VERSION ""

NS_ :

BS_:

BU_:

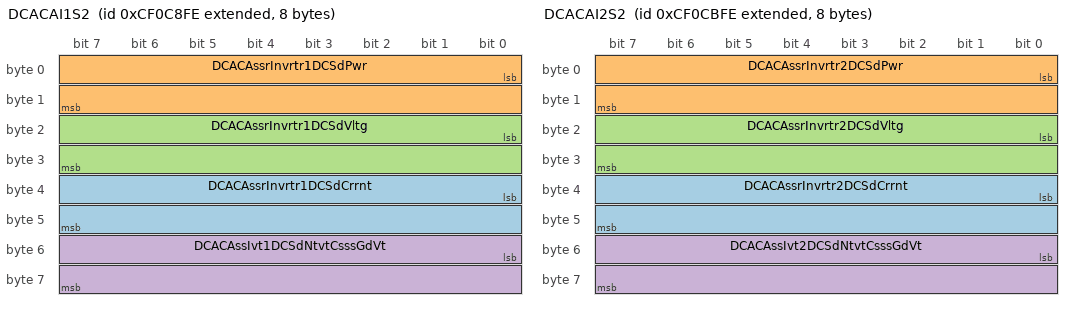
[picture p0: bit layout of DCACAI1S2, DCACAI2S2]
BO_ 2364590334 DCACAI1S2: 8 Vector__XXX
 SG_ DCACAssrInvrtr1DCSdCrrnt : 32|16@1+ (0.0625,0) [0|4015.9375] "A" Vector__XXX
 SG_ DCACAssrInvrtr1DCSdPwr : 0|16@1+ (0.0625,0) [0|4015.9375] "kW" Vector__XXX
 SG_ DCACAssrInvrtr1DCSdVltg : 16|16@1+ (0.05,0) [0|3212.75] "V" Vector__XXX
 SG_ DCACAssIvt1DCSdNtvtCsssGdVt : 48|16@1+ (0.05,0) [0|3212.75] "V" Vector__XXX

BO_ 2364590590 DCACAI1V: 8 Vector__XXX
 SG_ DCACAssrInvrtr1IgntnVltg : 0|16@1+ (0.05,0) [0|3212.75] "V" Vector__XXX
 SG_ DCACAssrInvrtr1SLIVltg : 16|16@1+ (0.05,0) [0|3212.75] "V" Vector__XXX

BO_ 2364591102 DCACAI2S2: 8 Vector__XXX
 SG_ DCACAssrInvrtr2DCSdCrrnt : 32|16@1+ (0.0625,0) [0|4015.9375] "A" Vector__XXX
 SG_ DCACAssrInvrtr2DCSdPwr : 0|16@1+ (0.0625,0) [0|4015.9375] "kW" Vector__XXX
 SG_ DCACAssrInvrtr2DCSdVltg : 16|16@1+ (0.05,0) [0|3212.75] "V" Vector__XXX
 SG_ DCACAssIvt2DCSdNtvtCsssGdVt : 48|16@1+ (0.05,0) [0|3212.75] "V" Vector__XXX

BO_ 2364591358 DCACAI2V: 8 Vector__XXX
 SG_ DCACAssrInvrtr2IgntnVltg : 0|16@1+ (0.05,0) [0|3212.75] "V" Vector__XXX
 SG_ DCACAssrInvrtr2SLIVltg : 16|16@1+ (0.05,0) [0|3212.75] "V" Vector__XXX

BO_ 2364592382 ECCR: 8 Vector__XXX
 SG_ EngnClndr10ExldfrmCmstnRqst : 26|2@1+ (1,0) [0|3] "" Vector__XXX
 SG_ EngnClndr11ExldfrmCmstnRqst : 28|2@1+ (1,0) [0|3] "" Vector__XXX
 SG_ EngnClndr12ExldfrmCmstnRqst : 30|2@1+ (1,0) [0|3] "" Vector__XXX
 SG_ EngnClndr13ExldfrmCmstnRqst : 32|2@1+ (1,0) [0|3] "" Vector__XXX
 SG_ EngnClndr14ExldfrmCmstnRqst : 34|2@1+ (1,0) [0|3] "" Vector__XXX
 SG_ EngnClndr15ExldfrmCmstnRqst : 36|2@1+ (1,0) [0|3] "" Vector__XXX
 SG_ EngnClndr16ExldfrmCmstnRqst : 38|2@1+ (1,0) [0|3] "" Vector__XXX
 SG_ EngnClndr17ExldfrmCmstnRqst : 40|2@1+ (1,0) [0|3] "" Vector__XXX
 SG_ EngnClndr18ExldfrmCmstnRqst : 42|2@1+ (1,0) [0|3] "" Vector__XXX
 SG_ EngnClndr19ExldfrmCmstnRqst : 44|2@1+ (1,0) [0|3] "" Vector__XXX
 SG_ EngnClndr1ExldfrmCmstnRqst : 8|2@1+ (1,0) [0|3] "" Vector__XXX
 SG_ EngnClndr20ExldfrmCmstnRqst : 46|2@1+ (1,0) [0|3] "" Vector__XXX
 SG_ EngnClndr21ExldfrmCmstnRqst : 48|2@1+ (1,0) [0|3] "" Vector__XXX
 SG_ EngnClndr22ExldfrmCmstnRqst : 50|2@1+ (1,0) [0|3] "" Vector__XXX
 SG_ EngnClndr23ExldfrmCmstnRqst : 52|2@1+ (1,0) [0|3] "" Vector__XXX
 SG_ EngnClndr24ExldfrmCmstnRqst : 54|2@1+ (1,0) [0|3] "" Vector__XXX
 SG_ EngnClndr2ExldfrmCmstnRqst : 10|2@1+ (1,0) [0|3] "" Vector__XXX
 SG_ EngnClndr3ExldfrmCmstnRqst : 12|2@1+ (1,0) [0|3] "" Vector__XXX
 SG_ EngnClndr4ExldfrmCmstnRqst : 14|2@1+ (1,0) [0|3] "" Vector__XXX
 SG_ EngnClndr5ExldfrmCmstnRqst : 16|2@1+ (1,0) [0|3] "" Vector__XXX
 SG_ EngnClndr6ExldfrmCmstnRqst : 18|2@1+ (1,0) [0|3] "" Vector__XXX
 SG_ EngnClndr7ExldfrmCmstnRqst : 20|2@1+ (1,0) [0|3] "" Vector__XXX
 SG_ EngnClndr8ExldfrmCmstnRqst : 22|2@1+ (1,0) [0|3] "" Vector__XXX
 SG_ EngnClndr9ExldfrmCmstnRqst : 24|2@1+ (1,0) [0|3] "" Vector__XXX
 SG_ NmrfEngnClndrstExldfrmCmstn : 0|8@1+ (1,0) [0|250] "count" Vector__XXX

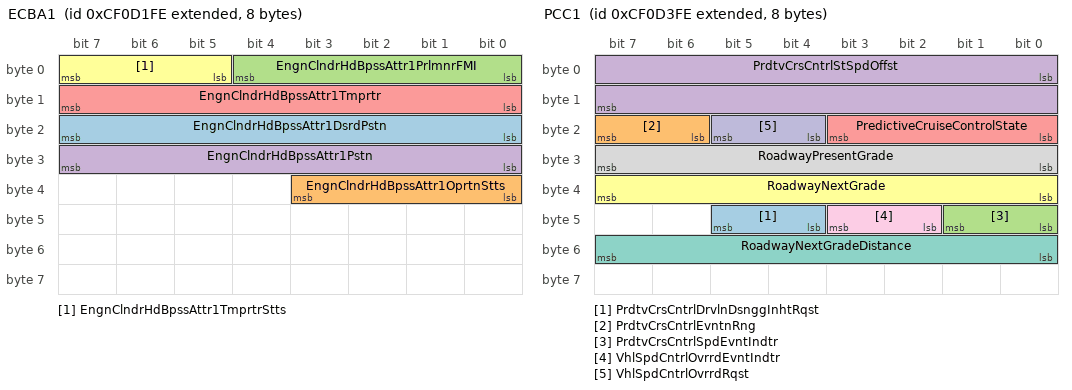
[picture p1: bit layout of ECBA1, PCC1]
BO_ 2364592638 ECBA1: 8 Vector__XXX
 SG_ EngnClndrHdBpssAttr1DsrdPstn : 16|8@1+ (0.4,0) [0|100] "%" Vector__XXX
 SG_ EngnClndrHdBpssAttr1OprtnStts : 32|4@1+ (1,0) [0|15] "" Vector__XXX
 SG_ EngnClndrHdBpssAttr1PrlmnrFMI : 0|5@1+ (1,0) [0|31] "binary" Vector__XXX
 SG_ EngnClndrHdBpssAttr1Pstn : 24|8@1+ (0.4,0) [0|100] "%" Vector__XXX
 SG_ EngnClndrHdBpssAttr1Tmprtr : 8|8@1+ (1,-40) [-40|210] "degC" Vector__XXX
 SG_ EngnClndrHdBpssAttr1TmprtrStts : 5|3@1+ (1,0) [0|7] "" Vector__XXX

BO_ 2364592894 EEC18: 8 Vector__XXX
 SG_ EngineIntakeAirSourceValve : 16|2@1+ (1,0) [0|3] "" Vector__XXX
 SG_ EngnClndrHdBpssAttr1Cmmnd : 0|16@1+ (0.0025,0) [0|160.6375] "%" Vector__XXX
 SG_ EngnExhstGsRstrtnVlvPstn : 32|16@1+ (0.0025,0) [0|160.6375] "%" Vector__XXX

BO_ 2364593150 PCC1: 8 Vector__XXX
 SG_ PrdtvCrsCntrlDrvlnDsnggInhtRqst : 44|2@1+ (1,0) [0|3] "" Vector__XXX
 SG_ PrdtvCrsCntrlEvntnRng : 22|2@1+ (1,0) [0|3] "" Vector__XXX
 SG_ PrdtvCrsCntrlSpdEvntIndtr : 40|2@1+ (1,0) [0|3] "" Vector__XXX
 SG_ PrdtvCrsCntrlStSpdOffst : 0|16@1+ (0.00390625,-125) [-125|125.996] "km/h" Vector__XXX
 SG_ PredictiveCruiseControlState : 16|4@1+ (1,0) [0|15] "" Vector__XXX
 SG_ RoadwayNextGrade : 32|8@1+ (0.125,-16) [-16|15.25] "%" Vector__XXX
 SG_ RoadwayNextGradeDistance : 48|8@1+ (25,0) [0|6250] "m" Vector__XXX
 SG_ RoadwayPresentGrade : 24|8@1+ (0.125,-16) [-16|15.25] "%" Vector__XXX
 SG_ VhlSpdCntrlOvrrdEvntIndtr : 42|2@1+ (1,0) [0|3] "" Vector__XXX
 SG_ VhlSpdCntrlOvrrdRqst : 20|2@1+ (1,0) [0|3] "" Vector__XXX

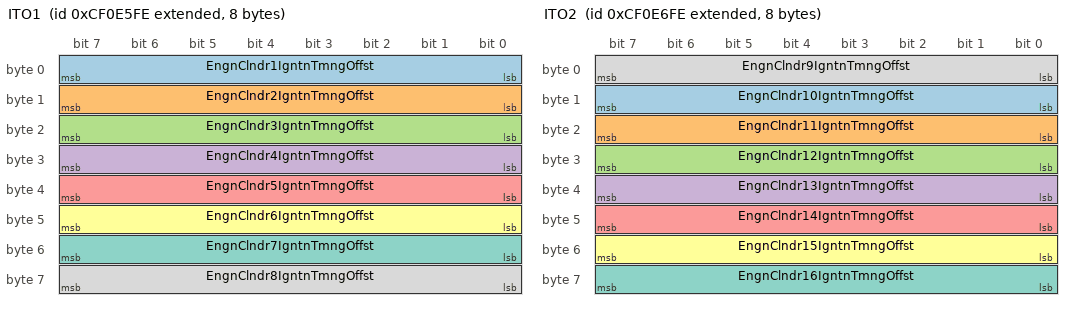
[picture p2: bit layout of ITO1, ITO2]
BO_ 2364597758 ITO1: 8 Vector__XXX
 SG_ EngnClndr1IgntnTmngOffst : 0|8@1+ (0.1,-12.5) [-12.5|12.5] "deg" Vector__XXX
 SG_ EngnClndr2IgntnTmngOffst : 8|8@1+ (0.1,-12.5) [-12.5|12.5] "deg" Vector__XXX
 SG_ EngnClndr3IgntnTmngOffst : 16|8@1+ (0.1,-12.5) [-12.5|12.5] "deg" Vector__XXX
 SG_ EngnClndr4IgntnTmngOffst : 24|8@1+ (0.1,-12.5) [-12.5|12.5] "deg" Vector__XXX
 SG_ EngnClndr5IgntnTmngOffst : 32|8@1+ (0.1,-12.5) [-12.5|12.5] "deg" Vector__XXX
 SG_ EngnClndr6IgntnTmngOffst : 40|8@1+ (0.1,-12.5) [-12.5|12.5] "deg" Vector__XXX
 SG_ EngnClndr7IgntnTmngOffst : 48|8@1+ (0.1,-12.5) [-12.5|12.5] "deg" Vector__XXX
 SG_ EngnClndr8IgntnTmngOffst : 56|8@1+ (0.1,-12.5) [-12.5|12.5] "deg" Vector__XXX

BO_ 2364598014 ITO2: 8 Vector__XXX
 SG_ EngnClndr10IgntnTmngOffst : 8|8@1+ (0.1,-12.5) [-12.5|12.5] "deg" Vector__XXX
 SG_ EngnClndr11IgntnTmngOffst : 16|8@1+ (0.1,-12.5) [-12.5|12.5] "deg" Vector__XXX
 SG_ EngnClndr12IgntnTmngOffst : 24|8@1+ (0.1,-12.5) [-12.5|12.5] "deg" Vector__XXX
 SG_ EngnClndr13IgntnTmngOffst : 32|8@1+ (0.1,-12.5) [-12.5|12.5] "deg" Vector__XXX
 SG_ EngnClndr14IgntnTmngOffst : 40|8@1+ (0.1,-12.5) [-12.5|12.5] "deg" Vector__XXX
 SG_ EngnClndr15IgntnTmngOffst : 48|8@1+ (0.1,-12.5) [-12.5|12.5] "deg" Vector__XXX
 SG_ EngnClndr16IgntnTmngOffst : 56|8@1+ (0.1,-12.5) [-12.5|12.5] "deg" Vector__XXX
 SG_ EngnClndr9IgntnTmngOffst : 0|8@1+ (0.1,-12.5) [-12.5|12.5] "deg" Vector__XXX

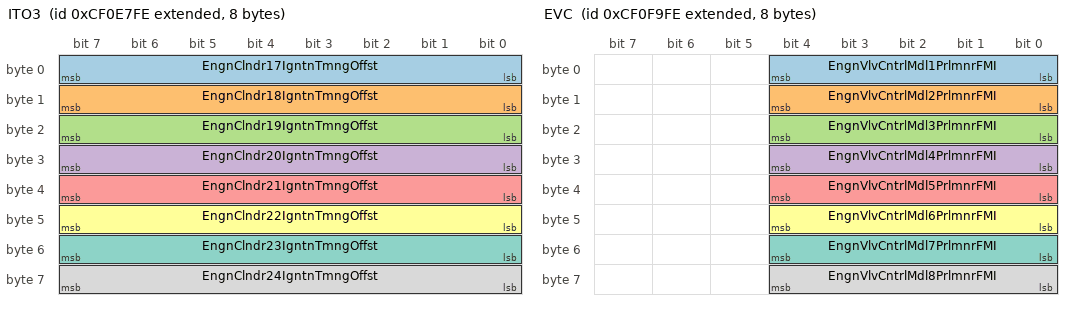
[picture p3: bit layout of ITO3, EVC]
BO_ 2364598270 ITO3: 8 Vector__XXX
 SG_ EngnClndr17IgntnTmngOffst : 0|8@1+ (0.1,-12.5) [-12.5|12.5] "deg" Vector__XXX
 SG_ EngnClndr18IgntnTmngOffst : 8|8@1+ (0.1,-12.5) [-12.5|12.5] "deg" Vector__XXX
 SG_ EngnClndr19IgntnTmngOffst : 16|8@1+ (0.1,-12.5) [-12.5|12.5] "deg" Vector__XXX
 SG_ EngnClndr20IgntnTmngOffst : 24|8@1+ (0.1,-12.5) [-12.5|12.5] "deg" Vector__XXX
 SG_ EngnClndr21IgntnTmngOffst : 32|8@1+ (0.1,-12.5) [-12.5|12.5] "deg" Vector__XXX
 SG_ EngnClndr22IgntnTmngOffst : 40|8@1+ (0.1,-12.5) [-12.5|12.5] "deg" Vector__XXX
 SG_ EngnClndr23IgntnTmngOffst : 48|8@1+ (0.1,-12.5) [-12.5|12.5] "deg" Vector__XXX
 SG_ EngnClndr24IgntnTmngOffst : 56|8@1+ (0.1,-12.5) [-12.5|12.5] "deg" Vector__XXX

BO_ 2364598526 TFAC2: 8 Vector__XXX
 SG_ EngnFlAttr3CntrlCmmnd : 32|16@1+ (0.0025,0) [0|160.6375] "%" Vector__XXX
 SG_ EngnFlAttr4CntrlCmmnd : 48|16@1+ (0.0025,0) [0|160.6375] "%" Vector__XXX

BO_ 2364602878 EVC: 8 Vector__XXX
 SG_ EngnVlvCntrlMdl1PrlmnrFMI : 0|5@1+ (1,0) [0|31] "binary" Vector__XXX
 SG_ EngnVlvCntrlMdl2PrlmnrFMI : 8|5@1+ (1,0) [0|31] "binary" Vector__XXX
 SG_ EngnVlvCntrlMdl3PrlmnrFMI : 16|5@1+ (1,0) [0|31] "binary" Vector__XXX
 SG_ EngnVlvCntrlMdl4PrlmnrFMI : 24|5@1+ (1,0) [0|31] "binary" Vector__XXX
 SG_ EngnVlvCntrlMdl5PrlmnrFMI : 32|5@1+ (1,0) [0|31] "binary" Vector__XXX
 SG_ EngnVlvCntrlMdl6PrlmnrFMI : 40|5@1+ (1,0) [0|31] "binary" Vector__XXX
 SG_ EngnVlvCntrlMdl7PrlmnrFMI : 48|5@1+ (1,0) [0|31] "binary" Vector__XXX
 SG_ EngnVlvCntrlMdl8PrlmnrFMI : 56|5@1+ (1,0) [0|31] "binary" Vector__XXX

BO_ 2364603134 ETC13: 8 Vector__XXX
 SG_ MxmmFrwrdTrnsmssnOtptShftSpd : 0|16@1+ (0.125,0) [0|8031.875] "rpm" Vector__XXX
 SG_ MxmmRvrsTrnsmssnOtptShftSpd : 16|16@1+ (0.125,0) [0|8031.875] "rpm" Vector__XXX
 SG_ SAddssAtvPdTsssRqstdG : 32|8@1+ (1,0) [0|255] "SA" Vector__XXX

BO_ 2364603390 A1SCRDSR3: 8 Vector__XXX
 SG_ Atttt1DsExstFdDsVv1Cd : 16|16@1+ (0.0025,0) [0|160.6375] "%" Vector__XXX
 SG_ Atttt1DsExstFdRqstdQttIttHRst : 0|16@1+ (0.001,0) [0|64.255] "g" Vector__XXX

BO_ 2364603646 A2SCRDSR3: 8 Vector__XXX
 SG_ Atttt2DsExstFdRqstdQttIttHRst : 0|16@1+ (0.001,0) [0|64.255] "g" Vector__XXX

BO_ 2364603902 A1SCRDSI4: 8 Vector__XXX
 SG_ Atttt1DsExstFdAtQttIttHRst : 0|16@1+ (0.001,0) [0|64.255] "g" Vector__XXX

BO_ 2364604158 A2SCRDSI4: 8 Vector__XXX
 SG_ Atttt2DsExstFdAtQttIttHRst : 0|16@1+ (0.001,0) [0|64.255] "g" Vector__XXX

BO_ 2364605438 GTRACE: 8 Vector__XXX
 SG_ GeneratorTripkVArHoursExport : 32|32@1+ (1,0) [0|4.21108E+09] "kVArh" Vector__XXX
 SG_ GeneratorTripkWHoursExport : 0|32@1+ (1,0) [0|4.21108E+09] "kWh" Vector__XXX

BO_ 2364605950 HPD: 8 Vector__XXX
 SG_ HydraulicLinePressure : 0|16@1+ (1,0) [0|64255] "kPa" Vector__XXX
 SG_ MechanicalMovementAngle : 16|16@1+ (0.0078125,0) [0|501.99] "deg" Vector__XXX

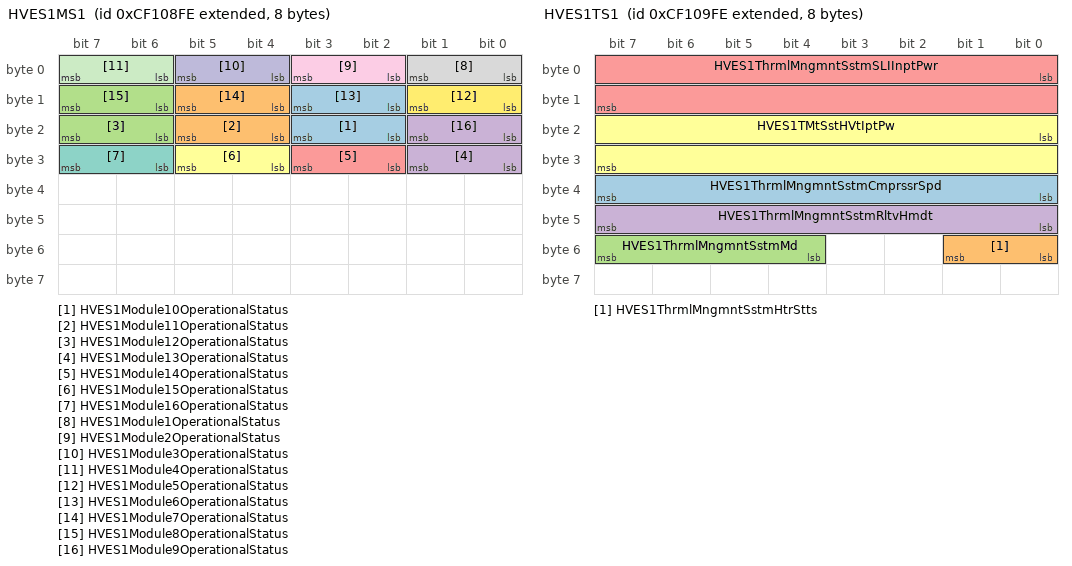
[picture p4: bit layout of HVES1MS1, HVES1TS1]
BO_ 2364606718 HVES1MS1: 8 Vector__XXX
 SG_ HVES1Module10OperationalStatus : 18|2@1+ (1,0) [0|3] "" Vector__XXX
 SG_ HVES1Module11OperationalStatus : 20|2@1+ (1,0) [0|3] "" Vector__XXX
 SG_ HVES1Module12OperationalStatus : 22|2@1+ (1,0) [0|3] "" Vector__XXX
 SG_ HVES1Module13OperationalStatus : 24|2@1+ (1,0) [0|3] "" Vector__XXX
 SG_ HVES1Module14OperationalStatus : 26|2@1+ (1,0) [0|3] "" Vector__XXX
 SG_ HVES1Module15OperationalStatus : 28|2@1+ (1,0) [0|3] "" Vector__XXX
 SG_ HVES1Module16OperationalStatus : 30|2@1+ (1,0) [0|3] "" Vector__XXX
 SG_ HVES1Module1OperationalStatus : 0|2@1+ (1,0) [0|3] "" Vector__XXX
 SG_ HVES1Module2OperationalStatus : 2|2@1+ (1,0) [0|3] "" Vector__XXX
 SG_ HVES1Module3OperationalStatus : 4|2@1+ (1,0) [0|3] "" Vector__XXX
 SG_ HVES1Module4OperationalStatus : 6|2@1+ (1,0) [0|3] "" Vector__XXX
 SG_ HVES1Module5OperationalStatus : 8|2@1+ (1,0) [0|3] "" Vector__XXX
 SG_ HVES1Module6OperationalStatus : 10|2@1+ (1,0) [0|3] "" Vector__XXX
 SG_ HVES1Module7OperationalStatus : 12|2@1+ (1,0) [0|3] "" Vector__XXX
 SG_ HVES1Module8OperationalStatus : 14|2@1+ (1,0) [0|3] "" Vector__XXX
 SG_ HVES1Module9OperationalStatus : 16|2@1+ (1,0) [0|3] "" Vector__XXX

BO_ 2364606974 HVES1TS1: 8 Vector__XXX
 SG_ HVES1ThrmlMngmntSstmCmprssrSpd : 32|8@1+ (32,0) [0|8000] "rpm" Vector__XXX
 SG_ HVES1ThrmlMngmntSstmHtrStts : 48|2@1+ (1,0) [0|3] "" Vector__XXX
 SG_ HVES1ThrmlMngmntSstmMd : 52|4@1+ (1,0) [0|15] "" Vector__XXX
 SG_ HVES1ThrmlMngmntSstmRltvHmdt : 40|8@1+ (0.4,0) [0|100] "%" Vector__XXX
 SG_ HVES1ThrmlMngmntSstmSLIInptPwr : 0|16@1+ (0.5,0) [0|32127.5] "W" Vector__XXX
 SG_ HVES1TMtSstHVtIptPw : 16|16@1+ (0.5,0) [0|32127.5] "W" Vector__XXX

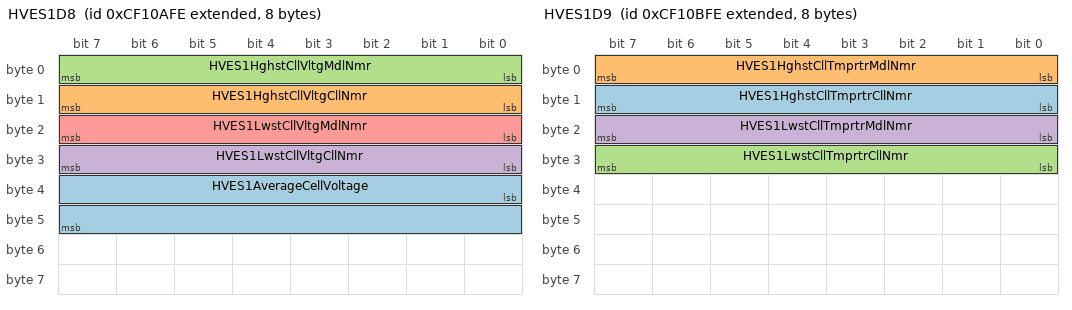
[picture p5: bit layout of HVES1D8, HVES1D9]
BO_ 2364607230 HVES1D8: 8 Vector__XXX
 SG_ HVES1AverageCellVoltage : 32|16@1+ (0.001,0) [0|64.255] "V" Vector__XXX
 SG_ HVES1HghstCllVltgCllNmr : 8|8@1+ (1,0) [0|250] "count" Vector__XXX
 SG_ HVES1HghstCllVltgMdlNmr : 0|8@1+ (1,0) [0|250] "count" Vector__XXX
 SG_ HVES1LwstCllVltgCllNmr : 24|8@1+ (1,0) [0|250] "count" Vector__XXX
 SG_ HVES1LwstCllVltgMdlNmr : 16|8@1+ (1,0) [0|250] "count" Vector__XXX

BO_ 2364607486 HVES1D9: 8 Vector__XXX
 SG_ HVES1HghstCllTmprtrCllNmr : 8|8@1+ (1,0) [0|250] "count" Vector__XXX
 SG_ HVES1HghstCllTmprtrMdlNmr : 0|8@1+ (1,0) [0|250] "count" Vector__XXX
 SG_ HVES1LwstCllTmprtrCllNmr : 24|8@1+ (1,0) [0|250] "count" Vector__XXX
 SG_ HVES1LwstCllTmprtrMdlNmr : 16|8@1+ (1,0) [0|250] "count" Vector__XXX

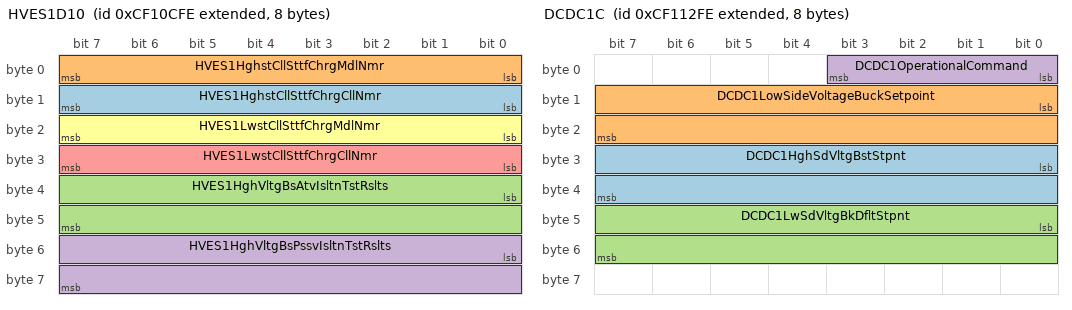
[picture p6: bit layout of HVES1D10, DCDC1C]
BO_ 2364607742 HVES1D10: 8 Vector__XXX
 SG_ HVES1HghstCllSttfChrgCllNmr : 8|8@1+ (1,0) [0|250] "count" Vector__XXX
 SG_ HVES1HghstCllSttfChrgMdlNmr : 0|8@1+ (1,0) [0|250] "count" Vector__XXX
 SG_ HVES1HghVltgBsAtvIsltnTstRslts : 32|16@1+ (0.1,0) [0|6425.5] "ohm/V" Vector__XXX
 SG_ HVES1HghVltgBsPssvIsltnTstRslts : 48|16@1+ (0.1,0) [0|6425.5] "ohm/V" Vector__XXX
 SG_ HVES1LwstCllSttfChrgCllNmr : 24|8@1+ (1,0) [0|250] "count" Vector__XXX
 SG_ HVES1LwstCllSttfChrgMdlNmr : 16|8@1+ (1,0) [0|250] "count" Vector__XXX

BO_ 2364608510 EOI2: 8 Vector__XXX
 SG_ EnginePowerDerateRequest : 16|16@1+ (0.5,0) [0|32127.5] "kW" Vector__XXX
 SG_ EngineSelfInducedDerateLoad : 0|16@1+ (0.5,0) [0|32127.5] "kW" Vector__XXX

BO_ 2364609278 DCDC1C: 8 Vector__XXX
 SG_ DCDC1HghSdVltgBstStpnt : 24|16@1+ (0.05,0) [0|3212.75] "V" Vector__XXX
 SG_ DCDC1LowSideVoltageBuckSetpoint : 8|16@1+ (0.01,0) [0|642.55] "V" Vector__XXX
 SG_ DCDC1LwSdVltgBkDfltStpnt : 40|16@1+ (0.01,0) [0|642.55] "V" Vector__XXX
 SG_ DCDC1OperationalCommand : 0|4@1+ (1,0) [0|15] "" Vector__XXX

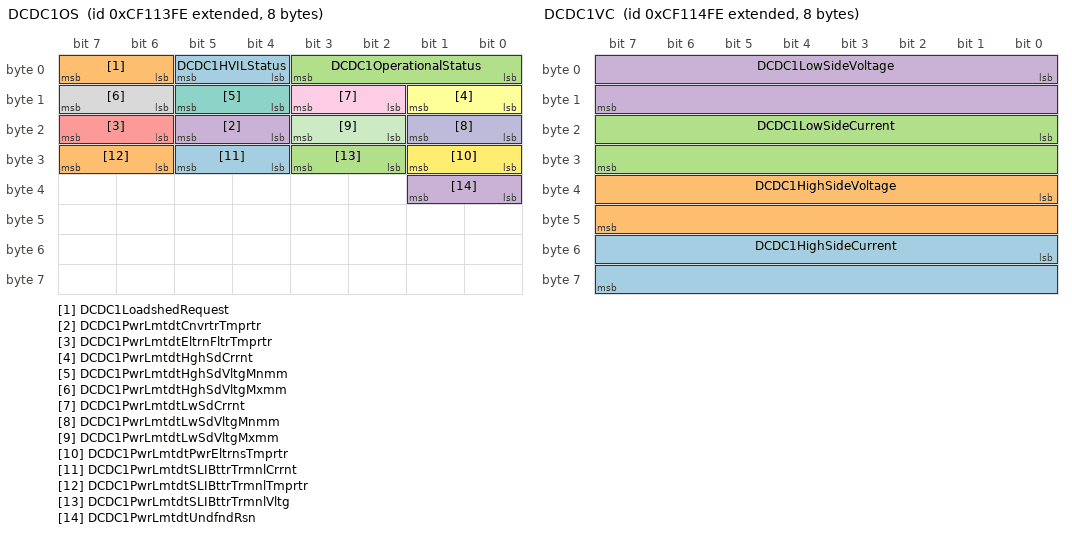
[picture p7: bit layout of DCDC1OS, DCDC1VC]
BO_ 2364609534 DCDC1OS: 8 Vector__XXX
 SG_ DCDC1HVILStatus : 4|2@1+ (1,0) [0|3] "" Vector__XXX
 SG_ DCDC1LoadshedRequest : 6|2@1+ (1,0) [0|3] "" Vector__XXX
 SG_ DCDC1OperationalStatus : 0|4@1+ (1,0) [0|15] "" Vector__XXX
 SG_ DCDC1PwrLmtdtCnvrtrTmprtr : 20|2@1+ (1,0) [0|3] "" Vector__XXX
 SG_ DCDC1PwrLmtdtEltrnFltrTmprtr : 22|2@1+ (1,0) [0|3] "" Vector__XXX
 SG_ DCDC1PwrLmtdtHghSdCrrnt : 8|2@1+ (1,0) [0|3] "" Vector__XXX
 SG_ DCDC1PwrLmtdtHghSdVltgMnmm : 12|2@1+ (1,0) [0|3] "" Vector__XXX
 SG_ DCDC1PwrLmtdtHghSdVltgMxmm : 14|2@1+ (1,0) [0|3] "" Vector__XXX
 SG_ DCDC1PwrLmtdtLwSdCrrnt : 10|2@1+ (1,0) [0|3] "" Vector__XXX
 SG_ DCDC1PwrLmtdtLwSdVltgMnmm : 16|2@1+ (1,0) [0|3] "" Vector__XXX
 SG_ DCDC1PwrLmtdtLwSdVltgMxmm : 18|2@1+ (1,0) [0|3] "" Vector__XXX
 SG_ DCDC1PwrLmtdtPwrEltrnsTmprtr : 24|2@1+ (1,0) [0|3] "" Vector__XXX
 SG_ DCDC1PwrLmtdtSLIBttrTrmnlCrrnt : 28|2@1+ (1,0) [0|3] "" Vector__XXX
 SG_ DCDC1PwrLmtdtSLIBttrTrmnlTmprtr : 30|2@1+ (1,0) [0|3] "" Vector__XXX
 SG_ DCDC1PwrLmtdtSLIBttrTrmnlVltg : 26|2@1+ (1,0) [0|3] "" Vector__XXX
 SG_ DCDC1PwrLmtdtUndfndRsn : 32|2@1+ (1,0) [0|3] "" Vector__XXX

BO_ 2364609790 DCDC1VC: 8 Vector__XXX
 SG_ DCDC1HighSideCurrent : 48|16@1+ (0.1,-3212.7) [-3212.7|3212.8] "A" Vector__XXX
 SG_ DCDC1HighSideVoltage : 32|16@1+ (0.05,0) [0|3212.75] "V" Vector__XXX
 SG_ DCDC1LowSideCurrent : 16|16@1+ (0.1,-3212.7) [-3212.7|3212.8] "A" Vector__XXX
 SG_ DCDC1LowSideVoltage : 0|16@1+ (0.01,0) [0|642.55] "V" Vector__XXX

BO_ 2364610046 DCDC1SBS: 8 Vector__XXX
 SG_ DCDC1SLIBatteryTerminalCurrent : 16|16@1+ (0.1,-3212.7) [-3212.7|3212.8] "A" Vector__XXX
 SG_ DCDC1SLIBatteryTerminalVoltage : 0|16@1+ (0.01,0) [0|642.55] "V" Vector__XXX
 SG_ DCDC1SLIBttrTrmnlTmprtr : 32|8@1+ (1,-40) [-40|210] "degC" Vector__XXX

BO_ 2364610558 DCDC1S2: 8 Vector__XXX
 SG_ DCDC1HighSidePower : 16|16@1+ (0.05,-1600) [-1600|1612.75] "kW" Vector__XXX
 SG_ DCDC1LowSidePower : 0|16@1+ (0.05,-1600) [-1600|1612.75] "kW" Vector__XXX
 SG_ DCDC1HghSdNgtvtChsssGrndVltg : 32|16@1+ (0.05,0) [0|3212.75] "V" Vector__XXX

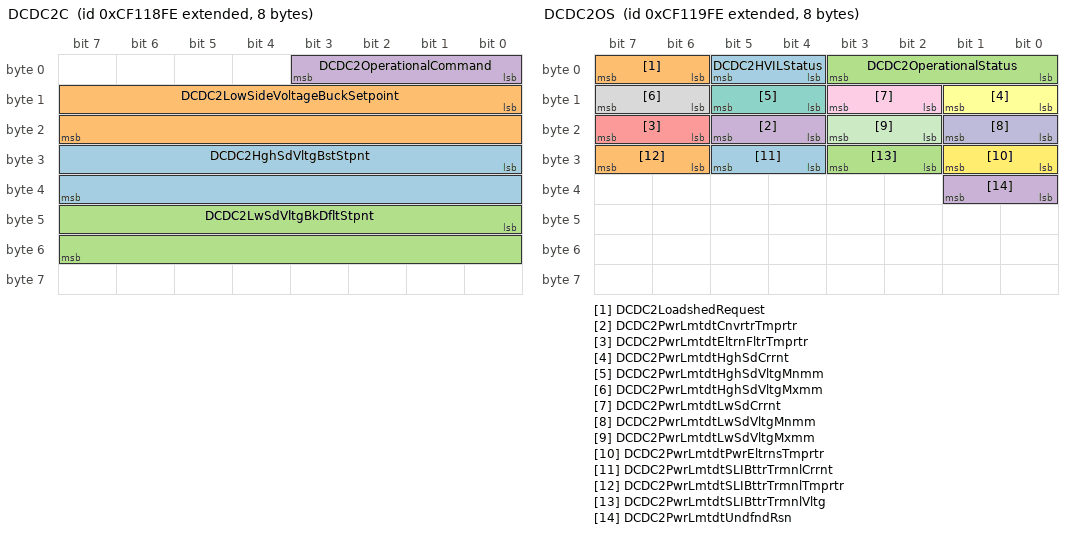
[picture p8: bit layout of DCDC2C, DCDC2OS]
BO_ 2364610814 DCDC2C: 8 Vector__XXX
 SG_ DCDC2HghSdVltgBstStpnt : 24|16@1+ (0.05,0) [0|3212.75] "V" Vector__XXX
 SG_ DCDC2LowSideVoltageBuckSetpoint : 8|16@1+ (0.01,0) [0|642.55] "V" Vector__XXX
 SG_ DCDC2LwSdVltgBkDfltStpnt : 40|16@1+ (0.01,0) [0|642.55] "V" Vector__XXX
 SG_ DCDC2OperationalCommand : 0|4@1+ (1,0) [0|15] "" Vector__XXX

BO_ 2364611070 DCDC2OS: 8 Vector__XXX
 SG_ DCDC2HVILStatus : 4|2@1+ (1,0) [0|3] "" Vector__XXX
 SG_ DCDC2LoadshedRequest : 6|2@1+ (1,0) [0|3] "" Vector__XXX
 SG_ DCDC2OperationalStatus : 0|4@1+ (1,0) [0|15] "" Vector__XXX
 SG_ DCDC2PwrLmtdtCnvrtrTmprtr : 20|2@1+ (1,0) [0|3] "" Vector__XXX
 SG_ DCDC2PwrLmtdtEltrnFltrTmprtr : 22|2@1+ (1,0) [0|3] "" Vector__XXX
 SG_ DCDC2PwrLmtdtHghSdCrrnt : 8|2@1+ (1,0) [0|3] "" Vector__XXX
 SG_ DCDC2PwrLmtdtHghSdVltgMnmm : 12|2@1+ (1,0) [0|3] "" Vector__XXX
 SG_ DCDC2PwrLmtdtHghSdVltgMxmm : 14|2@1+ (1,0) [0|3] "" Vector__XXX
 SG_ DCDC2PwrLmtdtLwSdCrrnt : 10|2@1+ (1,0) [0|3] "" Vector__XXX
 SG_ DCDC2PwrLmtdtLwSdVltgMnmm : 16|2@1+ (1,0) [0|3] "" Vector__XXX
 SG_ DCDC2PwrLmtdtLwSdVltgMxmm : 18|2@1+ (1,0) [0|3] "" Vector__XXX
 SG_ DCDC2PwrLmtdtPwrEltrnsTmprtr : 24|2@1+ (1,0) [0|3] "" Vector__XXX
 SG_ DCDC2PwrLmtdtSLIBttrTrmnlCrrnt : 28|2@1+ (1,0) [0|3] "" Vector__XXX
 SG_ DCDC2PwrLmtdtSLIBttrTrmnlTmprtr : 30|2@1+ (1,0) [0|3] "" Vector__XXX
 SG_ DCDC2PwrLmtdtSLIBttrTrmnlVltg : 26|2@1+ (1,0) [0|3] "" Vector__XXX
 SG_ DCDC2PwrLmtdtUndfndRsn : 32|2@1+ (1,0) [0|3] "" Vector__XXX

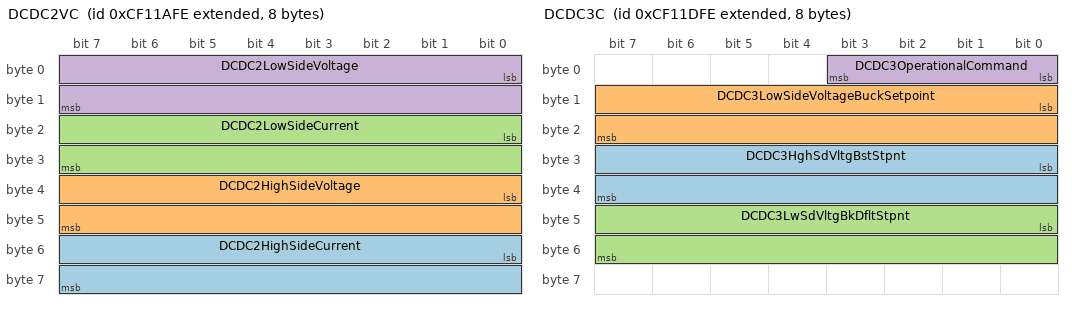
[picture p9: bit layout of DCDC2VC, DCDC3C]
BO_ 2364611326 DCDC2VC: 8 Vector__XXX
 SG_ DCDC2HighSideCurrent : 48|16@1+ (0.1,-3212.7) [-3212.7|3212.8] "A" Vector__XXX
 SG_ DCDC2HighSideVoltage : 32|16@1+ (0.05,0) [0|3212.75] "V" Vector__XXX
 SG_ DCDC2LowSideCurrent : 16|16@1+ (0.1,-3212.7) [-3212.7|3212.8] "A" Vector__XXX
 SG_ DCDC2LowSideVoltage : 0|16@1+ (0.01,0) [0|642.55] "V" Vector__XXX

BO_ 2364611582 DCDC2SBS: 8 Vector__XXX
 SG_ DCDC2SLIBatteryTerminalCurrent : 16|16@1+ (0.1,-3212.7) [-3212.7|3212.8] "A" Vector__XXX
 SG_ DCDC2SLIBatteryTerminalVoltage : 0|16@1+ (0.01,0) [0|642.55] "V" Vector__XXX
 SG_ DCDC2SLIBttrTrmnlTmprtr : 32|8@1+ (1,-40) [-40|210] "degC" Vector__XXX

BO_ 2364611838 DCDC2S2: 8 Vector__XXX
 SG_ DCDC2HighSidePower : 16|16@1+ (0.05,-1600) [-1600|1612.75] "kW" Vector__XXX
 SG_ DCDC2LowSidePower : 0|16@1+ (0.05,-1600) [-1600|1612.75] "kW" Vector__XXX
 SG_ DCDC2HghSdNgtvtChsssGrndVltg : 32|16@1+ (0.05,0) [0|3212.75] "V" Vector__XXX

BO_ 2364612094 DCDC3C: 8 Vector__XXX
 SG_ DCDC3HghSdVltgBstStpnt : 24|16@1+ (0.05,0) [0|3212.75] "V" Vector__XXX
 SG_ DCDC3LowSideVoltageBuckSetpoint : 8|16@1+ (0.01,0) [0|642.55] "V" Vector__XXX
 SG_ DCDC3LwSdVltgBkDfltStpnt : 40|16@1+ (0.01,0) [0|642.55] "V" Vector__XXX
 SG_ DCDC3OperationalCommand : 0|4@1+ (1,0) [0|15] "" Vector__XXX

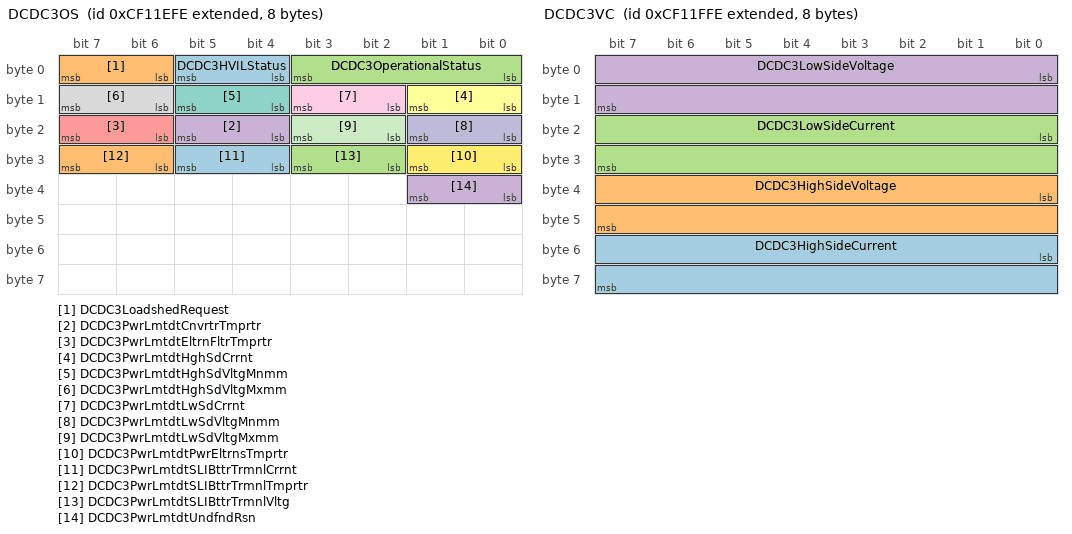
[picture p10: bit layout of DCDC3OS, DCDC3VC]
BO_ 2364612350 DCDC3OS: 8 Vector__XXX
 SG_ DCDC3HVILStatus : 4|2@1+ (1,0) [0|3] "" Vector__XXX
 SG_ DCDC3LoadshedRequest : 6|2@1+ (1,0) [0|3] "" Vector__XXX
 SG_ DCDC3OperationalStatus : 0|4@1+ (1,0) [0|15] "" Vector__XXX
 SG_ DCDC3PwrLmtdtCnvrtrTmprtr : 20|2@1+ (1,0) [0|3] "" Vector__XXX
 SG_ DCDC3PwrLmtdtEltrnFltrTmprtr : 22|2@1+ (1,0) [0|3] "" Vector__XXX
 SG_ DCDC3PwrLmtdtHghSdCrrnt : 8|2@1+ (1,0) [0|3] "" Vector__XXX
 SG_ DCDC3PwrLmtdtHghSdVltgMnmm : 12|2@1+ (1,0) [0|3] "" Vector__XXX
 SG_ DCDC3PwrLmtdtHghSdVltgMxmm : 14|2@1+ (1,0) [0|3] "" Vector__XXX
 SG_ DCDC3PwrLmtdtLwSdCrrnt : 10|2@1+ (1,0) [0|3] "" Vector__XXX
 SG_ DCDC3PwrLmtdtLwSdVltgMnmm : 16|2@1+ (1,0) [0|3] "" Vector__XXX
 SG_ DCDC3PwrLmtdtLwSdVltgMxmm : 18|2@1+ (1,0) [0|3] "" Vector__XXX
 SG_ DCDC3PwrLmtdtPwrEltrnsTmprtr : 24|2@1+ (1,0) [0|3] "" Vector__XXX
 SG_ DCDC3PwrLmtdtSLIBttrTrmnlCrrnt : 28|2@1+ (1,0) [0|3] "" Vector__XXX
 SG_ DCDC3PwrLmtdtSLIBttrTrmnlTmprtr : 30|2@1+ (1,0) [0|3] "" Vector__XXX
 SG_ DCDC3PwrLmtdtSLIBttrTrmnlVltg : 26|2@1+ (1,0) [0|3] "" Vector__XXX
 SG_ DCDC3PwrLmtdtUndfndRsn : 32|2@1+ (1,0) [0|3] "" Vector__XXX

BO_ 2364612606 DCDC3VC: 8 Vector__XXX
 SG_ DCDC3HighSideCurrent : 48|16@1+ (0.1,-3212.7) [-3212.7|3212.8] "A" Vector__XXX
 SG_ DCDC3HighSideVoltage : 32|16@1+ (0.05,0) [0|3212.75] "V" Vector__XXX
 SG_ DCDC3LowSideCurrent : 16|16@1+ (0.1,-3212.7) [-3212.7|3212.8] "A" Vector__XXX
 SG_ DCDC3LowSideVoltage : 0|16@1+ (0.01,0) [0|642.55] "V" Vector__XXX

BO_ 2364612862 DCDC3SBS: 8 Vector__XXX
 SG_ DCDC3SLIBatteryTerminalCurrent : 16|16@1+ (0.1,-3212.7) [-3212.7|3212.8] "A" Vector__XXX
 SG_ DCDC3SLIBatteryTerminalVoltage : 0|16@1+ (0.01,0) [0|642.55] "V" Vector__XXX
 SG_ DCDC3SLIBttrTrmnlTmprtr : 32|8@1+ (1,-40) [-40|210] "degC" Vector__XXX

BO_ 2364613118 DCDC3S2: 8 Vector__XXX
 SG_ DCDC3HighSidePower : 16|16@1+ (0.05,-1600) [-1600|1612.75] "kW" Vector__XXX
 SG_ DCDC3LowSidePower : 0|16@1+ (0.05,-1600) [-1600|1612.75] "kW" Vector__XXX
 SG_ DCDC3HghSdNgtvtChsssGrndVltg : 32|16@1+ (0.05,0) [0|3212.75] "V" Vector__XXX

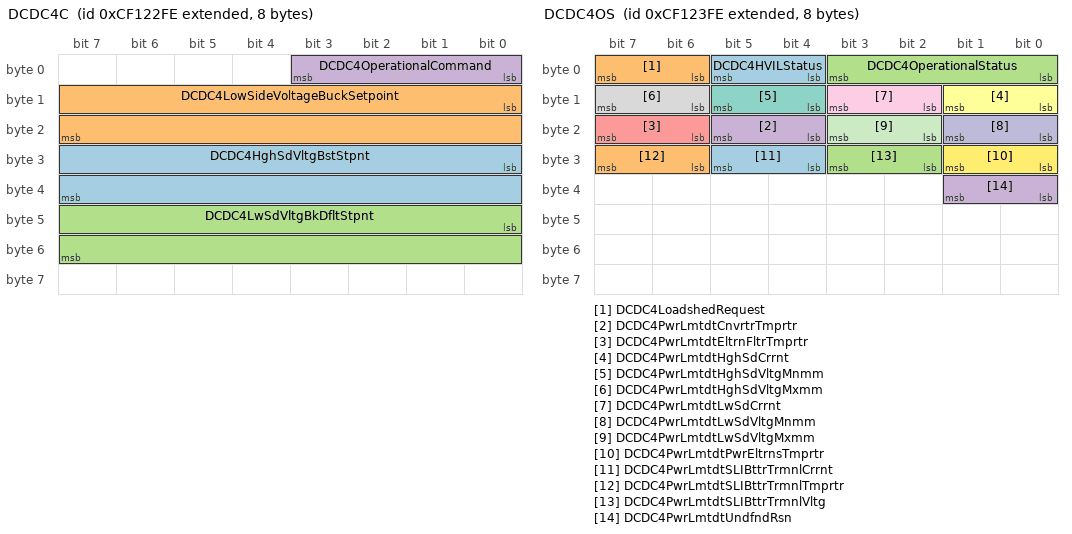
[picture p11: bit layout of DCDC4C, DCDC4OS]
BO_ 2364613374 DCDC4C: 8 Vector__XXX
 SG_ DCDC4HghSdVltgBstStpnt : 24|16@1+ (0.05,0) [0|3212.75] "V" Vector__XXX
 SG_ DCDC4LowSideVoltageBuckSetpoint : 8|16@1+ (0.01,0) [0|642.55] "V" Vector__XXX
 SG_ DCDC4LwSdVltgBkDfltStpnt : 40|16@1+ (0.01,0) [0|642.55] "V" Vector__XXX
 SG_ DCDC4OperationalCommand : 0|4@1+ (1,0) [0|15] "" Vector__XXX

BO_ 2364613630 DCDC4OS: 8 Vector__XXX
 SG_ DCDC4HVILStatus : 4|2@1+ (1,0) [0|3] "" Vector__XXX
 SG_ DCDC4LoadshedRequest : 6|2@1+ (1,0) [0|3] "" Vector__XXX
 SG_ DCDC4OperationalStatus : 0|4@1+ (1,0) [0|15] "" Vector__XXX
 SG_ DCDC4PwrLmtdtCnvrtrTmprtr : 20|2@1+ (1,0) [0|3] "" Vector__XXX
 SG_ DCDC4PwrLmtdtEltrnFltrTmprtr : 22|2@1+ (1,0) [0|3] "" Vector__XXX
 SG_ DCDC4PwrLmtdtHghSdCrrnt : 8|2@1+ (1,0) [0|3] "" Vector__XXX
 SG_ DCDC4PwrLmtdtHghSdVltgMnmm : 12|2@1+ (1,0) [0|3] "" Vector__XXX
 SG_ DCDC4PwrLmtdtHghSdVltgMxmm : 14|2@1+ (1,0) [0|3] "" Vector__XXX
 SG_ DCDC4PwrLmtdtLwSdCrrnt : 10|2@1+ (1,0) [0|3] "" Vector__XXX
 SG_ DCDC4PwrLmtdtLwSdVltgMnmm : 16|2@1+ (1,0) [0|3] "" Vector__XXX
 SG_ DCDC4PwrLmtdtLwSdVltgMxmm : 18|2@1+ (1,0) [0|3] "" Vector__XXX
 SG_ DCDC4PwrLmtdtPwrEltrnsTmprtr : 24|2@1+ (1,0) [0|3] "" Vector__XXX
 SG_ DCDC4PwrLmtdtSLIBttrTrmnlCrrnt : 28|2@1+ (1,0) [0|3] "" Vector__XXX
 SG_ DCDC4PwrLmtdtSLIBttrTrmnlTmprtr : 30|2@1+ (1,0) [0|3] "" Vector__XXX
 SG_ DCDC4PwrLmtdtSLIBttrTrmnlVltg : 26|2@1+ (1,0) [0|3] "" Vector__XXX
 SG_ DCDC4PwrLmtdtUndfndRsn : 32|2@1+ (1,0) [0|3] "" Vector__XXX

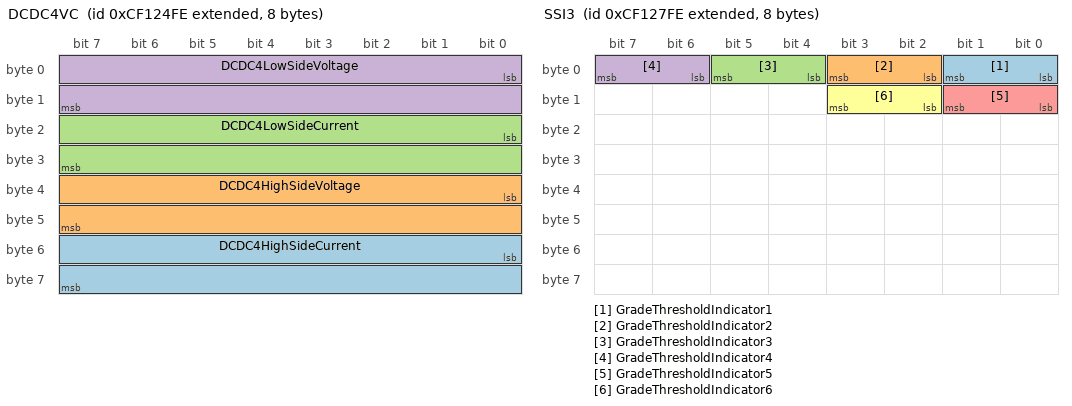
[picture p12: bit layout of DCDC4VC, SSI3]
BO_ 2364613886 DCDC4VC: 8 Vector__XXX
 SG_ DCDC4HighSideCurrent : 48|16@1+ (0.1,-3212.7) [-3212.7|3212.8] "A" Vector__XXX
 SG_ DCDC4HighSideVoltage : 32|16@1+ (0.05,0) [0|3212.75] "V" Vector__XXX
 SG_ DCDC4LowSideCurrent : 16|16@1+ (0.1,-3212.7) [-3212.7|3212.8] "A" Vector__XXX
 SG_ DCDC4LowSideVoltage : 0|16@1+ (0.01,0) [0|642.55] "V" Vector__XXX

BO_ 2364614142 DCDC4SBS: 8 Vector__XXX
 SG_ DCDC4SLIBatteryTerminalCurrent : 16|16@1+ (0.1,-3212.7) [-3212.7|3212.8] "A" Vector__XXX
 SG_ DCDC4SLIBatteryTerminalVoltage : 0|16@1+ (0.01,0) [0|642.55] "V" Vector__XXX
 SG_ DCDC4SLIBttrTrmnlTmprtr : 32|8@1+ (1,-40) [-40|210] "degC" Vector__XXX

BO_ 2364614398 DCDC4S2: 8 Vector__XXX
 SG_ DCDC4HighSidePower : 16|16@1+ (0.05,-1600) [-1600|1612.75] "kW" Vector__XXX
 SG_ DCDC4LowSidePower : 0|16@1+ (0.05,-1600) [-1600|1612.75] "kW" Vector__XXX
 SG_ DCDC4HghSdNgtvtChsssGrndVltg : 32|16@1+ (0.05,0) [0|3212.75] "V" Vector__XXX

BO_ 2364614654 SSI3: 8 Vector__XXX
 SG_ GradeThresholdIndicator1 : 0|2@1+ (1,0) [0|3] "" Vector__XXX
 SG_ GradeThresholdIndicator2 : 2|2@1+ (1,0) [0|3] "" Vector__XXX
 SG_ GradeThresholdIndicator3 : 4|2@1+ (1,0) [0|3] "" Vector__XXX
 SG_ GradeThresholdIndicator4 : 6|2@1+ (1,0) [0|3] "" Vector__XXX
 SG_ GradeThresholdIndicator5 : 8|2@1+ (1,0) [0|3] "" Vector__XXX
 SG_ GradeThresholdIndicator6 : 10|2@1+ (1,0) [0|3] "" Vector__XXX

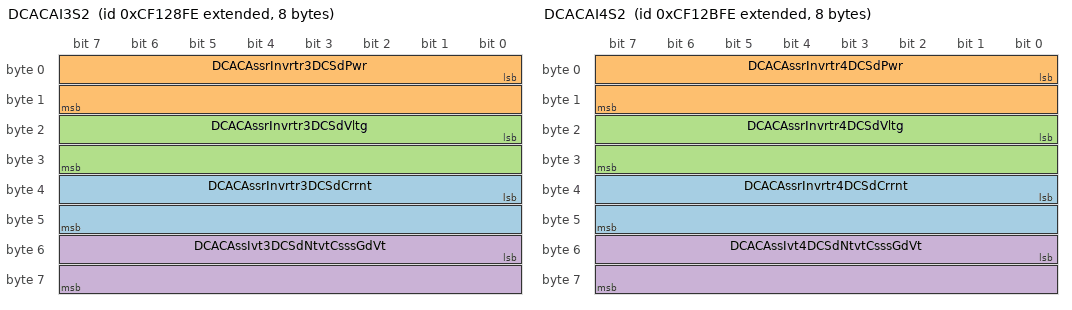
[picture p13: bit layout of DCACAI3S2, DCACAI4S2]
BO_ 2364614910 DCACAI3S2: 8 Vector__XXX
 SG_ DCACAssrInvrtr3DCSdCrrnt : 32|16@1+ (0.0625,0) [0|4015.9375] "A" Vector__XXX
 SG_ DCACAssrInvrtr3DCSdPwr : 0|16@1+ (0.0625,0) [0|4015.9375] "kW" Vector__XXX
 SG_ DCACAssrInvrtr3DCSdVltg : 16|16@1+ (0.05,0) [0|3212.75] "V" Vector__XXX
 SG_ DCACAssIvt3DCSdNtvtCsssGdVt : 48|16@1+ (0.05,0) [0|3212.75] "V" Vector__XXX

BO_ 2364615166 DCACAI3V: 8 Vector__XXX
 SG_ DCACAssrInvrtr3IgntnVltg : 0|16@1+ (0.05,0) [0|3212.75] "V" Vector__XXX
 SG_ DCACAssrInvrtr3SLIVltg : 16|16@1+ (0.05,0) [0|3212.75] "V" Vector__XXX

BO_ 2364615678 DCACAI4S2: 8 Vector__XXX
 SG_ DCACAssrInvrtr4DCSdCrrnt : 32|16@1+ (0.0625,0) [0|4015.9375] "A" Vector__XXX
 SG_ DCACAssrInvrtr4DCSdPwr : 0|16@1+ (0.0625,0) [0|4015.9375] "kW" Vector__XXX
 SG_ DCACAssrInvrtr4DCSdVltg : 16|16@1+ (0.05,0) [0|3212.75] "V" Vector__XXX
 SG_ DCACAssIvt4DCSdNtvtCsssGdVt : 48|16@1+ (0.05,0) [0|3212.75] "V" Vector__XXX

BO_ 2364615934 DCACAI4V: 8 Vector__XXX
 SG_ DCACAssrInvrtr4IgntnVltg : 0|16@1+ (0.05,0) [0|3212.75] "V" Vector__XXX
 SG_ DCACAssrInvrtr4SLIVltg : 16|16@1+ (0.05,0) [0|3212.75] "V" Vector__XXX

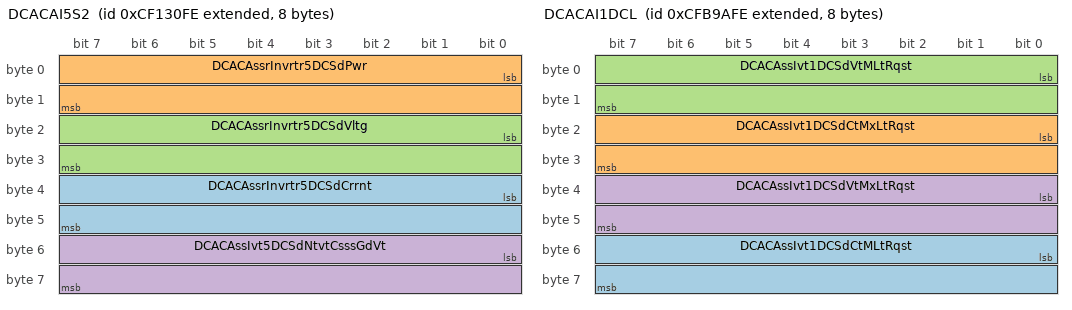
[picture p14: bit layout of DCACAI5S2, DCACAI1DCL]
BO_ 2364616958 DCACAI5S2: 8 Vector__XXX
 SG_ DCACAssrInvrtr5DCSdCrrnt : 32|16@1+ (0.0625,0) [0|4015.9375] "A" Vector__XXX
 SG_ DCACAssrInvrtr5DCSdPwr : 0|16@1+ (0.0625,0) [0|4015.9375] "kW" Vector__XXX
 SG_ DCACAssrInvrtr5DCSdVltg : 16|16@1+ (0.05,0) [0|3212.75] "V" Vector__XXX
 SG_ DCACAssIvt5DCSdNtvtCsssGdVt : 48|16@1+ (0.05,0) [0|3212.75] "V" Vector__XXX

BO_ 2364617214 DCACAI5V: 8 Vector__XXX
 SG_ DCACAssrInvrtr5IgntnVltg : 0|16@1+ (0.05,0) [0|3212.75] "V" Vector__XXX
 SG_ DCACAssrInvrtr5SLIVltg : 16|16@1+ (0.05,0) [0|3212.75] "V" Vector__XXX

BO_ 2365296894 DCDC4V: 8 Vector__XXX
 SG_ DCDC4CntrllrInptIgntnVltg : 0|16@1+ (0.05,0) [0|3212.75] "V" Vector__XXX
 SG_ DCDC4ControllerInputSLIVoltage : 16|16@1+ (0.05,0) [0|3212.75] "V" Vector__XXX

BO_ 2365297150 DCDC3V: 8 Vector__XXX
 SG_ DCDC3CntrllrInptIgntnVltg : 0|16@1+ (0.05,0) [0|3212.75] "V" Vector__XXX
 SG_ DCDC3ControllerInputSLIVoltage : 16|16@1+ (0.05,0) [0|3212.75] "V" Vector__XXX

BO_ 2365297406 DCDC2V: 8 Vector__XXX
 SG_ DCDC2CntrllrInptIgntnVltg : 0|16@1+ (0.05,0) [0|3212.75] "V" Vector__XXX
 SG_ DCDC2ControllerInputSLIVoltage : 16|16@1+ (0.05,0) [0|3212.75] "V" Vector__XXX

BO_ 2365297662 DCDC1V: 8 Vector__XXX
 SG_ DCDC1CntrllrInptIgntnVltg : 0|16@1+ (0.05,0) [0|3212.75] "V" Vector__XXX
 SG_ DCDC1ControllerInputSLIVoltage : 16|16@1+ (0.05,0) [0|3212.75] "V" Vector__XXX

BO_ 2365299454 DCACAI1DCL: 8 Vector__XXX
 SG_ DCACAssIvt1DCSdCtMLtRqst : 48|16@1+ (0.05,-3212.75) [-3212.75|0] "A" Vector__XXX
 SG_ DCACAssIvt1DCSdCtMxLtRqst : 16|16@1+ (0.05,0) [0|3212.75] "A" Vector__XXX
 SG_ DCACAssIvt1DCSdVtMLtRqst : 0|16@1+ (0.05,0) [0|3212.75] "V" Vector__XXX
 SG_ DCACAssIvt1DCSdVtMxLtRqst : 32|16@1+ (0.05,0) [0|3212.75] "V" Vector__XXX

BO_ 2365299710 DCACAI1ACL: 8 Vector__XXX
 SG_ DCACAssIvt1ACSdRMSCtMxLtRqst : 16|16@1+ (0.03125,0) [0|2007.96875] "Arms" Vector__XXX
 SG_ DCACAssIvt1ACSdRMSVtMxLtRqst : 0|16@1+ (0.03125,0) [0|2007.96875] "Vrms" Vector__XXX
 SG_ DCACAssrInvrtr1ACSdDfltFrqnRqst : 32|8@1+ (1,0) [0|250] "Hz" Vector__XXX

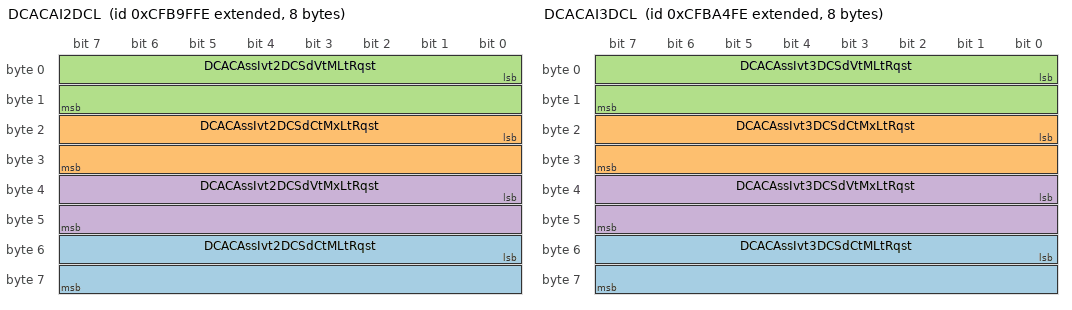
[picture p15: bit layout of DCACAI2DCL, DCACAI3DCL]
BO_ 2365300734 DCACAI2DCL: 8 Vector__XXX
 SG_ DCACAssIvt2DCSdCtMLtRqst : 48|16@1+ (0.05,-3212.75) [-3212.75|0] "A" Vector__XXX
 SG_ DCACAssIvt2DCSdCtMxLtRqst : 16|16@1+ (0.05,0) [0|3212.75] "A" Vector__XXX
 SG_ DCACAssIvt2DCSdVtMLtRqst : 0|16@1+ (0.05,0) [0|3212.75] "V" Vector__XXX
 SG_ DCACAssIvt2DCSdVtMxLtRqst : 32|16@1+ (0.05,0) [0|3212.75] "V" Vector__XXX

BO_ 2365300990 DCACAI2ACL: 8 Vector__XXX
 SG_ DCACAssIvt2ACSdRMSCtMxLtRqst : 16|16@1+ (0.03125,0) [0|2007.96875] "Arms" Vector__XXX
 SG_ DCACAssIvt2ACSdRMSVtMxLtRqst : 0|16@1+ (0.03125,0) [0|2007.96875] "Vrms" Vector__XXX
 SG_ DCACAssrInvrtr2ACSdDfltFrqnRqst : 32|8@1+ (1,0) [0|250] "Hz" Vector__XXX

BO_ 2365302014 DCACAI3DCL: 8 Vector__XXX
 SG_ DCACAssIvt3DCSdCtMLtRqst : 48|16@1+ (0.05,-3212.75) [-3212.75|0] "A" Vector__XXX
 SG_ DCACAssIvt3DCSdCtMxLtRqst : 16|16@1+ (0.05,0) [0|3212.75] "A" Vector__XXX
 SG_ DCACAssIvt3DCSdVtMLtRqst : 0|16@1+ (0.05,0) [0|3212.75] "V" Vector__XXX
 SG_ DCACAssIvt3DCSdVtMxLtRqst : 32|16@1+ (0.05,0) [0|3212.75] "V" Vector__XXX

BO_ 2365302270 DCACAI3ACL: 8 Vector__XXX
 SG_ DCACAssIvt3ACSdRMSCtMxLtRqst : 16|16@1+ (0.03125,0) [0|2007.96875] "Arms" Vector__XXX
 SG_ DCACAssIvt3ACSdRMSVtMxLtRqst : 0|16@1+ (0.03125,0) [0|2007.96875] "Vrms" Vector__XXX
 SG_ DCACAssrInvrtr3ACSdDfltFrqnRqst : 32|8@1+ (1,0) [0|250] "Hz" Vector__XXX

BO_ 2365303294 DCACAI4DCL: 8 Vector__XXX
 SG_ DCACAssIvt4DCSdCtMLtRqst : 48|16@1+ (0.05,-3212.75) [-3212.75|0] "A" Vector__XXX
 SG_ DCACAssIvt4DCSdCtMxLtRqst : 16|16@1+ (0.05,0) [0|3212.75] "A" Vector__XXX
 SG_ DCACAssIvt4DCSdVtMLtRqst : 0|16@1+ (0.05,0) [0|3212.75] "V" Vector__XXX
 SG_ DCACAssIvt4DCSdVtMxLtRqst : 32|16@1+ (0.05,0) [0|3212.75] "V" Vector__XXX

BO_ 2365303550 DCACAI4ACL: 8 Vector__XXX
 SG_ DCACAssIvt4ACSdRMSCtMxLtRqst : 16|16@1+ (0.03125,0) [0|2007.96875] "Arms" Vector__XXX
 SG_ DCACAssIvt4ACSdRMSVtMxLtRqst : 0|16@1+ (0.03125,0) [0|2007.96875] "Vrms" Vector__XXX
 SG_ DCACAssrInvrtr4ACSdDfltFrqnRqst : 32|8@1+ (1,0) [0|250] "Hz" Vector__XXX

BO_ 2365304574 DCACAI5DCL: 8 Vector__XXX
 SG_ DCACAssIvt5DCSdCtMLtRqst : 48|16@1+ (0.05,-3212.75) [-3212.75|0] "A" Vector__XXX
 SG_ DCACAssIvt5DCSdCtMxLtRqst : 16|16@1+ (0.05,0) [0|3212.75] "A" Vector__XXX
 SG_ DCACAssIvt5DCSdVtMLtRqst : 0|16@1+ (0.05,0) [0|3212.75] "V" Vector__XXX
 SG_ DCACAssIvt5DCSdVtMxLtRqst : 32|16@1+ (0.05,0) [0|3212.75] "V" Vector__XXX

BO_ 2365304830 DCACAI5ACL: 8 Vector__XXX
 SG_ DCACAssIvt5ACSdRMSCtMxLtRqst : 16|16@1+ (0.03125,0) [0|2007.96875] "Arms" Vector__XXX
 SG_ DCACAssIvt5ACSdRMSVtMxLtRqst : 0|16@1+ (0.03125,0) [0|2007.96875] "Vrms" Vector__XXX
 SG_ DCACAssrInvrtr5ACSdDfltFrqnRqst : 32|8@1+ (1,0) [0|250] "Hz" Vector__XXX

BO_ 2365307646 DCDC4SBL: 8 Vector__XXX
 SG_ DCDC4SLIBttrTmprtrMxmmLmtRqst : 32|8@1+ (1,-40) [-40|210] "degC" Vector__XXX
 SG_ DCDC4SLIBttTCCtMxLtRqst : 16|16@1+ (0.05,0) [0|3212.75] "A" Vector__XXX
 SG_ DCDC4SLIBttTVtMxLtRqst : 0|16@1+ (0.01,0) [0|642.55] "V" Vector__XXX

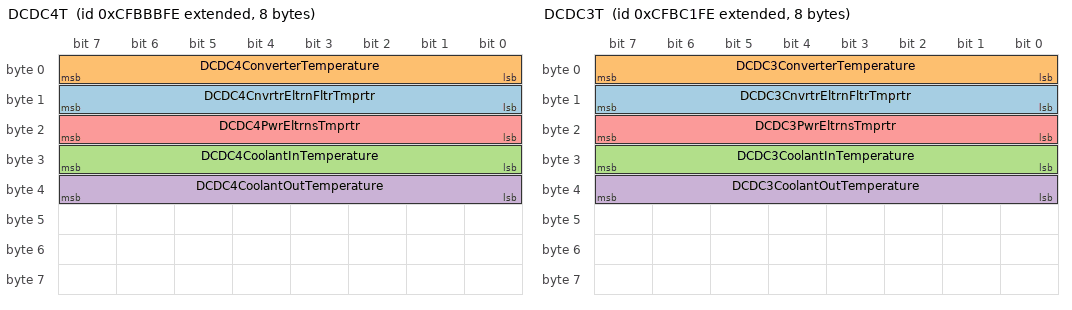
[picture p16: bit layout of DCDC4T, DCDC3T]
BO_ 2365307902 DCDC4T: 8 Vector__XXX
 SG_ DCDC4CnvrtrEltrnFltrTmprtr : 8|8@1+ (1,-40) [-40|210] "degC" Vector__XXX
 SG_ DCDC4ConverterTemperature : 0|8@1+ (1,-40) [-40|210] "degC" Vector__XXX
 SG_ DCDC4CoolantInTemperature : 24|8@1+ (1,-40) [-40|210] "degC" Vector__XXX
 SG_ DCDC4CoolantOutTemperature : 32|8@1+ (1,-40) [-40|210] "degC" Vector__XXX
 SG_ DCDC4PwrEltrnsTmprtr : 16|8@1+ (1,-40) [-40|210] "degC" Vector__XXX

BO_ 2365308158 DCDC4LL: 8 Vector__XXX
 SG_ DCDC4LwSdCrrntMxmmLmtRqst : 32|16@1+ (0.05,0) [0|3212.75] "A" Vector__XXX
 SG_ DCDC4LwSdVltgMnmmLmtRqst : 0|16@1+ (0.01,0) [0|642.55] "V" Vector__XXX
 SG_ DCDC4LwSdVltgMxmmLmtRqst : 16|16@1+ (0.01,0) [0|642.55] "V" Vector__XXX

BO_ 2365308414 DCDC4HL: 8 Vector__XXX
 SG_ DCDC4HghSdCrrntMxmmLmtRqst : 32|16@1+ (0.05,0) [0|3212.75] "A" Vector__XXX
 SG_ DCDC4HghSdVltgMnmmLmtRqst : 0|16@1+ (0.05,0) [0|3212.75] "V" Vector__XXX
 SG_ DCDC4HghSdVltgMxmmLmtRqst : 16|16@1+ (0.05,0) [0|3212.75] "V" Vector__XXX

BO_ 2365309182 DCDC3SBL: 8 Vector__XXX
 SG_ DCDC3SLIBttrTmprtrMxmmLmtRqst : 32|8@1+ (1,-40) [-40|210] "degC" Vector__XXX
 SG_ DCDC3SLIBttTCCtMxLtRqst : 16|16@1+ (0.05,0) [0|3212.75] "A" Vector__XXX
 SG_ DCDC3SLIBttTVtMxLtRqst : 0|16@1+ (0.01,0) [0|642.55] "V" Vector__XXX

BO_ 2365309438 DCDC3T: 8 Vector__XXX
 SG_ DCDC3CnvrtrEltrnFltrTmprtr : 8|8@1+ (1,-40) [-40|210] "degC" Vector__XXX
 SG_ DCDC3ConverterTemperature : 0|8@1+ (1,-40) [-40|210] "degC" Vector__XXX
 SG_ DCDC3CoolantInTemperature : 24|8@1+ (1,-40) [-40|210] "degC" Vector__XXX
 SG_ DCDC3CoolantOutTemperature : 32|8@1+ (1,-40) [-40|210] "degC" Vector__XXX
 SG_ DCDC3PwrEltrnsTmprtr : 16|8@1+ (1,-40) [-40|210] "degC" Vector__XXX

BO_ 2365309694 DCDC3LL: 8 Vector__XXX
 SG_ DCDC3LwSdCrrntMxmmLmtRqst : 32|16@1+ (0.05,0) [0|3212.75] "A" Vector__XXX
 SG_ DCDC3LwSdVltgMnmmLmtRqst : 0|16@1+ (0.01,0) [0|642.55] "V" Vector__XXX
 SG_ DCDC3LwSdVltgMxmmLmtRqst : 16|16@1+ (0.01,0) [0|642.55] "V" Vector__XXX

BO_ 2365309950 DCDC3HL: 8 Vector__XXX
 SG_ DCDC3HghSdCrrntMxmmLmtRqst : 32|16@1+ (0.05,0) [0|3212.75] "A" Vector__XXX
 SG_ DCDC3HghSdVltgMnmmLmtRqst : 0|16@1+ (0.05,0) [0|3212.75] "V" Vector__XXX
 SG_ DCDC3HghSdVltgMxmmLmtRqst : 16|16@1+ (0.05,0) [0|3212.75] "V" Vector__XXX

BO_ 2365310718 DCDC2SBL: 8 Vector__XXX
 SG_ DCDC2SLIBttrTmprtrMxmmLmtRqst : 32|8@1+ (1,-40) [-40|210] "degC" Vector__XXX
 SG_ DCDC2SLIBttTCCtMxLtRqst : 16|16@1+ (0.05,0) [0|3212.75] "A" Vector__XXX
 SG_ DCDC2SLIBttTVtMxLtRqst : 0|16@1+ (0.01,0) [0|642.55] "V" Vector__XXX

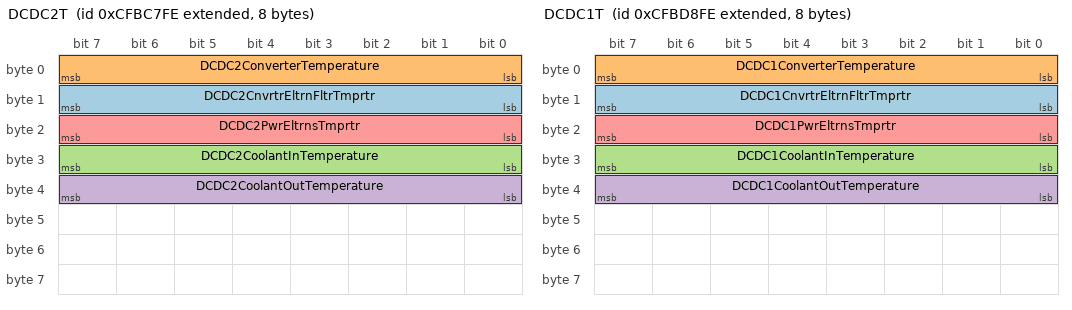
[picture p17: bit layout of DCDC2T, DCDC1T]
BO_ 2365310974 DCDC2T: 8 Vector__XXX
 SG_ DCDC2CnvrtrEltrnFltrTmprtr : 8|8@1+ (1,-40) [-40|210] "degC" Vector__XXX
 SG_ DCDC2ConverterTemperature : 0|8@1+ (1,-40) [-40|210] "degC" Vector__XXX
 SG_ DCDC2CoolantInTemperature : 24|8@1+ (1,-40) [-40|210] "degC" Vector__XXX
 SG_ DCDC2CoolantOutTemperature : 32|8@1+ (1,-40) [-40|210] "degC" Vector__XXX
 SG_ DCDC2PwrEltrnsTmprtr : 16|8@1+ (1,-40) [-40|210] "degC" Vector__XXX

BO_ 2365311230 DCDC2LL: 8 Vector__XXX
 SG_ DCDC2LwSdCrrntMxmmLmtRqst : 32|16@1+ (0.05,0) [0|3212.75] "A" Vector__XXX
 SG_ DCDC2LwSdVltgMnmmLmtRqst : 0|16@1+ (0.01,0) [0|642.55] "V" Vector__XXX
 SG_ DCDC2LwSdVltgMxmmLmtRqst : 16|16@1+ (0.01,0) [0|642.55] "V" Vector__XXX

BO_ 2365311486 DCDC2HL: 8 Vector__XXX
 SG_ DCDC2HghSdCrrntMxmmLmtRqst : 32|16@1+ (0.05,0) [0|3212.75] "A" Vector__XXX
 SG_ DCDC2HghSdVltgMnmmLmtRqst : 0|16@1+ (0.05,0) [0|3212.75] "V" Vector__XXX
 SG_ DCDC2HghSdVltgMxmmLmtRqst : 16|16@1+ (0.05,0) [0|3212.75] "V" Vector__XXX

BO_ 2365313534 DCDC1SBL: 8 Vector__XXX
 SG_ DCDC1SLIBttrTmprtrMxmmLmtRqst : 32|8@1+ (1,-40) [-40|210] "degC" Vector__XXX
 SG_ DCDC1SLIBttTCCtMxLtRqst : 16|16@1+ (0.05,0) [0|3212.75] "A" Vector__XXX
 SG_ DCDC1SLIBttTVtMxLtRqst : 0|16@1+ (0.01,0) [0|642.55] "V" Vector__XXX

BO_ 2365315326 DCDC1T: 8 Vector__XXX
 SG_ DCDC1CnvrtrEltrnFltrTmprtr : 8|8@1+ (1,-40) [-40|210] "degC" Vector__XXX
 SG_ DCDC1ConverterTemperature : 0|8@1+ (1,-40) [-40|210] "degC" Vector__XXX
 SG_ DCDC1CoolantInTemperature : 24|8@1+ (1,-40) [-40|210] "degC" Vector__XXX
 SG_ DCDC1CoolantOutTemperature : 32|8@1+ (1,-40) [-40|210] "degC" Vector__XXX
 SG_ DCDC1PwrEltrnsTmprtr : 16|8@1+ (1,-40) [-40|210] "degC" Vector__XXX

BO_ 2365315582 DCDC1LL: 8 Vector__XXX
 SG_ DCDC1LwSdCrrntMxmmLmtRqst : 32|16@1+ (0.05,0) [0|3212.75] "A" Vector__XXX
 SG_ DCDC1LwSdVltgMnmmLmtRqst : 0|16@1+ (0.01,0) [0|642.55] "V" Vector__XXX
 SG_ DCDC1LwSdVltgMxmmLmtRqst : 16|16@1+ (0.01,0) [0|642.55] "V" Vector__XXX

BO_ 2365315838 DCDC1HL: 8 Vector__XXX
 SG_ DCDC1HghSdCrrntMxmmLmtRqst : 32|16@1+ (0.05,0) [0|3212.75] "A" Vector__XXX
 SG_ DCDC1HghSdVltgMnmmLmtRqst : 0|16@1+ (0.05,0) [0|3212.75] "V" Vector__XXX
 SG_ DCDC1HghSdVltgMxmmLmtRqst : 16|16@1+ (0.05,0) [0|3212.75] "V" Vector__XXX

BO_ 2365318910 HVESFC: 8 Vector__XXX
 SG_ HVESFanEnableCommand : 0|2@1+ (1,0) [0|3] "" Vector__XXX
 SG_ HVESFanInstance1 : 32|1@1+ (1,0) [0|1] "" Vector__XXX
 SG_ HVESFanInstance10 : 41|1@1+ (1,0) [0|1] "" Vector__XXX
 SG_ HVESFanInstance11 : 42|1@1+ (1,0) [0|1] "" Vector__XXX
 SG_ HVESFanInstance12 : 43|1@1+ (1,0) [0|1] "" Vector__XXX
 SG_ HVESFanInstance13 : 44|1@1+ (1,0) [0|1] "" Vector__XXX
 SG_ HVESFanInstance14 : 45|1@1+ (1,0) [0|1] "" Vector__XXX
 SG_ HVESFanInstance15 : 46|1@1+ (1,0) [0|1] "" Vector__XXX
 SG_ HVESFanInstance2 : 33|1@1+ (1,0) [0|1] "" Vector__XXX
 SG_ HVESFanInstance3 : 34|1@1+ (1,0) [0|1] "" Vector__XXX
 SG_ HVESFanInstance4 : 35|1@1+ (1,0) [0|1] "" Vector__XXX
 SG_ HVESFanInstance5 : 36|1@1+ (1,0) [0|1] "" Vector__XXX
 SG_ HVESFanInstance6 : 37|1@1+ (1,0) [0|1] "" Vector__XXX
 SG_ HVESFanInstance7 : 38|1@1+ (1,0) [0|1] "" Vector__XXX
 SG_ HVESFanInstance8 : 39|1@1+ (1,0) [0|1] "" Vector__XXX
 SG_ HVESFanInstance9 : 40|1@1+ (1,0) [0|1] "" Vector__XXX
 SG_ HVESFanPercentSpeedCommand : 24|8@1+ (0.4,0) [0|100] "%" Vector__XXX
 SG_ HVESFanPowerHold : 2|2@1+ (1,0) [0|3] "" Vector__XXX
 SG_ HVESFanSpeedCommand : 8|16@1+ (0.5,0) [0|32127.5] "rpm" Vector__XXX

BO_ 2365322238 CCVS5: 8 Vector__XXX
 SG_ DirectionalVehicleSpeed : 0|16@1+ (0.0078125,-250) [-250|251.992] "km/h" Vector__XXX

BO_ 2365346302 ASC7: 8 Vector__XXX
 SG_ LiftAxle1Status : 0|3@1+ (1,0) [0|7] "" Vector__XXX
 SG_ LiftAxle2Status : 3|3@1+ (1,0) [0|7] "" Vector__XXX

BO_ 2365348350 ELS: 8 Vector__XXX
 SG_ EngineLoadShareStatus : 2|4@1+ (1,0) [0|15] "" Vector__XXX
 SG_ EngineUnloadStatus : 0|2@1+ (1,0) [0|3] "" Vector__XXX

BO_ 2365363710 ECPMSI: 8 Vector__XXX
 SG_ EngnClndrPrssrMntr1PrlmnrFMI : 0|5@1+ (1,0) [0|31] "binary" Vector__XXX
 SG_ EngnClndrPrssrMntr2PrlmnrFMI : 8|5@1+ (1,0) [0|31] "binary" Vector__XXX

BO_ 2365374206 ETC9: 8 Vector__XXX
 SG_ DlClthTrnsmssnCrrntPrsltnGr : 40|8@1+ (1,-125) [-125|125] "gear value" Vector__XXX
 SG_ DlClthTrnsmssnInptShft1Spd : 0|16@1+ (0.125,0) [0|8031.875] "rpm" Vector__XXX
 SG_ DlClthTrnsmssnInptShft2Spd : 16|16@1+ (0.125,0) [0|8031.875] "rpm" Vector__XXX
 SG_ DlClthTrnsmssnSltdPrsltnGr : 32|8@1+ (1,-125) [-125|125] "gear value" Vector__XXX

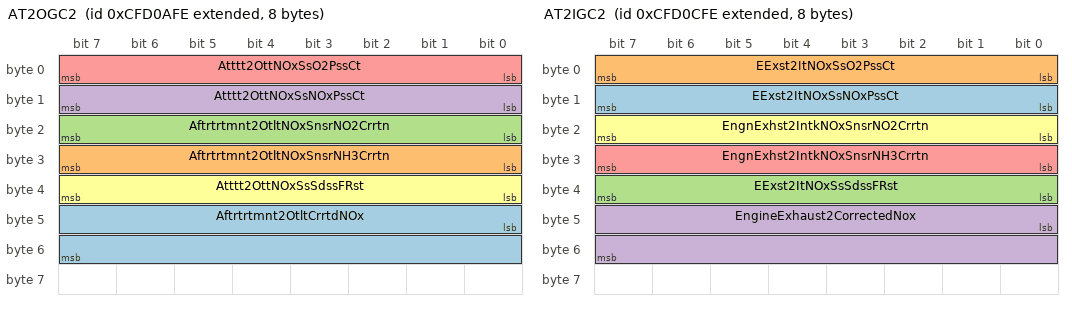
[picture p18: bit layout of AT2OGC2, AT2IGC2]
BO_ 2365393662 AT2OGC2: 8 Vector__XXX
 SG_ Aftrtrtmnt2OtltCrrtdNOx : 40|16@1+ (0.05,-200) [-200|3012.75] "ppm" Vector__XXX
 SG_ Aftrtrtmnt2OtltNOxSnsrNH3Crrtn : 24|8@1+ (0.5,0) [0|125] "%" Vector__XXX
 SG_ Aftrtrtmnt2OtltNOxSnsrNO2Crrtn : 16|8@1+ (0.5,0) [0|125] "%" Vector__XXX
 SG_ Atttt2OttNOxSsNOxPssCt : 8|8@1+ (0.5,0) [0|125] "%/bar" Vector__XXX
 SG_ Atttt2OttNOxSsO2PssCt : 0|8@1+ (0.5,0) [0|125] "%/bar" Vector__XXX
 SG_ Atttt2OttNOxSsSdssFRst : 32|8@1+ (1,0) [0|250] "Ratio" Vector__XXX

BO_ 2365393918 AT2OGC1: 8 Vector__XXX
 SG_ Aftrtrtmnt2OtltNOxSnsrHtrRt : 0|16@1+ (0.001,0) [0|64.255] "Ratio" Vector__XXX
 SG_ Aftrtrtmnt2OtltNOxSnsrOprtnHrs : 40|16@1+ (1,0) [0|64255] "h" Vector__XXX
 SG_ Atttt2OttNOxSsNwptdvtNOxG : 16|16@1+ (0.1,-100) [-100|6325.5] "%" Vector__XXX
 SG_ Atttt2OttNOxSsNwptdvtNOxOst : 32|8@1+ (1,-125) [-125|125] "ppm" Vector__XXX

BO_ 2365394174 AT2IGC2: 8 Vector__XXX
 SG_ EExst2ItNOxSsNOxPssCt : 8|8@1+ (0.5,0) [0|125] "%/bar" Vector__XXX
 SG_ EExst2ItNOxSsO2PssCt : 0|8@1+ (0.5,0) [0|125] "%/bar" Vector__XXX
 SG_ EExst2ItNOxSsSdssFRst : 32|8@1+ (1,0) [0|250] "Ratio" Vector__XXX
 SG_ EngineExhaust2CorrectedNox : 40|16@1+ (0.05,-200) [-200|3012.75] "ppm" Vector__XXX
 SG_ EngnExhst2IntkNOxSnsrNH3Crrtn : 24|8@1+ (0.5,0) [0|125] "%" Vector__XXX
 SG_ EngnExhst2IntkNOxSnsrNO2Crrtn : 16|8@1+ (0.5,0) [0|125] "%" Vector__XXX

BO_ 2365394430 AT2IGC1: 8 Vector__XXX
 SG_ EExst2ItNOxSsNwptdvtNOxG : 16|16@1+ (0.1,-100) [-100|6325.5] "%" Vector__XXX
 SG_ EExst2ItNOxSsNwptdvtNOxOst : 32|8@1+ (1,-125) [-125|125] "ppm" Vector__XXX
 SG_ EngnExhst2IntkNOxSnsrHtrRt : 0|16@1+ (0.001,0) [0|64.255] "Ratio" Vector__XXX
 SG_ EngnExhst2IntkNOxSnsrOprtnHrs : 40|16@1+ (1,0) [0|64255] "h" Vector__XXX

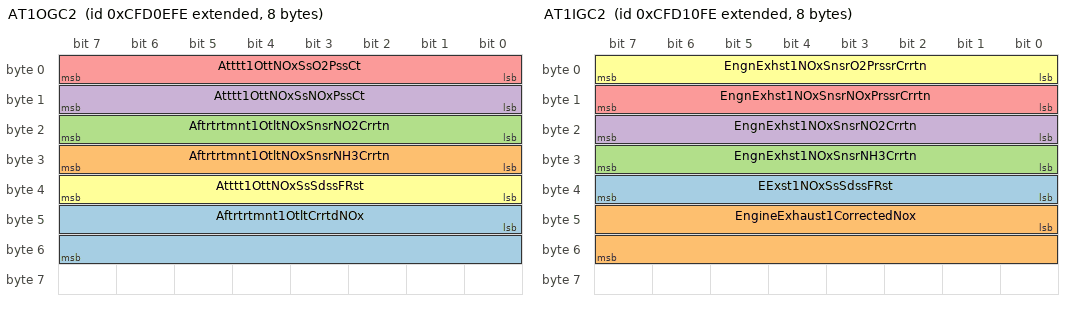
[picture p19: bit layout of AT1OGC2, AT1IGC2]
BO_ 2365394686 AT1OGC2: 8 Vector__XXX
 SG_ Aftrtrtmnt1OtltCrrtdNOx : 40|16@1+ (0.05,-200) [-200|3012.75] "ppm" Vector__XXX
 SG_ Aftrtrtmnt1OtltNOxSnsrNH3Crrtn : 24|8@1+ (0.5,0) [0|125] "%" Vector__XXX
 SG_ Aftrtrtmnt1OtltNOxSnsrNO2Crrtn : 16|8@1+ (0.5,0) [0|125] "%" Vector__XXX
 SG_ Atttt1OttNOxSsNOxPssCt : 8|8@1+ (0.5,0) [0|125] "%/bar" Vector__XXX
 SG_ Atttt1OttNOxSsO2PssCt : 0|8@1+ (0.5,0) [0|125] "%/bar" Vector__XXX
 SG_ Atttt1OttNOxSsSdssFRst : 32|8@1+ (1,0) [0|250] "Ratio" Vector__XXX

BO_ 2365394942 AT1OGC1: 8 Vector__XXX
 SG_ Aftrtrtmnt1OtltNOxSnsrHtrRt : 0|16@1+ (0.001,0) [0|64.255] "Ratio" Vector__XXX
 SG_ Aftrtrtmnt1OtltNOxSnsrOprtnHrs : 40|16@1+ (1,0) [0|64255] "h" Vector__XXX
 SG_ Atttt1OttNOxSsNwptdvtNOxG : 16|16@1+ (0.1,-100) [-100|6325.5] "%" Vector__XXX
 SG_ Atttt1OttNOxSsNwptdvtNOxOst : 32|8@1+ (1,-125) [-125|125] "ppm" Vector__XXX

BO_ 2365395198 AT1IGC2: 8 Vector__XXX
 SG_ EExst1NOxSsSdssFRst : 32|8@1+ (1,0) [0|250] "Ratio" Vector__XXX
 SG_ EngineExhaust1CorrectedNox : 40|16@1+ (0.05,-200) [-200|3012.75] "ppm" Vector__XXX
 SG_ EngnExhst1NOxSnsrNH3Crrtn : 24|8@1+ (0.5,0) [0|125] "%" Vector__XXX
 SG_ EngnExhst1NOxSnsrNO2Crrtn : 16|8@1+ (0.5,0) [0|125] "%" Vector__XXX
 SG_ EngnExhst1NOxSnsrNOxPrssrCrrtn : 8|8@1+ (0.5,0) [0|125] "%/bar" Vector__XXX
 SG_ EngnExhst1NOxSnsrO2PrssrCrrtn : 0|8@1+ (0.5,0) [0|125] "%/bar" Vector__XXX

BO_ 2365395454 AT1IGC1: 8 Vector__XXX
 SG_ EExst1NOxSsNwptdvtNOxOst : 32|8@1+ (1,-125) [-125|125] "ppm" Vector__XXX
 SG_ EngnExhst1NOxSnsrHtrRt : 0|16@1+ (0.001,0) [0|64.255] "Ratio" Vector__XXX
 SG_ EngnExhst1NOxSnsrNwprtdvtnNOxGn : 16|16@1+ (0.1,-100) [-100|6325.5] "%" Vector__XXX
 SG_ EngnExhst1NOxSnsrOprtnHrs : 40|16@1+ (1,0) [0|64255] "h" Vector__XXX

BO_ 2365400062 EJM10: 8 Vector__XXX
 SG_ Joystick10Button13PressedStatus : 62|2@1+ (1,0) [0|3] "" Vector__XXX
 SG_ Joystick10Button14PressedStatus : 60|2@1+ (1,0) [0|3] "" Vector__XXX
 SG_ Joystick10Button15PressedStatus : 58|2@1+ (1,0) [0|3] "" Vector__XXX
 SG_ Joystick10Button16PressedStatus : 56|2@1+ (1,0) [0|3] "" Vector__XXX
 SG_ Joystick10GripXAxisPosition : 6|10@1+ (0.1,0) [0|102] "%" Vector__XXX
 SG_ Joystick10GripYAxisPosition : 22|10@1+ (0.1,0) [0|102] "%" Vector__XXX
 SG_ Joystick10ThetaAxisPosition : 38|10@1+ (0.1,0) [0|102] "%" Vector__XXX
 SG_ Jst10GpXAxsLvRtPstvPstStts : 4|2@1+ (1,0) [0|3] "" Vector__XXX
 SG_ Jst10GpYAxsLvFwdPstvPstStts : 20|2@1+ (1,0) [0|3] "" Vector__XXX
 SG_ Jst10TtAxsCtCwsNtvPstStts : 34|2@1+ (1,0) [0|3] "" Vector__XXX
 SG_ Jstk10GrpXAxsDtntPstnStts : 54|2@1+ (1,0) [0|3] "" Vector__XXX
 SG_ Jstk10GrpXAxsLvrLftNgtvPstnStts : 2|2@1+ (1,0) [0|3] "" Vector__XXX
 SG_ Jstk10GrpXAxsNtrlPstnStts : 0|2@1+ (1,0) [0|3] "" Vector__XXX
 SG_ Jstk10GrpYAxsDtntPstnStts : 52|2@1+ (1,0) [0|3] "" Vector__XXX
 SG_ Jstk10GrpYAxsLvrBkNgtvPstnStts : 18|2@1+ (1,0) [0|3] "" Vector__XXX
 SG_ Jstk10GrpYAxsNtrlPstnStts : 16|2@1+ (1,0) [0|3] "" Vector__XXX
 SG_ Jstk10ThtAxsClkwsPstvPstnStts : 36|2@1+ (1,0) [0|3] "" Vector__XXX
 SG_ Jstk10ThtAxsDtntPstnStts : 50|2@1+ (1,0) [0|3] "" Vector__XXX
 SG_ Jstk10ThtAxsNtrlPstnStts : 32|2@1+ (1,0) [0|3] "" Vector__XXX

BO_ 2365400318 BJM10: 8 Vector__XXX
 SG_ Joystick10Button10PressedStatus : 60|2@1+ (1,0) [0|3] "" Vector__XXX
 SG_ Joystick10Button11PressedStatus : 58|2@1+ (1,0) [0|3] "" Vector__XXX
 SG_ Joystick10Button12PressedStatus : 56|2@1+ (1,0) [0|3] "" Vector__XXX
 SG_ Joystick10Button1PressedStatus : 46|2@1+ (1,0) [0|3] "" Vector__XXX
 SG_ Joystick10Button2PressedStatus : 44|2@1+ (1,0) [0|3] "" Vector__XXX
 SG_ Joystick10Button3PressedStatus : 42|2@1+ (1,0) [0|3] "" Vector__XXX
 SG_ Joystick10Button4PressedStatus : 40|2@1+ (1,0) [0|3] "" Vector__XXX
 SG_ Joystick10Button5PressedStatus : 54|2@1+ (1,0) [0|3] "" Vector__XXX
 SG_ Joystick10Button6PressedStatus : 52|2@1+ (1,0) [0|3] "" Vector__XXX
 SG_ Joystick10Button7PressedStatus : 50|2@1+ (1,0) [0|3] "" Vector__XXX
 SG_ Joystick10Button8PressedStatus : 48|2@1+ (1,0) [0|3] "" Vector__XXX
 SG_ Joystick10Button9PressedStatus : 62|2@1+ (1,0) [0|3] "" Vector__XXX
 SG_ Joystick10XAxisPosition : 6|10@1+ (0.1,0) [0|102] "%" Vector__XXX
 SG_ Joystick10YAxisPosition : 22|10@1+ (0.1,0) [0|102] "%" Vector__XXX
 SG_ Jstk10XAxsDtntPstnStts : 38|2@1+ (1,0) [0|3] "" Vector__XXX
 SG_ Jstk10XAxsLvrLftNgtvPstnStts : 2|2@1+ (1,0) [0|3] "" Vector__XXX
 SG_ Jstk10XAxsLvrRghtPstvPstnStts : 4|2@1+ (1,0) [0|3] "" Vector__XXX
 SG_ Jstk10XAxsNtrlPstnStts : 0|2@1+ (1,0) [0|3] "" Vector__XXX
 SG_ Jstk10YAxsDtntPstnStts : 36|2@1+ (1,0) [0|3] "" Vector__XXX
 SG_ Jstk10YAxsLvrBkNgtvPstnStts : 18|2@1+ (1,0) [0|3] "" Vector__XXX
 SG_ Jstk10YAxsLvrFrwrdPstvPstnStts : 20|2@1+ (1,0) [0|3] "" Vector__XXX
 SG_ Jstk10YAxsNtrlPstnStts : 16|2@1+ (1,0) [0|3] "" Vector__XXX

BO_ 2365400574 EJM9: 8 Vector__XXX
 SG_ Joystick9Button13PressedStatus : 62|2@1+ (1,0) [0|3] "" Vector__XXX
 SG_ Joystick9Button14PressedStatus : 60|2@1+ (1,0) [0|3] "" Vector__XXX
 SG_ Joystick9Button15PressedStatus : 58|2@1+ (1,0) [0|3] "" Vector__XXX
 SG_ Joystick9Button16PressedStatus : 56|2@1+ (1,0) [0|3] "" Vector__XXX
 SG_ Joystick9GripXAxisPosition : 6|10@1+ (0.1,0) [0|102] "%" Vector__XXX
 SG_ Joystick9GripYAxisPosition : 22|10@1+ (0.1,0) [0|102] "%" Vector__XXX
 SG_ Joystick9ThetaAxisPosition : 38|10@1+ (0.1,0) [0|102] "%" Vector__XXX
 SG_ Jst9GpYAxsLvFwdPstvPstStts : 20|2@1+ (1,0) [0|3] "" Vector__XXX
 SG_ Jst9TtAxsCtCwsNtvPstStts : 34|2@1+ (1,0) [0|3] "" Vector__XXX
 SG_ Jstk9GrpXAxsDtntPstnStts : 54|2@1+ (1,0) [0|3] "" Vector__XXX
 SG_ Jstk9GrpXAxsLvrLftNgtvPstnStts : 2|2@1+ (1,0) [0|3] "" Vector__XXX
 SG_ Jstk9GrpXAxsLvrRghtPstvPstnStts : 4|2@1+ (1,0) [0|3] "" Vector__XXX
 SG_ Jstk9GrpXAxsNtrlPstnStts : 0|2@1+ (1,0) [0|3] "" Vector__XXX
 SG_ Jstk9GrpYAxsDtntPstnStts : 52|2@1+ (1,0) [0|3] "" Vector__XXX
 SG_ Jstk9GrpYAxsLvrBkNgtvPstnStts : 18|2@1+ (1,0) [0|3] "" Vector__XXX
 SG_ Jstk9GrpYAxsNtrlPstnStts : 16|2@1+ (1,0) [0|3] "" Vector__XXX
 SG_ Jstk9ThtAxsClkwsPstvPstnStts : 36|2@1+ (1,0) [0|3] "" Vector__XXX
 SG_ Jstk9ThtAxsDtntPstnStts : 50|2@1+ (1,0) [0|3] "" Vector__XXX
 SG_ Jstk9ThtAxsNtrlPstnStts : 32|2@1+ (1,0) [0|3] "" Vector__XXX

BO_ 2365400830 BJM9: 8 Vector__XXX
 SG_ Joystick9Button10PressedStatus : 60|2@1+ (1,0) [0|3] "" Vector__XXX
 SG_ Joystick9Button11PressedStatus : 58|2@1+ (1,0) [0|3] "" Vector__XXX
 SG_ Joystick9Button12PressedStatus : 56|2@1+ (1,0) [0|3] "" Vector__XXX
 SG_ Joystick9Button1PressedStatus : 46|2@1+ (1,0) [0|3] "" Vector__XXX
 SG_ Joystick9Button2PressedStatus : 44|2@1+ (1,0) [0|3] "" Vector__XXX
 SG_ Joystick9Button3PressedStatus : 42|2@1+ (1,0) [0|3] "" Vector__XXX
 SG_ Joystick9Button4PressedStatus : 40|2@1+ (1,0) [0|3] "" Vector__XXX
 SG_ Joystick9Button5PressedStatus : 54|2@1+ (1,0) [0|3] "" Vector__XXX
 SG_ Joystick9Button6PressedStatus : 52|2@1+ (1,0) [0|3] "" Vector__XXX
 SG_ Joystick9Button7PressedStatus : 50|2@1+ (1,0) [0|3] "" Vector__XXX
 SG_ Joystick9Button8PressedStatus : 48|2@1+ (1,0) [0|3] "" Vector__XXX
 SG_ Joystick9Button9PressedStatus : 62|2@1+ (1,0) [0|3] "" Vector__XXX
 SG_ Joystick9XAxisPosition : 6|10@1+ (0.1,0) [0|102] "%" Vector__XXX
 SG_ Joystick9YAxisPosition : 22|10@1+ (0.1,0) [0|102] "%" Vector__XXX
 SG_ Jstk9XAxsDtntPstnStts : 38|2@1+ (1,0) [0|3] "" Vector__XXX
 SG_ Jstk9XAxsLvrLftNgtvPstnStts : 2|2@1+ (1,0) [0|3] "" Vector__XXX
 SG_ Jstk9XAxsLvrRghtPstvPstnStts : 4|2@1+ (1,0) [0|3] "" Vector__XXX
 SG_ Jstk9XAxsNtrlPstnStts : 0|2@1+ (1,0) [0|3] "" Vector__XXX
 SG_ Jstk9YAxsDtntPstnStts : 36|2@1+ (1,0) [0|3] "" Vector__XXX
 SG_ Jstk9YAxsLvrBkNgtvPstnStts : 18|2@1+ (1,0) [0|3] "" Vector__XXX
 SG_ Jstk9YAxsLvrFrwrdPstvPstnStts : 20|2@1+ (1,0) [0|3] "" Vector__XXX
 SG_ Jstk9YAxsNtrlPstnStts : 16|2@1+ (1,0) [0|3] "" Vector__XXX

BO_ 2365401086 EJM8: 8 Vector__XXX
 SG_ Joystick8Button13PressedStatus : 62|2@1+ (1,0) [0|3] "" Vector__XXX
 SG_ Joystick8Button14PressedStatus : 60|2@1+ (1,0) [0|3] "" Vector__XXX
 SG_ Joystick8Button15PressedStatus : 58|2@1+ (1,0) [0|3] "" Vector__XXX
 SG_ Joystick8Button16PressedStatus : 56|2@1+ (1,0) [0|3] "" Vector__XXX
 SG_ Joystick8GripXAxisPosition : 6|10@1+ (0.1,0) [0|102] "%" Vector__XXX
 SG_ Joystick8GripYAxisPosition : 22|10@1+ (0.1,0) [0|102] "%" Vector__XXX
 SG_ Joystick8ThetaAxisPosition : 38|10@1+ (0.1,0) [0|102] "%" Vector__XXX
 SG_ Jst8GpYAxsLvFwdPstvPstStts : 20|2@1+ (1,0) [0|3] "" Vector__XXX
 SG_ Jst8TtAxsCtCwsNtvPstStts : 34|2@1+ (1,0) [0|3] "" Vector__XXX
 SG_ Jstk8GrpXAxsDtntPstnStts : 54|2@1+ (1,0) [0|3] "" Vector__XXX
 SG_ Jstk8GrpXAxsLvrLftNgtvPstnStts : 2|2@1+ (1,0) [0|3] "" Vector__XXX
 SG_ Jstk8GrpXAxsLvrRghtPstvPstnStts : 4|2@1+ (1,0) [0|3] "" Vector__XXX
 SG_ Jstk8GrpXAxsNtrlPstnStts : 0|2@1+ (1,0) [0|3] "" Vector__XXX
 SG_ Jstk8GrpYAxsDtntPstnStts : 52|2@1+ (1,0) [0|3] "" Vector__XXX
 SG_ Jstk8GrpYAxsLvrBkNgtvPstnStts : 18|2@1+ (1,0) [0|3] "" Vector__XXX
 SG_ Jstk8GrpYAxsNtrlPstnStts : 16|2@1+ (1,0) [0|3] "" Vector__XXX
 SG_ Jstk8ThtAxsClkwsPstvPstnStts : 36|2@1+ (1,0) [0|3] "" Vector__XXX
 SG_ Jstk8ThtAxsDtntPstnStts : 50|2@1+ (1,0) [0|3] "" Vector__XXX
 SG_ Jstk8ThtAxsNtrlPstnStts : 32|2@1+ (1,0) [0|3] "" Vector__XXX

BO_ 2365401342 BJM8: 8 Vector__XXX
 SG_ Joystick8Button10PressedStatus : 60|2@1+ (1,0) [0|3] "" Vector__XXX
 SG_ Joystick8Button11PressedStatus : 58|2@1+ (1,0) [0|3] "" Vector__XXX
 SG_ Joystick8Button12PressedStatus : 56|2@1+ (1,0) [0|3] "" Vector__XXX
 SG_ Joystick8Button1PressedStatus : 46|2@1+ (1,0) [0|3] "" Vector__XXX
 SG_ Joystick8Button2PressedStatus : 44|2@1+ (1,0) [0|3] "" Vector__XXX
 SG_ Joystick8Button3PressedStatus : 42|2@1+ (1,0) [0|3] "" Vector__XXX
 SG_ Joystick8Button4PressedStatus : 40|2@1+ (1,0) [0|3] "" Vector__XXX
 SG_ Joystick8Button5PressedStatus : 54|2@1+ (1,0) [0|3] "" Vector__XXX
 SG_ Joystick8Button6PressedStatus : 52|2@1+ (1,0) [0|3] "" Vector__XXX
 SG_ Joystick8Button7PressedStatus : 50|2@1+ (1,0) [0|3] "" Vector__XXX
 SG_ Joystick8Button8PressedStatus : 48|2@1+ (1,0) [0|3] "" Vector__XXX
 SG_ Joystick8Button9PressedStatus : 62|2@1+ (1,0) [0|3] "" Vector__XXX
 SG_ Joystick8XAxisPosition : 6|10@1+ (0.1,0) [0|102] "%" Vector__XXX
 SG_ Joystick8YAxisPosition : 22|10@1+ (0.1,0) [0|102] "%" Vector__XXX
 SG_ Jstk8XAxsDtntPstnStts : 38|2@1+ (1,0) [0|3] "" Vector__XXX
 SG_ Jstk8XAxsLvrLftNgtvPstnStts : 2|2@1+ (1,0) [0|3] "" Vector__XXX
 SG_ Jstk8XAxsLvrRghtPstvPstnStts : 4|2@1+ (1,0) [0|3] "" Vector__XXX
 SG_ Jstk8XAxsNtrlPstnStts : 0|2@1+ (1,0) [0|3] "" Vector__XXX
 SG_ Jstk8YAxsDtntPstnStts : 36|2@1+ (1,0) [0|3] "" Vector__XXX
 SG_ Jstk8YAxsLvrBkNgtvPstnStts : 18|2@1+ (1,0) [0|3] "" Vector__XXX
 SG_ Jstk8YAxsLvrFrwrdPstvPstnStts : 20|2@1+ (1,0) [0|3] "" Vector__XXX
 SG_ Jstk8YAxsNtrlPstnStts : 16|2@1+ (1,0) [0|3] "" Vector__XXX

CM_ BO_ 2364590334 "DC/AC Accessory Inverter 1 Status 2";
CM_ SG_ 2364590334 DCACAssrInvrtr1DCSdCrrnt "DC Side input current measured at the point of control inside the DC/AC Accessory Inverter.…";
CM_ SG_ 2364590334 DCACAssrInvrtr1DCSdPwr "Power measured at the DC Side input to the DC/AC Accessory Inverter. …";
CM_ SG_ 2364590334 DCACAssrInvrtr1DCSdVltg "DC Side input voltage measured at the point of control inside the DC/AC Accessory Inverter.…";
CM_ SG_ 2364590334 DCACAssIvt1DCSdNtvtCsssGdVt "The voltage level of the high voltage DC side, as measured by the DC/AC between the negative side of the High Voltage DC Side input and the chassis of the DC/AC…";
CM_ BO_ 2364590590 "DC/AC Accessory Inverter 1 Voltage";
CM_ SG_ 2364590590 DCACAssrInvrtr1IgntnVltg "Ignition voltage supplied to the  DC/AC Accessory Inverter controller.…";
CM_ SG_ 2364590590 DCACAssrInvrtr1SLIVltg "Low voltage (SLI) supplied to the DC/AC Accessory Inverter controller.…";
CM_ BO_ 2364591102 "DC/AC Accessory Inverter 2 Status 2";
CM_ SG_ 2364591102 DCACAssrInvrtr2DCSdCrrnt "DC Side input current measured at the point of control inside the DC/AC Accessory Inverter.…";
CM_ SG_ 2364591102 DCACAssrInvrtr2DCSdPwr "Power measured at the DC Side input to the DC/AC Accessory Inverter. …";
CM_ SG_ 2364591102 DCACAssrInvrtr2DCSdVltg "DC Side input voltage measured at the point of control inside the DC/AC Accessory Inverter.…";
CM_ SG_ 2364591102 DCACAssIvt2DCSdNtvtCsssGdVt "The voltage level of the high voltage DC side, as measured by the DC/AC between the negative side of the High Voltage DC Side input and the chassis of the DC/AC…";
CM_ BO_ 2364591358 "DC/AC Accessory Inverter 2 Voltage";
CM_ SG_ 2364591358 DCACAssrInvrtr2IgntnVltg "Ignition voltage supplied to the  DC/AC Accessory Inverter controller.…";
CM_ SG_ 2364591358 DCACAssrInvrtr2SLIVltg "Low voltage (SLI) supplied to the DC/AC Accessory Inverter controller.…";
CM_ BO_ 2364592382 "Engine Cylinder Combustion Request";
CM_ SG_ 2364592382 EngnClndr10ExldfrmCmstnRqst "Request to the engine ECU to exclude (skip or cut-out) cylinder 10 from combustion.00b = Exclude from Combustion01b = Include for Combustion10b = Reserved11b = …";
CM_ SG_ 2364592382 EngnClndr11ExldfrmCmstnRqst "Request to the engine ECU to exclude (skip or cut-out) cylinder 11 from combustion.00b = Exclude from Combustion01b = Include for Combustion10b = Reserved11b = …";
CM_ SG_ 2364592382 EngnClndr12ExldfrmCmstnRqst "Request to the engine ECU to exclude (skip or cut-out) cylinder 12 from combustion.00b = Exclude from Combustion01b = Include for Combustion10b = Reserved11b = …";
CM_ SG_ 2364592382 EngnClndr13ExldfrmCmstnRqst "Request to the engine ECU to exclude (skip or cut-out) cylinder 13 from combustion.00b = Exclude from Combustion01b = Include for Combustion10b = Reserved11b = …";
CM_ SG_ 2364592382 EngnClndr14ExldfrmCmstnRqst "Request to the engine ECU to exclude (skip or cut-out) cylinder 14 from combustion.00b = Exclude from Combustion01b = Include for Combustion10b = Reserved11b = …";
CM_ SG_ 2364592382 EngnClndr15ExldfrmCmstnRqst "Request to the engine ECU to exclude (skip or cut-out) cylinder 15 from combustion.00b = Exclude from Combustion01b = Include for Combustion10b = Reserved11b = …";
CM_ SG_ 2364592382 EngnClndr16ExldfrmCmstnRqst "Request to the engine ECU to exclude (skip or cut-out) cylinder 16 from combustion.00b = Exclude from Combustion01b = Include for Combustion10b = Reserved11b = …";
CM_ SG_ 2364592382 EngnClndr17ExldfrmCmstnRqst "Request to the engine ECU to exclude (skip or cut-out) cylinder 17 from combustion.00b = Exclude from Combustion01b = Include for Combustion10b = Reserved11b = …";
CM_ SG_ 2364592382 EngnClndr18ExldfrmCmstnRqst "Request to the engine ECU to exclude (skip or cut-out) cylinder 18 from combustion.00b = Exclude from Combustion01b = Include for Combustion10b = Reserved11b = …";
CM_ SG_ 2364592382 EngnClndr19ExldfrmCmstnRqst "Request to the engine ECU to exclude (skip or cut-out) cylinder 19 from combustion.00b = Exclude from Combustion01b = Include for Combustion10b = Reserved11b = …";
CM_ SG_ 2364592382 EngnClndr1ExldfrmCmstnRqst "Request to the engine ECU to exclude (skip or cut-out) cylinder 1 from combustion.00b = Exclude from Combustion01b = Include for Combustion10b = Reserved11b = N…";
CM_ SG_ 2364592382 EngnClndr20ExldfrmCmstnRqst "Request to the engine ECU to exclude (skip or cut-out) cylinder 20 from combustion.00b = Exclude from Combustion01b = Include for Combustion10b = Reserved11b = …";
CM_ SG_ 2364592382 EngnClndr21ExldfrmCmstnRqst "Request to the engine ECU to exclude (skip or cut-out) cylinder 21 from combustion.00b = Exclude from Combustion01b = Include for Combustion10b = Reserved11b = …";
CM_ SG_ 2364592382 EngnClndr22ExldfrmCmstnRqst "Request to the engine ECU to exclude (skip or cut-out) cylinder 22 from combustion.00b = Exclude from Combustion01b = Include for Combustion10b = Reserved11b = …";
CM_ SG_ 2364592382 EngnClndr23ExldfrmCmstnRqst "Request to the engine ECU to exclude (skip or cut-out) cylinder 23 from combustion.00b = Exclude from Combustion01b = Include for Combustion10b = Reserved11b = …";
CM_ SG_ 2364592382 EngnClndr24ExldfrmCmstnRqst "Request to the engine ECU to exclude (skip or cut-out) cylinder 24 from combustion.00b = Exclude from Combustion01b = Include for Combustion10b = Reserved11b = …";
CM_ SG_ 2364592382 EngnClndr2ExldfrmCmstnRqst "Request to the engine ECU to exclude (skip or cut-out) cylinder 2 from combustion.00b = Exclude from Combustion01b = Include for Combustion10b = Reserved11b = N…";
CM_ SG_ 2364592382 EngnClndr3ExldfrmCmstnRqst "Request to the engine ECU to exclude (skip or cut-out) cylinder 3 from combustion.00b = Exclude from Combustion01b = Include for Combustion10b = Reserved11b = N…";
CM_ SG_ 2364592382 EngnClndr4ExldfrmCmstnRqst "Request to the engine ECU to exclude (skip or cut-out) cylinder 4 from combustion.00b = Exclude from Combustion01b = Include for Combustion10b = Reserved11b = N…";
CM_ SG_ 2364592382 EngnClndr5ExldfrmCmstnRqst "Request to the engine ECU to exclude (skip or cut-out) cylinder 5 from combustion.00b = Exclude from Combustion01b = Include for Combustion10b = Reserved11b = N…";
CM_ SG_ 2364592382 EngnClndr6ExldfrmCmstnRqst "Request to the engine ECU to exclude (skip or cut-out) cylinder 6 from combustion.00b = Exclude from Combustion01b = Include for Combustion10b = Reserved11b = N…";
CM_ SG_ 2364592382 EngnClndr7ExldfrmCmstnRqst "Request to the engine ECU to exclude (skip or cut-out) cylinder 7 from combustion.00b = Exclude from Combustion01b = Include for Combustion10b = Reserved11b = N…";
CM_ SG_ 2364592382 EngnClndr8ExldfrmCmstnRqst "Request to the engine ECU to exclude (skip or cut-out) cylinder 8 from combustion.00b = Exclude from Combustion01b = Include for Combustion10b = Reserved11b = N…";
CM_ SG_ 2364592382 EngnClndr9ExldfrmCmstnRqst "Request to the engine ECU to exclude (skip or cut-out) cylinder 9 from combustion.00b = Exclude from Combustion01b = Include for Combustion10b = Reserved11b = N…";
CM_ SG_ 2364592382 NmrfEngnClndrstExldfrmCmstn "Request to the engine ECU for the number of cylinders to exclude from combustion (cut-out or skip) for a given instance in time.  The engine ECU can decide on t…";
CM_ BO_ 2364592638 "Engine Cylinder Head Bypass Actuator 1";
CM_ SG_ 2364592638 EngnClndrHdBpssAttr1DsrdPstn "Requested position of Engine Cylinder Head Bypass actuator by engine ECM, where 0% represents bypass fully closed and 100% represents fully open. This is the po…";
CM_ SG_ 2364592638 EngnClndrHdBpssAttr1OprtnStts "Identifies the status of Engine Cylinder Head Bypass Actuator 1.Cylinder head bypass valve is used to release the air at the high pressure compressor outlet int…";
CM_ SG_ 2364592638 EngnClndrHdBpssAttr1PrlmnrFMI "Used to identify the applicable J1939-73 FMI detected in Engine Cylinder Head Bypass Actuator 1 by the manufacturer's software. When there are multiple failures…";
CM_ SG_ 2364592638 EngnClndrHdBpssAttr1Pstn "Actual position of Engine Cylinder Head Bypass actuator, where 0% represents fully closed and 100% represents fully open.Cylinder Head bypass valve is used to r…";
CM_ SG_ 2364592638 EngnClndrHdBpssAttr1Tmprtr "Temperature of the Engine Cylinder Head Bypass Actuator 1 drive circuitry. Temperature excursions may affect the torque output.Cylinder Head bypass valve is use…";
CM_ SG_ 2364592638 EngnClndrHdBpssAttr1TmprtrStts "Identifies the status of the Engine Cylinder Head Bypass Blowoff Actuator 1 drive circuitry temperature. Temperature excursions may affect the torque output.Cyl…";
CM_ BO_ 2364592894 "Engine Electronic Controller 18";
CM_ SG_ 2364592894 EngineIntakeAirSourceValve "Status of the actuator/valve in the airbox used to source engine intake air from either the engine compartment or external to the vehicle.00b = Off01b = On10b =…";
CM_ SG_ 2364592894 EngnClndrHdBpssAttr1Cmmnd "Command to cylinder head bypass actuator 1, normalized to percent, where 0% nominally represents fully closed (No Flow) and 100% represents fully open (Max Flow…";
CM_ SG_ 2364592894 EngnExhstGsRstrtnVlvPstn "The position of the exhaust gas restriction valve expressed as a percentage of full travel. 0% means the valve is closed and no exhaust gas is flowing into the …";
CM_ BO_ 2364593150 "Predictive Cruise Control 1";
CM_ SG_ 2364593150 PrdtvCrsCntrlDrvlnDsnggInhtRqst "Request to temporarily inhibit a fuel saving feature that would normally open the driveline. Under certain conditions and with knowledge of the terrain, inhibit…";
CM_ SG_ 2364593150 PrdtvCrsCntrlEvntnRng "Indicates that an event, such as a grade, is detected within the range of the predictive cruise control (PCC) look-ahead distance.00b = No PCC event in range01b…";
CM_ SG_ 2364593150 PrdtvCrsCntrlSpdEvntIndtr "Indicates to the operator that a predictive cruise control (PCC) speed event is active. Typically, this will correspond to a Predictive Cruise Control Set Speed…";
CM_ SG_ 2364593150 PrdtvCrsCntrlStSpdOffst "The amount by which the actual set point used by the cruise control algorithm should be changed as determined by external factors (e.g., anticipated road grade)…";
CM_ SG_ 2364593150 PredictiveCruiseControlState "Indicates the state of the PCC controller.If this parameter is 0001b, the cruise control set point may be modified by the Predictive Cruise Control Set Speed Of…";
CM_ SG_ 2364593150 RoadwayNextGrade "Road grade at an upcoming distance.  If SPN 9199 is supported, then this the road grade at the distance specified by SPN 9199. Positive numbers indicate uphill …";
CM_ SG_ 2364593150 RoadwayNextGradeDistance "The distance from the current vehicle position to the grade indicated in SPN 7433.…";
CM_ SG_ 2364593150 RoadwayPresentGrade "Road grade at present vehicle position. Positive numbers indicate uphill grade, negative are downhill for present vehicle direction of travel. For grades beyond…";
CM_ SG_ 2364593150 VhlSpdCntrlOvrrdEvntIndtr "Indicates to the operator that a Speed Control override event is active.  Speed Control refers to retarders or methods of automatically limiting vehicle speed, …";
CM_ SG_ 2364593150 VhlSpdCntrlOvrrdRqst "Speed control override requested. Indicates that the minimum restriction of speed is desired, for instance when travelling downhill towards an impending uphill …";
CM_ BO_ 2364597758 "Engine Ignition Timing Offset 1";
CM_ SG_ 2364597758 EngnClndr1IgntnTmngOffst "The ignition timing offset for Cylinder 1 from the engine timing advance (SPN 7355) as a command to the ignition control module. Positive values command an incr…";
CM_ SG_ 2364597758 EngnClndr2IgntnTmngOffst "The ignition timing offset for Cylinder 2 from the engine timing advance (SPN 7355) as a command to the ignition control module. Positive values command an incr…";
CM_ SG_ 2364597758 EngnClndr3IgntnTmngOffst "The ignition timing offset for Cylinder 3 from the engine timing advance (SPN 7355) as a command to the ignition control module. Positive values command an incr…";
CM_ SG_ 2364597758 EngnClndr4IgntnTmngOffst "The ignition timing offset for Cylinder 4 from the engine timing advance (SPN 7355) as a command to the ignition control module. Positive values command an incr…";
CM_ SG_ 2364597758 EngnClndr5IgntnTmngOffst "The ignition timing offset for Cylinder 5 from the engine timing advance (SPN 7355) as a command to the ignition control module. Positive values command an incr…";
CM_ SG_ 2364597758 EngnClndr6IgntnTmngOffst "The ignition timing offset for Cylinder 6 from the engine timing advance (SPN 7355) as a command to the ignition control module. Positive values command an incr…";
CM_ SG_ 2364597758 EngnClndr7IgntnTmngOffst "The ignition timing offset for Cylinder 7 from the engine timing advance (SPN 7355) as a command to the ignition control module. Positive values command an incr…";
CM_ SG_ 2364597758 EngnClndr8IgntnTmngOffst "The ignition timing offset for Cylinder 8 from the engine timing advance (SPN 7355) as a command to the ignition control module. Positive values command an incr…";
CM_ BO_ 2364598014 "Engine Ignition Timing Offset 2";
CM_ SG_ 2364598014 EngnClndr10IgntnTmngOffst "The ignition timing offset for Cylinder 10 from the engine timing advance (SPN 7355) as a command to the ignition control module. Positive values command an inc…";
CM_ SG_ 2364598014 EngnClndr11IgntnTmngOffst "The ignition timing offset for Cylinder 11 from the engine timing advance (SPN 7355) as a command to the ignition control module. Positive values command an inc…";
CM_ SG_ 2364598014 EngnClndr12IgntnTmngOffst "The ignition timing offset for Cylinder 12 from the engine timing advance (SPN 7355) as a command to the ignition control module. Positive values command an inc…";
CM_ SG_ 2364598014 EngnClndr13IgntnTmngOffst "The ignition timing offset for Cylinder 13 from the engine timing advance (SPN 7355) as a command to the ignition control module. Positive values command an inc…";
CM_ SG_ 2364598014 EngnClndr14IgntnTmngOffst "The ignition timing offset for Cylinder 14 from the engine timing advance (SPN 7355) as a command to the ignition control module. Positive values command an inc…";
CM_ SG_ 2364598014 EngnClndr15IgntnTmngOffst "The ignition timing offset for Cylinder 15 from the engine timing advance (SPN 7355) as a command to the ignition control module. Positive values command an inc…";
CM_ SG_ 2364598014 EngnClndr16IgntnTmngOffst "The ignition timing offset for Cylinder 16 from the engine timing advance (SPN 7355) as a command to the ignition control module. Positive values command an inc…";
CM_ SG_ 2364598014 EngnClndr9IgntnTmngOffst "The ignition timing offset for Cylinder 9 from the engine timing advance (SPN 7355) as a command to the ignition control module. Positive values command an incr…";
CM_ BO_ 2364598270 "Engine Ignition Timing Offset 3";
CM_ SG_ 2364598270 EngnClndr17IgntnTmngOffst "The ignition timing offset for Cylinder 17 from the engine timing advance (SPN 7355) as a command to the ignition control module. Positive values command an inc…";
CM_ SG_ 2364598270 EngnClndr18IgntnTmngOffst "The ignition timing offset for Cylinder 18 from the engine timing advance (SPN 7355) as a command to the ignition control module. Positive values command an inc…";
CM_ SG_ 2364598270 EngnClndr19IgntnTmngOffst "The ignition timing offset for Cylinder 19 from the engine timing advance (SPN 7355) as a command to the ignition control module. Positive values command an inc…";
CM_ SG_ 2364598270 EngnClndr20IgntnTmngOffst "The ignition timing offset for Cylinder 20 from the engine timing advance (SPN 7355) as a command to the ignition control module. Positive values command an inc…";
CM_ SG_ 2364598270 EngnClndr21IgntnTmngOffst "The ignition timing offset for Cylinder 21 from the engine timing advance (SPN 7355) as a command to the ignition control module. Positive values command an inc…";
CM_ SG_ 2364598270 EngnClndr22IgntnTmngOffst "The ignition timing offset for Cylinder 22 from the engine timing advance (SPN 7355) as a command to the ignition control module. Positive values command an inc…";
CM_ SG_ 2364598270 EngnClndr23IgntnTmngOffst "The ignition timing offset for Cylinder 23 from the engine timing advance (SPN 7355) as a command to the ignition control module. Positive values command an inc…";
CM_ SG_ 2364598270 EngnClndr24IgntnTmngOffst "The ignition timing offset for Cylinder 24 from the engine timing advance (SPN 7355) as a command to the ignition control module. Positive values command an inc…";
CM_ BO_ 2364598526 "Engine Throttle / Fuel Actuator Control Command 2";
CM_ SG_ 2364598526 EngnFlAttr3CntrlCmmnd "The control command to fuel actuator 3, normalized to percent, where 0% represents fully closed and 100% represents fully open.  Typically, this fuel actuator i…";
CM_ SG_ 2364598526 EngnFlAttr4CntrlCmmnd "The control command to fuel actuator 4, normalized to percent, where 0% represents fully closed and 100% represents fully open.  Typically, this fuel actuator i…";
CM_ BO_ 2364602878 "Engine Valve Controller";
CM_ SG_ 2364602878 EngnVlvCntrlMdl1PrlmnrFMI "Used to identify the applicable J1939-73 FMI detected in Engine Valve Control Module 1 by the manufacturer's software.  When there are multiple failures, the mo…";
CM_ SG_ 2364602878 EngnVlvCntrlMdl2PrlmnrFMI "Used to identify the applicable J1939-73 FMI detected in Engine Valve Control Module 2 by the manufacturer's software.  When there are multiple failures, the mo…";
CM_ SG_ 2364602878 EngnVlvCntrlMdl3PrlmnrFMI "Used to identify the applicable J1939-73 FMI detected in Engine Valve Control Module 3 by the manufacturer's software.  When there are multiple failures, the mo…";
CM_ SG_ 2364602878 EngnVlvCntrlMdl4PrlmnrFMI "Used to identify the applicable J1939-73 FMI detected in Engine Valve Control Module 4 by the manufacturer's software.  When there are multiple failures, the mo…";
CM_ SG_ 2364602878 EngnVlvCntrlMdl5PrlmnrFMI "Used to identify the applicable J1939-73 FMI detected in Engine Valve Control Module 5 by the manufacturer's software.  When there are multiple failures, the mo…";
CM_ SG_ 2364602878 EngnVlvCntrlMdl6PrlmnrFMI "Used to identify the applicable J1939-73 FMI detected in Engine Valve Control Module 6 by the manufacturer's software.  When there are multiple failures, the mo…";
CM_ SG_ 2364602878 EngnVlvCntrlMdl7PrlmnrFMI "Used to identify the applicable J1939-73 FMI detected in Engine Valve Control Module 7 by the manufacturer's software. When there are multiple failures, the mos…";
CM_ SG_ 2364602878 EngnVlvCntrlMdl8PrlmnrFMI "Used to identify the applicable J1939-73 FMI detected in Engine Valve Control Module 8 by the manufacturer's software.  When there are multiple failures, the mo…";
CM_ BO_ 2364603134 "Electronic Transmission Controller 13";
CM_ SG_ 2364603134 MxmmFrwrdTrnsmssnOtptShftSpd "Maximum transmission output shaft speed that can be achieved in the forward direction, based on current operating conditions.…";
CM_ SG_ 2364603134 MxmmRvrsTrnsmssnOtptShftSpd "Maximum transmission output shaft speed that can be achieved in the reverse direction, based on current operating conditions.…";
CM_ SG_ 2364603134 SAddssAtvPdTsssRqstdG "This parameter indicates the source address of the device whose SPN 525 [Transmission Requested Gear] request is currently being acted upon by the transmission.…";
CM_ BO_ 2364603390 "Aftertreatment 1 SCR Dosing System Requests 3";
CM_ SG_ 2364603390 Atttt1DsExstFdDsVv1Cd "Command (in percent) sent to the diesel exhaust fluid (DEF) injector to control the amount of DEF being injected into the aftreatment exhaust stream.0% closes t…";
CM_ SG_ 2364603390 Atttt1DsExstFdRqstdQttIttHRst "Represents the command for the diesel exhaust fluid quantity integrator in the dosing control unit. See SPN 4350 for alternate resolution.…";
CM_ BO_ 2364603646 "Aftertreatment 2 SCR Dosing System Requests 3";
CM_ SG_ 2364603646 Atttt2DsExstFdRqstdQttIttHRst "Represents the command for the diesel exhaust fluid quantity integrator in the dosing control unit. See SPN 4403 for alternate resolution.…";
CM_ BO_ 2364603902 "Aftertreatment 1 SCR Dosing System Information 4";
CM_ SG_ 2364603902 Atttt1DsExstFdAtQttIttHRst "The SCR requested diesel exhaust fluid integrator total quantity for aftertreatment system 1 (exhaust bank 1).  See SPN 4333 for alternate resolution.…";
CM_ BO_ 2364604158 "Aftertreatment 2 SCR Dosing System Information 4";
CM_ SG_ 2364604158 Atttt2DsExstFdAtQttIttHRst "The SCR requested diesel exhaust fluid integrator total quantity for aftertreatment system 2 (exhaust bank 2).  See SPN 4386 for alternate resolution.…";
CM_ BO_ 2364605438 "Generator Trip Energy";
CM_ SG_ 2364605438 GeneratorTripkVArHoursExport "The trip AC reactive energy exported by the generstor since the last reset of the trip kVArh meter.This value will be reset by the user at will.…";
CM_ SG_ 2364605438 GeneratorTripkWHoursExport "The total kilowatt-hours that have been exported by the generator since the last reset of the trip kWh meter.This value will be reset by the user at will.…";
CM_ BO_ 2364605950 "Hydraulic Pressure Displacement";
CM_ SG_ 2364605950 HydraulicLinePressure "The pressure of the hydraulic fluid, measured in the hydraulic line.…";
CM_ SG_ 2364605950 MechanicalMovementAngle "The angle of rotation of the mechanical component.The increase and decrease of the value (i.e. rotation about the X-axis) is in accordance to the right-hand rul…";
CM_ BO_ 2364606718 "High Voltage Energy Storage 1 Module Status 1";
CM_ SG_ 2364606718 HVES1Module10OperationalStatus "Operational Status of the High Voltage Energy Storage 1 Module 10.  Not Operational is used when the module is initializing or not able to function (e.g. intern…";
CM_ SG_ 2364606718 HVES1Module11OperationalStatus "Operational Status of the High Voltage Energy Storage 1 Module 11.  Not Operational is used when the module is initializing or not able to function (e.g. intern…";
CM_ SG_ 2364606718 HVES1Module12OperationalStatus "Operational Status of the High Voltage Energy Storage 1 Module 12.  Not Operational is used when the module is initializing or not able to function (e.g. intern…";
CM_ SG_ 2364606718 HVES1Module13OperationalStatus "Operational Status of the High Voltage Energy Storage 1 Module 13.  Not Operational is used when the module is initializing or not able to function (e.g. intern…";
CM_ SG_ 2364606718 HVES1Module14OperationalStatus "Operational Status of the High Voltage Energy Storage 1 Module 14.  Not Operational is used when the module is initializing or not able to function (e.g. intern…";
CM_ SG_ 2364606718 HVES1Module15OperationalStatus "Operational Status of the High Voltage Energy Storage 1 Module 15.  Not Operational is used when the module is initializing or not able to function (e.g. intern…";
CM_ SG_ 2364606718 HVES1Module16OperationalStatus "Operational Status of the High Voltage Energy Storage 1 Module 16.  Not Operational is used when the module is initializing or not able to function (e.g. intern…";
CM_ SG_ 2364606718 HVES1Module1OperationalStatus "Operational Status of the High Voltage Energy Storage 1 Module 1.  Not Operational is used when the module is initializing or not able to function (e.g. interna…";
CM_ SG_ 2364606718 HVES1Module2OperationalStatus "Operational Status of the High Voltage Energy Storage 1 Module 2.  Not Operational is used when the module is initializing or not able to function (e.g. interna…";
CM_ SG_ 2364606718 HVES1Module3OperationalStatus "Operational Status of the High Voltage Energy Storage 1 Module 3.  Not Operational is used when the module is initializing or not able to function (e.g. interna…";
CM_ SG_ 2364606718 HVES1Module4OperationalStatus "Operational Status of the High Voltage Energy Storage 1 Module 4.  Not Operational is used when the module is initializing or not able to function (e.g. interna…";
CM_ SG_ 2364606718 HVES1Module5OperationalStatus "Operational Status of the High Voltage Energy Storage 1 Module 5.  Not Operational is used when the module is initializing or not able to function (e.g. interna…";
CM_ SG_ 2364606718 HVES1Module6OperationalStatus "Operational Status of the High Voltage Energy Storage 1 Module 6.  Not Operational is used when the module is initializing or not able to function (e.g. interna…";
CM_ SG_ 2364606718 HVES1Module7OperationalStatus "Operational Status of the High Voltage Energy Storage 1 Module 7.  Not Operational is used when the module is initializing or not able to function (e.g. interna…";
CM_ SG_ 2364606718 HVES1Module8OperationalStatus "Operational Status of the High Voltage Energy Storage 1 Module 8.  Not Operational is used when the module is initializing or not able to function (e.g. interna…";
CM_ SG_ 2364606718 HVES1Module9OperationalStatus "Operational Status of the High Voltage Energy Storage 1 Module 9.  Not Operational is used when the module is initializing or not able to function (e.g. interna…";
CM_ BO_ 2364606974 "High Voltage Energy Storage 1 Thermal Management System Status 1";
CM_ SG_ 2364606974 HVES1ThrmlMngmntSstmCmprssrSpd "When the High Voltage Energy Storage 1 Thermal Management System is equipped with an active cooling system (e.g. air conditioner), this is the Compressor Speed.…";
CM_ SG_ 2364606974 HVES1ThrmlMngmntSstmHtrStts "This is the state of the High Voltage Energy Storage 1 heater00b = Heater Off01b = Heater On10b = Error 11b = Not Available…";
CM_ SG_ 2364606974 HVES1ThrmlMngmntSstmMd "Indicates the operating mode of the Thermal Management System.  The heat transfer medium may be (e.g. liquid or air).  The cooling system may be fans, liquid co…";
CM_ SG_ 2364606974 HVES1ThrmlMngmntSstmRltvHmdt "When the High Voltage Energy Storage 1 Thermal Management System is equipped with a relative humidity sensor, this is the  measured Relative Humidity.…";
CM_ SG_ 2364606974 HVES1ThrmlMngmntSstmSLIInptPwr "In multiple HVES configurations, this is the low-voltage power consumed by the HVES1 Thermal Management System (TMS).   If there is only one HVES, or a single T…";
CM_ SG_ 2364606974 HVES1TMtSstHVtIptPw "In multiple HVES configurations, this is the high-voltage power consumed by the HVES1 Thermal Management System (TMS).   If there is only one HVES, or a single …";
CM_ BO_ 2364607230 "High Voltage Energy Storage 1 Data 8";
CM_ SG_ 2364607230 HVES1AverageCellVoltage "The average cell voltage in the High Voltage Energy Storage 1 pack (or system).…";
CM_ SG_ 2364607230 HVES1HghstCllVltgCllNmr "Identifies the location of HVES1 Highest Cell Voltage (SPN 5922) within the HVES1 Highest Cell Voltage Module Number (SPN 8236).…";
CM_ SG_ 2364607230 HVES1HghstCllVltgMdlNmr "Identifies the location of the module containing the HVES1 Highest Cell Voltage (SPN 5922).…";
CM_ SG_ 2364607230 HVES1LwstCllVltgCllNmr "Identifies the location of the HVES1 Lowest Cell Voltage (SPN 5923) within the HVES1 Lowest Cell Voltage Module Number (SPN 8238).…";
CM_ SG_ 2364607230 HVES1LwstCllVltgMdlNmr "Identifies the location of the module containing the HVES1 Lowest Cell Voltage (SPN 5923).…";
CM_ BO_ 2364607486 "High Voltage Energy Storage 1 Data 9";
CM_ SG_ 2364607486 HVES1HghstCllTmprtrCllNmr "Identifies the location of the HVES1 Highest Cell Temperature (SPN 8075) within the HVES1 Highest Cell Temperature Module Number (SPN 8241).…";
CM_ SG_ 2364607486 HVES1HghstCllTmprtrMdlNmr "Identifies the location of the module containing the HVES1 Highest Cell Temperature (SPN 8075).…";
CM_ SG_ 2364607486 HVES1LwstCllTmprtrCllNmr "Identifies the location of the HVES1 Lowest Cell Temperature (SPN 8076) within the HVES1 Lowest Cell Temperature Module Number (SPN 8243).…";
CM_ SG_ 2364607486 HVES1LwstCllTmprtrMdlNmr "Identifies the location of the module containing the HVES1 Lowest Cell Temperature (SPN 8076).…";
CM_ BO_ 2364607742 "High Voltage Energy Storage 1 Data 10";
CM_ SG_ 2364607742 HVES1HghstCllSttfChrgCllNmr "Identifies the location of the HVES1 Highest Cell State of Charge (SPN 8085) within the HVES1 Highest Cell State of Charge Module Number (SPN 8245).…";
CM_ SG_ 2364607742 HVES1HghstCllSttfChrgMdlNmr "Identifies the location of the module containing the HVES1 Highest Cell State of Charge (SPN 8085).…";
CM_ SG_ 2364607742 HVES1HghVltgBsAtvIsltnTstRslts "The isolation resistance expressed in Ohms per Volt that resulted from the High-Voltage Bus Active Isolation Test.See HVES1 High-Voltage Bus Active Isolation Te…";
CM_ SG_ 2364607742 HVES1HghVltgBsPssvIsltnTstRslts "The isolation resistance expressed in Ohms per Volt that resulted from the High-Voltage Bus Passive Isolation Test.See HVES1 High-Voltage Bus Passive Isolation …";
CM_ SG_ 2364607742 HVES1LwstCllSttfChrgCllNmr "Identifies the location of the HVES1 Lowest Cell State of Charge (SPN 8084) within the HVES1 Lowest Cell State of Charge Module Number (SPN 8247).…";
CM_ SG_ 2364607742 HVES1LwstCllSttfChrgMdlNmr "Identifies the location of the module containing the HVES1 Lowest Cell State of Charge (SPN 8084).…";
CM_ BO_ 2364608510 "Engine Operating Information 2";
CM_ SG_ 2364608510 EnginePowerDerateRequest "Derate request made from the engine control system to an external system, where the engine is requesting an external device to reduce the load being applied. A …";
CM_ SG_ 2364608510 EngineSelfInducedDerateLoad "The self-induced derate load that the Engine Control Module is trying to achieve.  A value of 0% means there is no active derate.…";
CM_ BO_ 2364609278 "DC/DC Converter 1 Control";
CM_ SG_ 2364609278 DCDC1HghSdVltgBstStpnt "The set point for regulating the high side voltage during boost mode.…";
CM_ SG_ 2364609278 DCDC1LowSideVoltageBuckSetpoint "The set point for regulating the low side voltage during buck mode.…";
CM_ SG_ 2364609278 DCDC1LwSdVltgBkDfltStpnt "The set point for the converter default low side voltage during buck mode.   This setting may be used for when communication has been lost with the controlling …";
CM_ SG_ 2364609278 DCDC1OperationalCommand "Command to enable or disable operation.0000b = Disable - in this mode all high voltage switching is disabled0001b = Operate in standby mode; system is waiting f…";
CM_ BO_ 2364609534 "DC/DC Converter 1 Operating Status";
CM_ SG_ 2364609534 DCDC1HVILStatus "High Voltage Interlock Loop (HVIL) state of the DC/DC Converter.00b = HVIL Closed01b = HVIL Open10b = Error11b = Not Available…";
CM_ SG_ 2364609534 DCDC1LoadshedRequest "The loadshed request is a request to the controlling device to reduce the DC/DC Converter loads.  The Loadshed Requested state is an indication that this DC/DC …";
CM_ SG_ 2364609534 DCDC1OperationalStatus "Operating state of the DC/DC Converter0000b = Disabled 0001b = Initialization in process.  The device is powering up.  This process may include both internal ch…";
CM_ SG_ 2364609534 DCDC1PwrLmtdtCnvrtrTmprtr "Indicates whether or not output power is being limited due to Converter Temperature (see SPN 8592) approaching or exceeding the maximum limit.00b = No power lim…";
CM_ SG_ 2364609534 DCDC1PwrLmtdtEltrnFltrTmprtr "Indicates whether or not output power is being limited due to Output Electronic Filter Temperature (see SPN 8693) approaching or exceeding the maximum limit.00b…";
CM_ SG_ 2364609534 DCDC1PwrLmtdtHghSdCrrnt "Indicates whether or not output power is being limited due to high side current (see SPN 8588) approaching or exceeding the maximum limit (see SPN 8565).00b = N…";
CM_ SG_ 2364609534 DCDC1PwrLmtdtHghSdVltgMnmm "Indicates whether or not output power is being limited due to high side voltage (see SPN 8587) approaching or falling below the minimum limit (see SPN 8563).00b…";
CM_ SG_ 2364609534 DCDC1PwrLmtdtHghSdVltgMxmm "Indicates whether or not output power is being limited due to high side voltage (see SPN 8587) approaching or exceeding the maximum limit (see SPN 8564).00b = N…";
CM_ SG_ 2364609534 DCDC1PwrLmtdtLwSdCrrnt "Indicates whether or not output power is being limited due to low side current (see SPN 8586) approaching or exceeding the maximum limit (see SPN 8568).00b = No…";
CM_ SG_ 2364609534 DCDC1PwrLmtdtLwSdVltgMnmm "Indicates whether or not output power is being limited due to low side voltage (see SPN 8585) approaching or falling below the minimum limit (see SPN 8566).00b …";
CM_ SG_ 2364609534 DCDC1PwrLmtdtLwSdVltgMxmm "Indicates whether or not output power is being limited due to low side voltage (see SPN 8585) approaching or exceeding the maximum limit (see SPN 8567).00b = No…";
CM_ SG_ 2364609534 DCDC1PwrLmtdtPwrEltrnsTmprtr "Indicates whether or not output power is being limited due to Power Electronics Temperature (see SPN 8594) approaching or exceeding the maximum limit.00b = No p…";
CM_ SG_ 2364609534 DCDC1PwrLmtdtSLIBttrTrmnlCrrnt "Indicates whether or not output power is being limited due to the SLI battery terminal current (see SPN 8590) approaching or exceeding limits (see SPN 8818).00b…";
CM_ SG_ 2364609534 DCDC1PwrLmtdtSLIBttrTrmnlTmprtr "Indicates whether or not output power is being limited due to the SLI battery terminal temperature (see SPN 8591) approaching or exceeding limits (see SPN 8819)…";
CM_ SG_ 2364609534 DCDC1PwrLmtdtSLIBttrTrmnlVltg "Indicates whether or not output power is being limited due to the SLI battery terminal voltage (see SPN 8589) approaching or exceeding limits (see SPN 8817).00b…";
CM_ SG_ 2364609534 DCDC1PwrLmtdtUndfndRsn "Indicates whether or not output power is being limited due to an undefined reason.00b = No power limit for this reason01b = Power limited for this reason10b = E…";
CM_ BO_ 2364609790 "DC/DC Converter 1 Voltage and Current";
CM_ SG_ 2364609790 DCDC1HighSideCurrent "Indicates the measured HVES or high side current measured at the point of control inside the DC/DC Converter.  The current is negative if the converter is charg…";
CM_ SG_ 2364609790 DCDC1HighSideVoltage "Indicates the measured HVES or high side voltage measured at the point of control inside the DC/DC Converter.…";
CM_ SG_ 2364609790 DCDC1LowSideCurrent "Indicates the measured SLI battery or low side current measured at the point of control inside the DC/DC Converter.  The current is positive if the converter is…";
CM_ SG_ 2364609790 DCDC1LowSideVoltage "Indicates the measured SLI battery or low side voltage measured at the point of control inside the DC/DC Converter.…";
CM_ BO_ 2364610046 "DC/DC Converter 1 SLI Battery Status";
CM_ SG_ 2364610046 DCDC1SLIBatteryTerminalCurrent "Parameter indicating the SLI battery terminal current for control use by the DC/DC converter.  The current is positive if the SLI battery or low side voltage so…";
CM_ SG_ 2364610046 DCDC1SLIBatteryTerminalVoltage "Parameter indicating the SLI battery terminal voltage for control use by the DC/DC converter.…";
CM_ SG_ 2364610046 DCDC1SLIBttrTrmnlTmprtr "Parameter indicating the SLI battery terminal temperature for control use by the DC/DC converter.…";
CM_ BO_ 2364610558 "DC/DC Converter 1 Status 2";
CM_ SG_ 2364610558 DCDC1HighSidePower "Indicates the measured HVES or high side power measured at the DC/DC Converter.  The high side power is positive if the converter is charging the hybrid battery…";
CM_ SG_ 2364610558 DCDC1LowSidePower "Indicates the measured SLI battery or low side power measured at the DC/DC Converter.  The low side power is positive if the converter is charging the SLI batte…";
CM_ SG_ 2364610558 DCDC1HghSdNgtvtChsssGrndVltg "The voltage level of the high voltage DC side, as measured by the DC/DC between the negative side of the High Voltage DC Side input and the chassis of the DC/DC…";
CM_ BO_ 2364610814 "DC/DC Converter 2 Control";
CM_ SG_ 2364610814 DCDC2HghSdVltgBstStpnt "The set point for regulating the high side voltage during boost mode.…";
CM_ SG_ 2364610814 DCDC2LowSideVoltageBuckSetpoint "The set point for regulating the low side voltage during buck mode.…";
CM_ SG_ 2364610814 DCDC2LwSdVltgBkDfltStpnt "The set point for the converter default low side voltage during buck mode.   This setting may be used for when communication has been lost with the controlling …";
CM_ SG_ 2364610814 DCDC2OperationalCommand "Command to enable or disable operation.0000b = Disable - in this mode all high voltage switching is disabled0001b = Operate in standby mode; system is waiting f…";
CM_ BO_ 2364611070 "DC/DC Converter 2 Operating Status";
CM_ SG_ 2364611070 DCDC2HVILStatus "High Voltage Interlock Loop (HVIL) state of the DC/DC Converter.00b = HVIL Closed01b = HVIL Open10b = Error11b = Not Available…";
CM_ SG_ 2364611070 DCDC2LoadshedRequest "The loadshed request is a request to the controlling device to reduce the DC/DC Converter loads.  The Loadshed Requested state is an indication that this DC/DC …";
CM_ SG_ 2364611070 DCDC2OperationalStatus "Operating state of the DC/DC Converter0000b = Disabled 0001b = Initialization in process.  The device is powering up.  This process may include both internal ch…";
CM_ SG_ 2364611070 DCDC2PwrLmtdtCnvrtrTmprtr "Indicates whether or not output power is being limited due to Converter Temperature (see SPN 8936) approaching or exceeding the maximum limit.00b = No power lim…";
CM_ SG_ 2364611070 DCDC2PwrLmtdtEltrnFltrTmprtr "Indicates whether or not output power is being limited due to Output Electronic Filter Temperature (see SPN 8937) approaching or exceeding the maximum limit.00b…";
CM_ SG_ 2364611070 DCDC2PwrLmtdtHghSdCrrnt "Indicates whether or not output power is being limited due to high side current (see SPN 8914) approaching or exceeding the maximum limit (see SPN 8946).00b = N…";
CM_ SG_ 2364611070 DCDC2PwrLmtdtHghSdVltgMnmm "Indicates whether or not output power is being limited due to high side voltage (see SPN 8913) approaching or falling below the minimum limit (see SPN 8944).00b…";
CM_ SG_ 2364611070 DCDC2PwrLmtdtHghSdVltgMxmm "Indicates whether or not output power is being limited due to high side voltage (see SPN 8913) approaching or exceeding the maximum limit (see SPN 8945).00b = N…";
CM_ SG_ 2364611070 DCDC2PwrLmtdtLwSdCrrnt "Indicates whether or not output power is being limited due to low side current (see SPN 8912) approaching or exceeding the maximum limit (see SPN 8943).00b = No…";
CM_ SG_ 2364611070 DCDC2PwrLmtdtLwSdVltgMnmm "Indicates whether or not output power is being limited due to low side voltage (see SPN 8911) approaching or falling below the minimum limit (see SPN 8941).00b …";
CM_ SG_ 2364611070 DCDC2PwrLmtdtLwSdVltgMxmm "Indicates whether or not output power is being limited due to low side voltage (see SPN 8911) approaching or exceeding the maximum limit (see SPN 8942).00b = No…";
CM_ SG_ 2364611070 DCDC2PwrLmtdtPwrEltrnsTmprtr "Indicates whether or not output power is being limited due to Power Electronics Temperature (see SPN 8938) approaching or exceeding the maximum limit.00b = No p…";
CM_ SG_ 2364611070 DCDC2PwrLmtdtSLIBttrTrmnlCrrnt "Indicates whether or not output power is being limited due to the SLI battery terminal current (see SPN 8916) approaching or exceeding limits (see SPN 8934).00b…";
CM_ SG_ 2364611070 DCDC2PwrLmtdtSLIBttrTrmnlTmprtr "Indicates whether or not output power is being limited due to the SLI battery terminal temperature (see SPN 8917) approaching or exceeding limits (see SPN 8935)…";
CM_ SG_ 2364611070 DCDC2PwrLmtdtSLIBttrTrmnlVltg "Indicates whether or not output power is being limited due to the SLI battery terminal voltage (see SPN 8915) approaching or exceeding limits (see SPN 8933).00b…";
CM_ SG_ 2364611070 DCDC2PwrLmtdtUndfndRsn "Indicates whether or not output power is being limited due to an undefined reason.00b = No power limit for this reason01b = Power limited for this reason10b = E…";
CM_ BO_ 2364611326 "DC/DC Converter 2 Voltage and Current";
CM_ SG_ 2364611326 DCDC2HighSideCurrent "Indicates the measured HVES or high side current measured at the point of control inside the DC/DC Converter.  The current is negative if the converter is charg…";
CM_ SG_ 2364611326 DCDC2HighSideVoltage "Indicates the measured HVES or high side voltage measured at the point of control inside the DC/DC Converter.…";
CM_ SG_ 2364611326 DCDC2LowSideCurrent "Indicates the measured SLI battery or low side current measured at the point of control inside the DC/DC Converter.  The current is positive if the converter is…";
CM_ SG_ 2364611326 DCDC2LowSideVoltage "Indicates the measured SLI battery or low side voltage measured at the point of control inside the DC/DC Converter.…";
CM_ BO_ 2364611582 "DC/DC Converter 2 SLI Battery Status";
CM_ SG_ 2364611582 DCDC2SLIBatteryTerminalCurrent "Parameter indicating the SLI battery terminal current for control use by the DC/DC converter.  The current is positive if the SLI battery or low side voltage so…";
CM_ SG_ 2364611582 DCDC2SLIBatteryTerminalVoltage "Parameter indicating the SLI battery terminal voltage for control use by the DC/DC converter.…";
CM_ SG_ 2364611582 DCDC2SLIBttrTrmnlTmprtr "Parameter indicating the SLI battery terminal temperature for control use by the DC/DC converter.…";
CM_ BO_ 2364611838 "DC/DC Converter 2 Status 2";
CM_ SG_ 2364611838 DCDC2HighSidePower "Indicates the measured HVES or high side power measured at the DC/DC Converter.  The high side power is positive if the converter is charging the hybrid battery…";
CM_ SG_ 2364611838 DCDC2LowSidePower "Indicates the measured SLI battery or low side power measured at the DC/DC Converter.  The low side power is positive if the converter is charging the SLI batte…";
CM_ SG_ 2364611838 DCDC2HghSdNgtvtChsssGrndVltg "The voltage level of the high voltage DC side, as measured by the DC/DC between the negative side of the High Voltage DC Side input and the chassis of the DC/DC…";
CM_ BO_ 2364612094 "DC/DC Converter 3 Control";
CM_ SG_ 2364612094 DCDC3HghSdVltgBstStpnt "The set point for regulating the high side voltage during boost mode.…";
CM_ SG_ 2364612094 DCDC3LowSideVoltageBuckSetpoint "The set point for regulating the low side voltage during buck mode.…";
CM_ SG_ 2364612094 DCDC3LwSdVltgBkDfltStpnt "The set point for the converter default low side voltage during buck mode.   This setting may be used for when communication has been lost with the controlling …";
CM_ SG_ 2364612094 DCDC3OperationalCommand "Command to enable or disable operation.0000b = Disable - in this mode all high voltage switching is disabled0001b = Operate in standby mode; system is waiting f…";
CM_ BO_ 2364612350 "DC/DC Converter 3 Operating Status";
CM_ SG_ 2364612350 DCDC3HVILStatus "High Voltage Interlock Loop (HVIL) state of the DC/DC Converter.00b = HVIL Closed01b = HVIL Open10b = Error11b = Not Available…";
CM_ SG_ 2364612350 DCDC3LoadshedRequest "The loadshed request is a request to the controlling device to reduce the DC/DC Converter loads.  The Loadshed Requested state is an indication that this DC/DC …";
CM_ SG_ 2364612350 DCDC3OperationalStatus "Operating state of the DC/DC Converter0000b = Disabled 0001b = Initialization in process.  The device is powering up.  This process may include both internal ch…";
CM_ SG_ 2364612350 DCDC3PwrLmtdtCnvrtrTmprtr "Indicates whether or not output power is being limited due to Converter Temperature (see SPN 8991) approaching or exceeding the maximum limit.00b = No power lim…";
CM_ SG_ 2364612350 DCDC3PwrLmtdtEltrnFltrTmprtr "Indicates whether or not output power is being limited due to Output Electronic Filter Temperature (see SPN 8992) approaching or exceeding the maximum limit.00b…";
CM_ SG_ 2364612350 DCDC3PwrLmtdtHghSdCrrnt "Indicates whether or not output power is being limited due to high side current (see SPN 8969) approaching or exceeding the maximum limit (see SPN 9001).00b = N…";
CM_ SG_ 2364612350 DCDC3PwrLmtdtHghSdVltgMnmm "Indicates whether or not output power is being limited due to high side voltage (see SPN 8968) approaching or falling below the minimum limit (see SPN 8999).00b…";
CM_ SG_ 2364612350 DCDC3PwrLmtdtHghSdVltgMxmm "Indicates whether or not output power is being limited due to high side voltage (see SPN 8968) approaching or exceeding the maximum limit (see SPN 9000).00b = N…";
CM_ SG_ 2364612350 DCDC3PwrLmtdtLwSdCrrnt "Indicates whether or not output power is being limited due to low side current (see SPN 8967) approaching or exceeding the maximum limit (see SPN 8998).00b = No…";
CM_ SG_ 2364612350 DCDC3PwrLmtdtLwSdVltgMnmm "Indicates whether or not output power is being limited due to low side voltage (see SPN 8966) approaching or falling below the minimum limit (see SPN 8996).00b …";
CM_ SG_ 2364612350 DCDC3PwrLmtdtLwSdVltgMxmm "Indicates whether or not output power is being limited due to low side voltage (see SPN 8966) approaching or exceeding the maximum limit (see SPN 8997).00b = No…";
CM_ SG_ 2364612350 DCDC3PwrLmtdtPwrEltrnsTmprtr "Indicates whether or not output power is being limited due to Power Electronics Temperature (see SPN 8993) approaching or exceeding the maximum limit.00b = No p…";
CM_ SG_ 2364612350 DCDC3PwrLmtdtSLIBttrTrmnlCrrnt "Indicates whether or not output power is being limited due to the SLI battery terminal current (see SPN 8971) approaching or exceeding limits (see SPN 8989).00b…";
CM_ SG_ 2364612350 DCDC3PwrLmtdtSLIBttrTrmnlTmprtr "Indicates whether or not output power is being limited due to the SLI battery terminal temperature (see SPN 8972) approaching or exceeding limits (see SPN 8990)…";
CM_ SG_ 2364612350 DCDC3PwrLmtdtSLIBttrTrmnlVltg "Indicates whether or not output power is being limited due to the SLI battery terminal voltage (see SPN 8970) approaching or exceeding limits (see SPN 8988).00b…";
CM_ SG_ 2364612350 DCDC3PwrLmtdtUndfndRsn "Indicates whether or not output power is being limited due to an undefined reason.00b = No power limit for this reason01b = Power limited for this reason10b = E…";
CM_ BO_ 2364612606 "DC/DC Converter 3 Voltage and Current";
CM_ SG_ 2364612606 DCDC3HighSideCurrent "Indicates the measured HVES or high side current measured at the point of control inside the DC/DC Converter.  The current is negative if the converter is charg…";
CM_ SG_ 2364612606 DCDC3HighSideVoltage "Indicates the measured HVES or high side voltage measured at the point of control inside the DC/DC Converter.…";
CM_ SG_ 2364612606 DCDC3LowSideCurrent "Indicates the measured SLI battery or low side current measured at the point of control inside the DC/DC Converter.  The current is positive if the converter is…";
CM_ SG_ 2364612606 DCDC3LowSideVoltage "Indicates the measured SLI battery or low side voltage measured at the point of control inside the DC/DC Converter.…";
CM_ BO_ 2364612862 "DC/DC Converter 3 SLI Battery Status";
CM_ SG_ 2364612862 DCDC3SLIBatteryTerminalCurrent "Parameter indicating the SLI battery terminal current for control use by the DC/DC converter.  The current is positive if the SLI battery or low side voltage so…";
CM_ SG_ 2364612862 DCDC3SLIBatteryTerminalVoltage "Parameter indicating the SLI battery terminal voltage for control use by the DC/DC converter.…";
CM_ SG_ 2364612862 DCDC3SLIBttrTrmnlTmprtr "Parameter indicating the SLI battery terminal temperature for control use by the DC/DC converter.…";
CM_ BO_ 2364613118 "DC/DC Converter 3 Status 2";
CM_ SG_ 2364613118 DCDC3HighSidePower "Indicates the measured HVES or high side power measured at the DC/DC Converter.  The high side power is positive if the converter is charging the hybrid battery…";
CM_ SG_ 2364613118 DCDC3LowSidePower "Indicates the measured SLI battery or low side power measured at the DC/DC Converter.  The low side power is positive if the converter is charging the SLI batte…";
CM_ SG_ 2364613118 DCDC3HghSdNgtvtChsssGrndVltg "The voltage level of the high voltage DC side, as measured by the DC/DC between the negative side of the High Voltage DC Side input and the chassis of the DC/DC…";
CM_ BO_ 2364613374 "DC/DC Converter 4 Control";
CM_ SG_ 2364613374 DCDC4HghSdVltgBstStpnt "The set point for regulating the high side voltage during boost mode.…";
CM_ SG_ 2364613374 DCDC4LowSideVoltageBuckSetpoint "The set point for regulating the low side voltage during buck mode.…";
CM_ SG_ 2364613374 DCDC4LwSdVltgBkDfltStpnt "The set point for the converter default low side voltage during buck mode.   This setting may be used for when communication has been lost with the controlling …";
CM_ SG_ 2364613374 DCDC4OperationalCommand "Command to enable or disable operation.0000b = Disable - in this mode all high voltage switching is disabled0001b = Operate in standby mode; system is waiting f…";
CM_ BO_ 2364613630 "DC/DC Converter 4 Operating Status";
CM_ SG_ 2364613630 DCDC4HVILStatus "High Voltage Interlock Loop (HVIL) state of the DC/DC Converter.00b = HVIL Closed01b = HVIL Open10b = Error11b = Not Available…";
CM_ SG_ 2364613630 DCDC4LoadshedRequest "The loadshed request is a request to the controlling device to reduce the DC/DC Converter loads.  The Loadshed Requested state is an indication that this DC/DC …";
CM_ SG_ 2364613630 DCDC4OperationalStatus "Operating state of the DC/DC Converter0000b = Disabled 0001b = Initialization in process.  The device is powering up.  This process may include both internal ch…";
CM_ SG_ 2364613630 DCDC4PwrLmtdtCnvrtrTmprtr "Indicates whether or not output power is being limited due to Converter Temperature (see SPN 9046) approaching or exceeding the maximum limit.00b = No power lim…";
CM_ SG_ 2364613630 DCDC4PwrLmtdtEltrnFltrTmprtr "Indicates whether or not output power is being limited due to Output Electronic Filter Temperature (see SPN 9047) approaching or exceeding the maximum limit.00b…";
CM_ SG_ 2364613630 DCDC4PwrLmtdtHghSdCrrnt "Indicates whether or not output power is being limited due to high side current (see SPN 9024) approaching or exceeding the maximum limit (see SPN 9056).00b = N…";
CM_ SG_ 2364613630 DCDC4PwrLmtdtHghSdVltgMnmm "Indicates whether or not output power is being limited due to high side voltage (see SPN 9023) approaching or falling below the minimum limit (see SPN 9054).00b…";
CM_ SG_ 2364613630 DCDC4PwrLmtdtHghSdVltgMxmm "Indicates whether or not output power is being limited due to high side voltage (see SPN 9023) approaching or exceeding the maximum limit (see SPN 9055).00b = N…";
CM_ SG_ 2364613630 DCDC4PwrLmtdtLwSdCrrnt "Indicates whether or not output power is being limited due to low side current (see SPN 9022) approaching or exceeding the maximum limit (see SPN 9053).00b = No…";
CM_ SG_ 2364613630 DCDC4PwrLmtdtLwSdVltgMnmm "Indicates whether or not output power is being limited due to low side voltage (see SPN 9021) approaching or falling below the minimum limit (see SPN 9051).00b …";
CM_ SG_ 2364613630 DCDC4PwrLmtdtLwSdVltgMxmm "Indicates whether or not output power is being limited due to low side voltage (see SPN 9021) approaching or exceeding the maximum limit (see SPN 9052).00b = No…";
CM_ SG_ 2364613630 DCDC4PwrLmtdtPwrEltrnsTmprtr "Indicates whether or not output power is being limited due to Power Electronics Temperature (see SPN 9048) approaching or exceeding the maximum limit.00b = No p…";
CM_ SG_ 2364613630 DCDC4PwrLmtdtSLIBttrTrmnlCrrnt "Indicates whether or not output power is being limited due to the SLI battery terminal current (see SPN 9026) approaching or exceeding limits (see SPN 9044).00b…";
CM_ SG_ 2364613630 DCDC4PwrLmtdtSLIBttrTrmnlTmprtr "Indicates whether or not output power is being limited due to the SLI battery terminal temperature (see SPN 9027) approaching or exceeding limits (see SPN 9045)…";
CM_ SG_ 2364613630 DCDC4PwrLmtdtSLIBttrTrmnlVltg "Indicates whether or not output power is being limited due to the SLI battery terminal voltage (see SPN 9025) approaching or exceeding limits (see SPN 9043).00b…";
CM_ SG_ 2364613630 DCDC4PwrLmtdtUndfndRsn "Indicates whether or not output power is being limited due to an undefined reason.00b = No power limit for this reason01b = Power limited for this reason10b = E…";
CM_ BO_ 2364613886 "DC/DC Converter 4 Voltage and Current";
CM_ SG_ 2364613886 DCDC4HighSideCurrent "Indicates the measured HVES or high side current measured at the point of control inside the DC/DC Converter.  The current is negative if the converter is charg…";
CM_ SG_ 2364613886 DCDC4HighSideVoltage "Indicates the measured HVES or high side voltage measured at the point of control inside the DC/DC Converter.…";
CM_ SG_ 2364613886 DCDC4LowSideCurrent "Indicates the measured SLI battery or low side current measured at the point of control inside the DC/DC Converter.  The current is positive if the converter is…";
CM_ SG_ 2364613886 DCDC4LowSideVoltage "Indicates the measured SLI battery or low side voltage measured at the point of control inside the DC/DC Converter.…";
CM_ BO_ 2364614142 "DC/DC Converter 4 SLI Battery Status";
CM_ SG_ 2364614142 DCDC4SLIBatteryTerminalCurrent "Parameter indicating the SLI battery terminal current for control use by the DC/DC converter.  The current is positive if the SLI battery or low side voltage so…";
CM_ SG_ 2364614142 DCDC4SLIBatteryTerminalVoltage "Parameter indicating the SLI battery terminal voltage for control use by the DC/DC converter.…";
CM_ SG_ 2364614142 DCDC4SLIBttrTrmnlTmprtr "Parameter indicating the SLI battery terminal temperature for control use by the DC/DC converter.…";
CM_ BO_ 2364614398 "DC/DC Converter 4 Status 2";
CM_ SG_ 2364614398 DCDC4HighSidePower "Indicates the measured HVES or high side power measured at the DC/DC Converter.  The high side power is positive if the converter is charging the hybrid battery…";
CM_ SG_ 2364614398 DCDC4LowSidePower "Indicates the measured SLI battery or low side power measured at the DC/DC Converter.  The low side power is positive if the converter is charging the SLI batte…";
CM_ SG_ 2364614398 DCDC4HghSdNgtvtChsssGrndVltg "The voltage level of the high voltage DC side, as measured by the DC/DC between the negative side of the High Voltage DC Side input and the chassis of the DC/DC…";
CM_ BO_ 2364614654 "Slope Sensor Information 3";
CM_ SG_ 2364614654 GradeThresholdIndicator1 "This parameter indicates whether or not the transmitting device has sensed a vehicle grade equal to or exceeding a manufacturer-defined threshold. The manufactu…";
CM_ SG_ 2364614654 GradeThresholdIndicator2 "This parameter indicates whether or not the transmitting device has sensed a vehicle grade equal to or exceeding a manufacturer-defined threshold. The manufactu…";
CM_ SG_ 2364614654 GradeThresholdIndicator3 "This parameter indicates whether or not the transmitting device has sensed a vehicle grade equal to or exceeding a manufacturer-defined threshold. The manufactu…";
CM_ SG_ 2364614654 GradeThresholdIndicator4 "This parameter indicates whether or not the transmitting device has sensed a vehicle grade equal to or exceeding a manufacturer-defined threshold. The manufactu…";
CM_ SG_ 2364614654 GradeThresholdIndicator5 "This parameter indicates whether or not the transmitting device has sensed a vehicle grade equal to or exceeding a manufacturer-defined threshold. The manufactu…";
CM_ SG_ 2364614654 GradeThresholdIndicator6 "This parameter indicates whether or not the transmitting device has sensed a vehicle grade equal to or exceeding a manufacturer-defined threshold. The manufactu…";
CM_ BO_ 2364614910 "DC/AC Accessory Inverter 3 Status 2";
CM_ SG_ 2364614910 DCACAssrInvrtr3DCSdCrrnt "DC Side input current measured at the point of control inside the DC/AC Accessory Inverter.…";
CM_ SG_ 2364614910 DCACAssrInvrtr3DCSdPwr "Power measured at the DC Side input to the DC/AC Accessory Inverter. …";
CM_ SG_ 2364614910 DCACAssrInvrtr3DCSdVltg "DC Side input voltage measured at the point of control inside the DC/AC Accessory Inverter.…";
CM_ SG_ 2364614910 DCACAssIvt3DCSdNtvtCsssGdVt "The voltage level of the high voltage DC side, as measured by the DC/AC between the negative side of the High Voltage DC Side input and the chassis of the DC/AC…";
CM_ BO_ 2364615166 "DC/AC Accessory Inverter 3 Voltage";
CM_ SG_ 2364615166 DCACAssrInvrtr3IgntnVltg "Ignition voltage supplied to the  DC/AC Accessory Inverter controller.…";
CM_ SG_ 2364615166 DCACAssrInvrtr3SLIVltg "Low voltage (SLI) supplied to the DC/AC Accessory Inverter controller.…";
CM_ BO_ 2364615678 "DC/AC Accessory Inverter 4 Status 2";
CM_ SG_ 2364615678 DCACAssrInvrtr4DCSdCrrnt "DC Side input current measured at the point of control inside the DC/AC Accessory Inverter.…";
CM_ SG_ 2364615678 DCACAssrInvrtr4DCSdPwr "Power measured at the DC Side input to the DC/AC Accessory Inverter. …";
CM_ SG_ 2364615678 DCACAssrInvrtr4DCSdVltg "DC Side input voltage measured at the point of control inside the DC/AC Accessory Inverter.…";
CM_ SG_ 2364615678 DCACAssIvt4DCSdNtvtCsssGdVt "The voltage level of the high voltage DC side, as measured by the DC/AC between the negative side of the High Voltage DC Side input and the chassis of the DC/AC…";
CM_ BO_ 2364615934 "DC/AC Accessory Inverter 4 Voltage";
CM_ SG_ 2364615934 DCACAssrInvrtr4IgntnVltg "Ignition voltage supplied to the  DC/AC Accessory Inverter controller.…";
CM_ SG_ 2364615934 DCACAssrInvrtr4SLIVltg "Low voltage (SLI) supplied to the DC/AC Accessory Inverter controller.…";
CM_ BO_ 2364616958 "DC/AC Accessory Inverter 5 Status 2";
CM_ SG_ 2364616958 DCACAssrInvrtr5DCSdCrrnt "DC Side input current measured at the point of control inside the DC/AC Accessory Inverter.…";
CM_ SG_ 2364616958 DCACAssrInvrtr5DCSdPwr "Power measured at the DC Side input to the DC/AC Accessory Inverter. …";
CM_ SG_ 2364616958 DCACAssrInvrtr5DCSdVltg "DC Side input voltage measured at the point of control inside the DC/AC Accessory Inverter.…";
CM_ SG_ 2364616958 DCACAssIvt5DCSdNtvtCsssGdVt "The voltage level of the high voltage DC side, as measured by the DC/AC between the negative side of the High Voltage DC Side input and the chassis of the DC/AC…";
CM_ BO_ 2364617214 "DC/AC Accessory Inverter 5 Voltage";
CM_ SG_ 2364617214 DCACAssrInvrtr5IgntnVltg "Ignition voltage supplied to the  DC/AC Accessory Inverter controller.…";
CM_ SG_ 2364617214 DCACAssrInvrtr5SLIVltg "Low voltage (SLI) supplied to the DC/AC Accessory Inverter controller.…";
CM_ BO_ 2365296894 "DC/DC Converter 4 Voltage";
CM_ SG_ 2365296894 DCDC4CntrllrInptIgntnVltg "Ignition voltage (i.e. switched) supplied to the  DC/DC Converter controller.…";
CM_ SG_ 2365296894 DCDC4ControllerInputSLIVoltage "Voltage (i.e not switched) supplied to the DC/DC Converter controller.…";
CM_ BO_ 2365297150 "DC/DC Converter 3 Voltage";
CM_ SG_ 2365297150 DCDC3CntrllrInptIgntnVltg "Ignition voltage (i.e. switched) supplied to the  DC/DC Converter controller.…";
CM_ SG_ 2365297150 DCDC3ControllerInputSLIVoltage "Voltage (i.e not switched) supplied to the DC/DC Converter controller.…";
CM_ BO_ 2365297406 "DC/DC Converter 2 Voltage";
CM_ SG_ 2365297406 DCDC2CntrllrInptIgntnVltg "Ignition voltage (i.e. switched) supplied to the  DC/DC Converter controller.…";
CM_ SG_ 2365297406 DCDC2ControllerInputSLIVoltage "Voltage (i.e not switched) supplied to the DC/DC Converter controller.…";
CM_ BO_ 2365297662 "DC/DC Converter 1 Voltage";
CM_ SG_ 2365297662 DCDC1CntrllrInptIgntnVltg "Ignition voltage (i.e. switched) supplied to the  DC/DC Converter controller.…";
CM_ SG_ 2365297662 DCDC1ControllerInputSLIVoltage "Voltage (i.e not switched) supplied to the DC/DC Converter controller.…";
CM_ BO_ 2365299454 "DC/AC Accessory Inverter 1 DC Side Limits ";
CM_ SG_ 2365299454 DCACAssIvt1DCSdCtMLtRqst "The minimum allowed DC Side input current requested by a separate device.   Under normal conditions this requested limit would be reflected in SPN 9532.…";
CM_ SG_ 2365299454 DCACAssIvt1DCSdCtMxLtRqst "The maximum allowed DC Side input current requested by a separate device.   Under normal conditions this requested limit would be reflected in SPN 9226.…";
CM_ SG_ 2365299454 DCACAssIvt1DCSdVtMLtRqst "The minimum allowed DC Side input voltage requested by a separate device.   Under normal conditions this requested limit would be reflected in SPN 9225.…";
CM_ SG_ 2365299454 DCACAssIvt1DCSdVtMxLtRqst "The maximum allowed DC Side input voltage requested by a separate device.   Under normal conditions this requested limit would be reflected in SPN 9531.…";
CM_ BO_ 2365299710 "DC/AC Accessory Inverter 1 AC Side Limits ";
CM_ SG_ 2365299710 DCACAssIvt1ACSdRMSCtMxLtRqst "The maximum allowed AC Side output RMS line current requested by a separate device.   Under normal conditions this requested limit would be reflected in SPN 922…";
CM_ SG_ 2365299710 DCACAssIvt1ACSdRMSVtMxLtRqst "The maximum allowed AC Side line to line RMS voltage requested by a separate device.   Under normal conditions this requested limit would be reflected in SPN 92…";
CM_ SG_ 2365299710 DCACAssrInvrtr1ACSdDfltFrqnRqst "This setting may be used to set a default frequency command for when communication has been lost with the controlling device.  When set to Not Available (FFh), …";
CM_ BO_ 2365300734 "DC/AC Accessory Inverter 2 DC Side Limits ";
CM_ SG_ 2365300734 DCACAssIvt2DCSdCtMLtRqst "The minimum allowed DC Side input current requested by a separate device.   Under normal conditions this requested limit would be reflected in SPN 9538.…";
CM_ SG_ 2365300734 DCACAssIvt2DCSdCtMxLtRqst "The maximum allowed DC Side input current requested by a separate device.   Under normal conditions this requested limit would be reflected in SPN 9256.…";
CM_ SG_ 2365300734 DCACAssIvt2DCSdVtMLtRqst "The minimum allowed DC Side input voltage requested by a separate device.   Under normal conditions this requested limit would be reflected in SPN 9255.…";
CM_ SG_ 2365300734 DCACAssIvt2DCSdVtMxLtRqst "The maximum allowed DC Side input voltage requested by a separate device.   Under normal conditions this requested limit would be reflected in SPN 9537.…";
CM_ BO_ 2365300990 "DC/AC Accessory Inverter 2 AC Side Limits ";
CM_ SG_ 2365300990 DCACAssIvt2ACSdRMSCtMxLtRqst "The maximum allowed AC Side output RMS line current requested by a separate device.   Under normal conditions this requested limit would be reflected in SPN 925…";
CM_ SG_ 2365300990 DCACAssIvt2ACSdRMSVtMxLtRqst "The maximum allowed AC Side line to line RMS voltage requested by a separate device.   Under normal conditions this requested limit would be reflected in SPN 92…";
CM_ SG_ 2365300990 DCACAssrInvrtr2ACSdDfltFrqnRqst "This setting may be used to set a default frequency command for when communication has been lost with the controlling device.  When set to Not Available (FFh), …";
CM_ BO_ 2365302014 "DC/AC Accessory Inverter 3 DC Side Limits ";
CM_ SG_ 2365302014 DCACAssIvt3DCSdCtMLtRqst "The minimum allowed DC Side input current requested by a separate device.   Under normal conditions this requested limit would be reflected in SPN 9544.…";
CM_ SG_ 2365302014 DCACAssIvt3DCSdCtMxLtRqst "The maximum allowed DC Side input current requested by a separate device.   Under normal conditions this requested limit would be reflected in SPN 9286.…";
CM_ SG_ 2365302014 DCACAssIvt3DCSdVtMLtRqst "The minimum allowed DC Side input voltage requested by a separate device.   Under normal conditions this requested limit would be reflected in SPN 9285.…";
CM_ SG_ 2365302014 DCACAssIvt3DCSdVtMxLtRqst "The maximum allowed DC Side input voltage requested by a separate device.   Under normal conditions this requested limit would be reflected in SPN 9543.…";
CM_ BO_ 2365302270 "DC/AC Accessory Inverter 3 AC Side Limits ";
CM_ SG_ 2365302270 DCACAssIvt3ACSdRMSCtMxLtRqst "The maximum allowed AC Side output RMS line current requested by a separate device.   Under normal conditions this requested limit would be reflected in SPN 928…";
CM_ SG_ 2365302270 DCACAssIvt3ACSdRMSVtMxLtRqst "The maximum allowed AC Side line to line RMS voltage requested by a separate device.   Under normal conditions this requested limit would be reflected in SPN 92…";
CM_ SG_ 2365302270 DCACAssrInvrtr3ACSdDfltFrqnRqst "This setting may be used to set a default frequency command for when communication has been lost with the controlling device.  When set to Not Available (FFh), …";
CM_ BO_ 2365303294 "DC/AC Accessory Inverter 4 DC Side Limits ";
CM_ SG_ 2365303294 DCACAssIvt4DCSdCtMLtRqst "The minimum allowed DC Side input current requested by a separate device.   Under normal conditions this requested limit would be reflected in SPN 9550.…";
CM_ SG_ 2365303294 DCACAssIvt4DCSdCtMxLtRqst "The maximum allowed DC Side input current requested by a separate device.   Under normal conditions this requested limit would be reflected in SPN 9316.…";
CM_ SG_ 2365303294 DCACAssIvt4DCSdVtMLtRqst "The minimum allowed DC Side input voltage requested by a separate device.   Under normal conditions this requested limit would be reflected in SPN 9315.…";
CM_ SG_ 2365303294 DCACAssIvt4DCSdVtMxLtRqst "The maximum allowed DC Side input voltage requested by a separate device.   Under normal conditions this requested limit would be reflected in SPN 9549.…";
CM_ BO_ 2365303550 "DC/AC Accessory Inverter 4 AC Side Limits ";
CM_ SG_ 2365303550 DCACAssIvt4ACSdRMSCtMxLtRqst "The maximum allowed AC Side output RMS line current requested by a separate device.   Under normal conditions this requested limit would be reflected in SPN 931…";
CM_ SG_ 2365303550 DCACAssIvt4ACSdRMSVtMxLtRqst "The maximum allowed AC Side line to line RMS voltage requested by a separate device.   Under normal conditions this requested limit would be reflected in SPN 93…";
CM_ SG_ 2365303550 DCACAssrInvrtr4ACSdDfltFrqnRqst "This setting may be used to set a default frequency command for when communication has been lost with the controlling device.  When set to Not Available (FFh), …";
CM_ BO_ 2365304574 "DC/AC Accessory Inverter 5 DC Side Limits ";
CM_ SG_ 2365304574 DCACAssIvt5DCSdCtMLtRqst "The minimum allowed DC Side input current requested by a separate device.   Under normal conditions this requested limit would be reflected in SPN 9556.…";
CM_ SG_ 2365304574 DCACAssIvt5DCSdCtMxLtRqst "The maximum allowed DC Side input current requested by a separate device.   Under normal conditions this requested limit would be reflected in SPN 9362.…";
CM_ SG_ 2365304574 DCACAssIvt5DCSdVtMLtRqst "The minimum allowed DC Side input voltage requested by a separate device.   Under normal conditions this requested limit would be reflected in SPN 9361.…";
CM_ SG_ 2365304574 DCACAssIvt5DCSdVtMxLtRqst "The maximum allowed DC Side input voltage requested by a separate device.   Under normal conditions this requested limit would be reflected in SPN 9555.…";
CM_ BO_ 2365304830 "DC/AC Accessory Inverter 5 AC Side Limits ";
CM_ SG_ 2365304830 DCACAssIvt5ACSdRMSCtMxLtRqst "The maximum allowed AC Side output RMS line current requested by a separate device.   Under normal conditions this requested limit would be reflected in SPN 936…";
CM_ SG_ 2365304830 DCACAssIvt5ACSdRMSVtMxLtRqst "The maximum allowed AC Side line to line RMS voltage requested by a separate device.   Under normal conditions this requested limit would be reflected in SPN 93…";
CM_ SG_ 2365304830 DCACAssrInvrtr5ACSdDfltFrqnRqst "This setting may be used to set a default frequency command for when communication has been lost with the controlling device.  When set to Not Available (FFh), …";
CM_ BO_ 2365307646 "DC/DC Converter 4 SLI Battery Limits";
CM_ SG_ 2365307646 DCDC4SLIBttrTmprtrMxmmLmtRqst "The maximum allowed SLI Battery Temperature requested by a separate device.  …";
CM_ SG_ 2365307646 DCDC4SLIBttTCCtMxLtRqst "The maximum allowed SLI Battery charging current (at the battery terminals) requested by a separate device.  …";
CM_ SG_ 2365307646 DCDC4SLIBttTVtMxLtRqst "The maximum allowed SLI Battery Voltage (at the battery terminals) requested by a separate system device.  …";
CM_ BO_ 2365307902 "DC/DC Converter 4 Temperatures";
CM_ SG_ 2365307902 DCDC4CnvrtrEltrnFltrTmprtr "Parameter indicating the temperature of the electronic components that make up the DC/DC Converter filter.…";
CM_ SG_ 2365307902 DCDC4ConverterTemperature "Parameter indicating the temperature of the DC/DC Converter (e.g, controller, circuit board, enclosure).…";
CM_ SG_ 2365307902 DCDC4CoolantInTemperature "Parameter indicating the temperature of the DC/DC Converter Coolant measured at the input of the converter…";
CM_ SG_ 2365307902 DCDC4CoolantOutTemperature "Parameter indicating the temperature of the DC/DC Converter Coolant measured at the output of the converter…";
CM_ SG_ 2365307902 DCDC4PwrEltrnsTmprtr "Parameter indicating the temperature of the DC/DC Converter power electronics components (e.g, switch or heatsink).…";
CM_ BO_ 2365308158 "DC/DC Converter 4 Low Side Limits";
CM_ SG_ 2365308158 DCDC4LwSdCrrntMxmmLmtRqst "The maximum allowed low side current requested by a separate device.   Under normal conditions this requested limit would be reflected in SPN 9039.…";
CM_ SG_ 2365308158 DCDC4LwSdVltgMnmmLmtRqst "The minimum allowed low side voltage requested by a separate device.  Under normal conditions this requested limit would be reflected in SPN 9037.…";
CM_ SG_ 2365308158 DCDC4LwSdVltgMxmmLmtRqst "The maximum allowed low side voltage requested by a separate device.   Under normal conditions this requested limit would be reflected in SPN 9038.…";
CM_ BO_ 2365308414 "DC/DC Converter 4 High Side Limits";
CM_ SG_ 2365308414 DCDC4HghSdCrrntMxmmLmtRqst "The maximum allowed high side current requested by a separate device.   Under normal conditions this requested limit would be reflected in SPN 9036.…";
CM_ SG_ 2365308414 DCDC4HghSdVltgMnmmLmtRqst "The minimum allowed high side voltage requested by a separate device.   Under normal conditions this requested limit would be reflected in SPN 9034.…";
CM_ SG_ 2365308414 DCDC4HghSdVltgMxmmLmtRqst "The maximum allowed high side voltage requested by a separate device.  Under normal conditions this requested limit would be reflected in SPN 9035.…";
CM_ BO_ 2365309182 "DC/DC Converter 3 SLI Battery Limits";
CM_ SG_ 2365309182 DCDC3SLIBttrTmprtrMxmmLmtRqst "The maximum allowed SLI Battery Temperature requested by a separate device.  …";
CM_ SG_ 2365309182 DCDC3SLIBttTCCtMxLtRqst "The maximum allowed SLI Battery charging current (at the battery terminals) requested by a separate device.  …";
CM_ SG_ 2365309182 DCDC3SLIBttTVtMxLtRqst "The maximum allowed SLI Battery Voltage (at the battery terminals) requested by a separate system device.  …";
CM_ BO_ 2365309438 "DC/DC Converter 3 Temperatures";
CM_ SG_ 2365309438 DCDC3CnvrtrEltrnFltrTmprtr "Parameter indicating the temperature of the electronic components that make up the DC/DC Converter filter.…";
CM_ SG_ 2365309438 DCDC3ConverterTemperature "Parameter indicating the temperature of the DC/DC Converter (e.g, controller, circuit board, enclosure).…";
CM_ SG_ 2365309438 DCDC3CoolantInTemperature "Parameter indicating the temperature of the DC/DC Converter Coolant measured at the input of the converter…";
CM_ SG_ 2365309438 DCDC3CoolantOutTemperature "Parameter indicating the temperature of the DC/DC Converter Coolant measured at the output of the converter…";
CM_ SG_ 2365309438 DCDC3PwrEltrnsTmprtr "Parameter indicating the temperature of the DC/DC Converter power electronics components (e.g, switch or heatsink).…";
CM_ BO_ 2365309694 "DC/DC Converter 3 Low Side Limits";
CM_ SG_ 2365309694 DCDC3LwSdCrrntMxmmLmtRqst "The maximum allowed low side current requested by a separate device.   Under normal conditions this requested limit would be reflected in SPN 8984.…";
CM_ SG_ 2365309694 DCDC3LwSdVltgMnmmLmtRqst "The minimum allowed low side voltage requested by a separate device.   Under normal conditions this requested limit would be reflected in SPN 8982.…";
CM_ SG_ 2365309694 DCDC3LwSdVltgMxmmLmtRqst "The maximum allowed low side voltage requested by a separate device.   Under normal conditions this requested limit would be reflected in SPN 8983.…";
CM_ BO_ 2365309950 "DC/DC Converter 3 High Side Limits";
CM_ SG_ 2365309950 DCDC3HghSdCrrntMxmmLmtRqst "The maximum allowed high side current requested by a separate device.   Under normal conditions this requested limit would be reflected in  SPN 8981.…";
CM_ SG_ 2365309950 DCDC3HghSdVltgMnmmLmtRqst "The minimum allowed high side voltage requested by a separate device.   Under normal conditions this requested limit would be reflected in  SPN 8979.…";
CM_ SG_ 2365309950 DCDC3HghSdVltgMxmmLmtRqst "The maximum allowed high side voltage requested by a separate device.   Under normal conditions this requested limit would be reflected in  SPN 8980.…";
CM_ BO_ 2365310718 "DC/DC Converter 2 SLI Battery Limits";
CM_ SG_ 2365310718 DCDC2SLIBttrTmprtrMxmmLmtRqst "The maximum allowed SLI Battery Temperature requested by a separate device.  …";
CM_ SG_ 2365310718 DCDC2SLIBttTCCtMxLtRqst "The maximum allowed SLI Battery charging current (at the battery terminals) requested by a separate device.  …";
CM_ SG_ 2365310718 DCDC2SLIBttTVtMxLtRqst "The maximum allowed SLI Battery Voltage (at the battery terminals) requested by a separate system device.  …";
CM_ BO_ 2365310974 "DC/DC Converter 2 Temperatures";
CM_ SG_ 2365310974 DCDC2CnvrtrEltrnFltrTmprtr "Parameter indicating the temperature of the electronic components that make up the DC/DC Converter filter.…";
CM_ SG_ 2365310974 DCDC2ConverterTemperature "Parameter indicating the temperature of the DC/DC Converter (e.g, controller, circuit board, enclosure).…";
CM_ SG_ 2365310974 DCDC2CoolantInTemperature "Parameter indicating the temperature of the DC/DC Converter Coolant measured at the input of the converter…";
CM_ SG_ 2365310974 DCDC2CoolantOutTemperature "Parameter indicating the temperature of the DC/DC Converter Coolant measured at the output of the converter…";
CM_ SG_ 2365310974 DCDC2PwrEltrnsTmprtr "Parameter indicating the temperature of the DC/DC Converter power electronics components (e.g, switch or heatsink).…";
CM_ BO_ 2365311230 "DC/DC Converter 2 Low Side Limits";
CM_ SG_ 2365311230 DCDC2LwSdCrrntMxmmLmtRqst "The maximum allowed low side current requested by a separate device.  Under normal conditions this requested limit would be reflected in SPN 8929.…";
CM_ SG_ 2365311230 DCDC2LwSdVltgMnmmLmtRqst "The minimum allowed low side voltage requested by a separate device.  Under normal conditions this requested limit would be reflected in SPN 8927.…";
CM_ SG_ 2365311230 DCDC2LwSdVltgMxmmLmtRqst "The maximum allowed low side voltage requested by a separate device.  Under normal conditions this requested limit would be reflected in SPN 8928.…";
CM_ BO_ 2365311486 "DC/DC Converter 2 High Side Limits";
CM_ SG_ 2365311486 DCDC2HghSdCrrntMxmmLmtRqst "The maximum allowed high side current requested by a separate device. Under normal conditions this requested limit would be reflected in SPN 8926.…";
CM_ SG_ 2365311486 DCDC2HghSdVltgMnmmLmtRqst "The minimum allowed high side voltage requested by a separate device. Under normal conditions this requested limit would be reflected in SPN 8924.…";
CM_ SG_ 2365311486 DCDC2HghSdVltgMxmmLmtRqst "The maximum allowed high side voltage requested by a separate device.  Under normal conditions this requested limit would be reflected in SPN 8925.…";
CM_ BO_ 2365313534 "DC/DC Converter 1 SLI Battery Limits";
CM_ SG_ 2365313534 DCDC1SLIBttrTmprtrMxmmLmtRqst "The maximum allowed SLI Battery Temperature requested by a separate device.  …";
CM_ SG_ 2365313534 DCDC1SLIBttTCCtMxLtRqst "The maximum allowed SLI Battery charging current (at the battery terminals) requested by a separate device.  …";
CM_ SG_ 2365313534 DCDC1SLIBttTVtMxLtRqst "The maximum allowed SLI Battery Voltage (at the battery terminals) requested by a separate system device.  …";
CM_ BO_ 2365315326 "DC/DC Converter 1 Temperatures";
CM_ SG_ 2365315326 DCDC1CnvrtrEltrnFltrTmprtr "Parameter indicating the temperature of the electronic components that make up the DC/DC Converter filter.…";
CM_ SG_ 2365315326 DCDC1ConverterTemperature "Parameter indicating the temperature of the DC/DC Converter (e.g, controller, circuit board, enclosure).…";
CM_ SG_ 2365315326 DCDC1CoolantInTemperature "Parameter indicating the temperature of the DC/DC Converter Coolant measured at the input of the converter…";
CM_ SG_ 2365315326 DCDC1CoolantOutTemperature "Parameter indicating the temperature of the DC/DC Converter Coolant measured at the output of the converter…";
CM_ SG_ 2365315326 DCDC1PwrEltrnsTmprtr "Parameter indicating the temperature of the DC/DC Converter power electronics components (e.g, switch or heatsink).…";
CM_ BO_ 2365315582 "DC/DC Converter 1 Low Side Limits";
CM_ SG_ 2365315582 DCDC1LwSdCrrntMxmmLmtRqst "The maximum allowed low side current requested by a separate device.   Under normal conditions this requested limit would be reflected in SPN 8829.…";
CM_ SG_ 2365315582 DCDC1LwSdVltgMnmmLmtRqst "The minimum allowed low side voltage requested by a separate device.   Under normal conditions this requested limit would be reflected in SPN 8827.…";
CM_ SG_ 2365315582 DCDC1LwSdVltgMxmmLmtRqst "The maximum allowed low side voltage requested by a separate device.   Under normal conditions this requested limit would be reflected in SPN 8828.…";
CM_ BO_ 2365315838 "DC/DC Converter 1 High Side Limits";
CM_ SG_ 2365315838 DCDC1HghSdCrrntMxmmLmtRqst "The maximum allowed high side current requested by a separate device.   Under normal conditions this requested limit would be reflected in SPN 8826.…";
CM_ SG_ 2365315838 DCDC1HghSdVltgMnmmLmtRqst "The minimum allowed high side voltage requested by a separate device.   Under normal conditions this requested limit would be reflected in SPN 8824.…";
CM_ SG_ 2365315838 DCDC1HghSdVltgMxmmLmtRqst "The maximum allowed high side voltage requested by a separate device.   Under normal conditions this requested limit would be reflected in SPN 8825.…";
CM_ BO_ 2365318910 "High Voltage Energy Storage Fan Commands";
CM_ SG_ 2365318910 HVESFanEnableCommand "Enable and direction command to this HVES fan.00b = Fan Off01b = Fan On Normal/Default Direction10b = Fan On Reverse Direction11b = Don't Care/Take no action…";
CM_ SG_ 2365318910 HVESFanInstance1 "Indicates the HVES Fan Instance that is being commanded.  Multiple instances can be controlled with the same command PGN by setting each unique instance paramet…";
CM_ SG_ 2365318910 HVESFanInstance10 "Indicates the HVES Fan Instance that is being commanded.  Multiple instances can be controlled with the same command PGN by setting each unique instance paramet…";
CM_ SG_ 2365318910 HVESFanInstance11 "Indicates the HVES Fan Instance that is being commanded.  Multiple instances can be controlled with the same command PGN by setting each unique instance paramet…";
CM_ SG_ 2365318910 HVESFanInstance12 "Indicates the HVES Fan Instance that is being commanded.  Multiple instances can be controlled with the same command PGN by setting each unique instance paramet…";
CM_ SG_ 2365318910 HVESFanInstance13 "Indicates the HVES Fan Instance that is being commanded.  Multiple instances can be controlled with the same command PGN by setting each unique instance paramet…";
CM_ SG_ 2365318910 HVESFanInstance14 "Indicates the HVES Fan Instance that is being commanded.  Multiple instances can be controlled with the same command PGN by setting each unique instance paramet…";
CM_ SG_ 2365318910 HVESFanInstance15 "Indicates the HVES Fan Instance that is being commanded.  Multiple instances can be controlled with the same command PGN by setting each unique instance paramet…";
CM_ SG_ 2365318910 HVESFanInstance2 "Indicates the HVES Fan Instance that is being commanded.  Multiple instances can be controlled with the same command PGN by setting each unique instance paramet…";
CM_ SG_ 2365318910 HVESFanInstance3 "Indicates the HVES Fan Instance that is being commanded.  Multiple instances can be controlled with the same command PGN by setting each unique instance paramet…";
CM_ SG_ 2365318910 HVESFanInstance4 "Indicates the HVES Fan Instance that is being commanded.  Multiple instances can be controlled with the same command PGN by setting each unique instance paramet…";
CM_ SG_ 2365318910 HVESFanInstance5 "Indicates the HVES Fan Instance that is being commanded.  Multiple instances can be controlled with the same command PGN by setting each unique instance paramet…";
CM_ SG_ 2365318910 HVESFanInstance6 "Indicates the HVES Fan Instance that is being commanded.  Multiple instances can be controlled with the same command PGN by setting each unique instance paramet…";
CM_ SG_ 2365318910 HVESFanInstance7 "Indicates the HVES Fan Instance that is being commanded.  Multiple instances can be controlled with the same command PGN by setting each unique instance paramet…";
CM_ SG_ 2365318910 HVESFanInstance8 "Indicates the HVES Fan Instance that is being commanded.  Multiple instances can be controlled with the same command PGN by setting each unique instance paramet…";
CM_ SG_ 2365318910 HVESFanInstance9 "Indicates the HVES Fan Instance that is being commanded.  Multiple instances can be controlled with the same command PGN by setting each unique instance paramet…";
CM_ SG_ 2365318910 HVESFanPercentSpeedCommand "Speed command to this HVES fan in percentage of maximum speed.Note: Both Speed Command (SPN 8386) and Percent Speed Command cannot be used at the same time.  Al…";
CM_ SG_ 2365318910 HVESFanPowerHold "Command to allow this HVES fan to remain alive independently of the electrical enable input to the fan.  For example, this could allow continued device operatio…";
CM_ SG_ 2365318910 HVESFanSpeedCommand "Speed command to this HVES fan.Note: Both Speed Command and Percent Speed Command (SPN 8387) cannot be used at the same time.  Always set the unused speed comma…";
CM_ BO_ 2365322238 "Cruise Control / Vehicle Speed 5";
CM_ SG_ 2365322238 DirectionalVehicleSpeed "The velocity and direction of the vehicle. Positive values are used for forward vehicle motion, negative values for reverse vehicle motion.  This SPN is intende…";
CM_ BO_ 2365346302 "Air Suspension Control 7";
CM_ SG_ 2365346302 LiftAxle1Status "Indicates the status of a tag axle 1.  Numbering of lift/tag axles starts at front axle.  SPN 1743 may be used if less detail is acceptable.000b = Down (tag axl…";
CM_ SG_ 2365346302 LiftAxle2Status "Indicates the status of a tag axle 2.  Numbering of lift/tag axles starts at front axle.  SPN 1822 may be used if less detail is acceptable.000b = Down (tag axl…";
CM_ BO_ 2365348350 "Engine Load Sharing Information";
CM_ SG_ 2365348350 EngineLoadShareStatus "This signal indicates that the status of an engine load sharing feature.0000b = Offline0001b = Master0010b = Slave0011b = Loading0100b = Unloading0101b to 1101b…";
CM_ SG_ 2365348350 EngineUnloadStatus "This signal indicates the status of an external request to unload the engine, such as the external unload request switch.00b = Not Requested01b = Requested10b =…";
CM_ BO_ 2365363710 "Engine Cylinder Pressure Monitor Status Information";
CM_ SG_ 2365363710 EngnClndrPrssrMntr1PrlmnrFMI "Used to identify the applicable J1939-73 FMI detected in the Engine Cylinder Pressure Monitor 1. In the case of multiple failures the most severe is communicate…";
CM_ SG_ 2365363710 EngnClndrPrssrMntr2PrlmnrFMI "Used to identify the applicable J1939-73 FMI detected in the Engine Cylinder Pressure Monitor 2.  In the case of multiple failures the most severe is communicat…";
CM_ BO_ 2365374206 "Electronic Transmission Controller #9";
CM_ SG_ 2365374206 DlClthTrnsmssnCrrntPrsltnGr "The gear currently engaged on the non-engaged clutch of a dual clutch transmission (DCT) or the last gear engaged on the non-engaged clutch while the transmissi…";
CM_ SG_ 2365374206 DlClthTrnsmssnInptShft1Spd "Rotational velocity of the primary shaft transferring power through clutch 1 into the dual clutch transmission (DCT).…";
CM_ SG_ 2365374206 DlClthTrnsmssnInptShft2Spd "Rotational velocity of the primary shaft transferring power through clutch 2 into the dual clutch transmission (DCT).…";
CM_ SG_ 2365374206 DlClthTrnsmssnSltdPrsltnGr "The gear that the transmission will attempt to achieve during the current pre-selection event (shifting to a new gear on the non-engaged clutch of a dual clutch…";
CM_ BO_ 2365393662 "Aftertreatment 2 Outlet Gas NOx Sensor Correction Data 2";
CM_ SG_ 2365393662 Aftrtrtmnt2OtltCrrtdNOx "The corrected outlet NOx value  for aftertreatment 2 shall include all learned adaptions and offsets that are used to adjust the raw signal.2016 MY and later en…";
CM_ SG_ 2365393662 Aftrtrtmnt2OtltNOxSnsrNH3Crrtn "Correction of NH3 at the NOx-signal to correct (recalculate) sensor signal on the Engine ECU side.…";
CM_ SG_ 2365393662 Aftrtrtmnt2OtltNOxSnsrNO2Crrtn "Correction of NO2 at the NOx-signal to correct (recalculate) sensor signal on the Engine ECU side.…";
CM_ SG_ 2365393662 Atttt2OttNOxSsNOxPssCt "Correction of pressure NOx-signal to correct (recalculate) sensor signal on the Engine ECU side.…";
CM_ SG_ 2365393662 Atttt2OttNOxSsO2PssCt "Correction of pressure Lambda-signal to correct (recalculate) sensor signal on the Engine ECU side.…";
CM_ SG_ 2365393662 Atttt2OttNOxSsSdssFRst "Self-diagnosis result for NOx sensor ATO2 (Aftertreatment Outlet Bank 2) as a ratio of detected value to reference value defined by supplier.This result is used…";
CM_ BO_ 2365393918 "Aftertreatment 2 Outlet Gas NOx Sensor Correction Data 1";
CM_ SG_ 2365393918 Aftrtrtmnt2OtltNOxSnsrHtrRt "Heater ratio to determine temperature at sensor tip.…";
CM_ SG_ 2365393918 Aftrtrtmnt2OtltNOxSnsrOprtnHrs "Counted hours that the NOx-sensor was operated with status dewpoint reached…";
CM_ SG_ 2365393918 Atttt2OttNOxSsNwptdvtNOxG "New part deviation NOx_Gain to correct (recalculate) sensor signal on the Engine ECU side.…";
CM_ SG_ 2365393918 Atttt2OttNOxSsNwptdvtNOxOst "New part deviation NOx_Offset to correct (recalculate) sensor signal on the Engine ECU side.…";
CM_ BO_ 2365394174 "Aftertreatment 2 Intake Gas NOx Sensor Correction Data 2";
CM_ SG_ 2365394174 EExst2ItNOxSsNOxPssCt "Correction of pressure NOx-signal to correct (recalculate) sensor signal on the Engine ECU side.  This sensor is located at the intake of the aftertreatment sys…";
CM_ SG_ 2365394174 EExst2ItNOxSsO2PssCt "Correction of pressure Lambda-signal to correct (recalculate) sensor signal on the Engine ECU side.  This sensor is located at the intake of the aftertreatment …";
CM_ SG_ 2365394174 EExst2ItNOxSsSdssFRst "Self-diagnosis result for NOx sensor EEB2h (Engine Exhaust Bank 2) as a ratio of detected value to reference value defined by supplier.  This sensor is located …";
CM_ SG_ 2365394174 EngineExhaust2CorrectedNox "The corrected intake Selective Catalytic Reduction NOx value for aftertreatment 2 shall include all learned adaptions and offsets that are used to adjust the ra…";
CM_ SG_ 2365394174 EngnExhst2IntkNOxSnsrNH3Crrtn "Correction of NH3 at the NOx-signal to correct (recalculate) sensor signal on the Engine ECU side.  This sensor is located at the intake of the aftertreatment s…";
CM_ SG_ 2365394174 EngnExhst2IntkNOxSnsrNO2Crrtn "Correction of NO2 at the NOx-signal to correct (recalculate) sensor signal on the Engine ECU side.  This sensor is located at the intake of the aftertreatment s…";
CM_ BO_ 2365394430 "Aftertreatment 2 Intake Gas NOx Sensor Correction Data 1";
CM_ SG_ 2365394430 EExst2ItNOxSsNwptdvtNOxG "New part deviation NOx_Gain to correct (recalculate) sensor signal on the Engine ECU side.  This sensor is located at the intake of the aftertreatment system if…";
CM_ SG_ 2365394430 EExst2ItNOxSsNwptdvtNOxOst "New part deviation NOx_Offset to correct (recalculate) sensor signal on the Engine ECU side.  This sensor is located at the intake of the aftertreatment system …";
CM_ SG_ 2365394430 EngnExhst2IntkNOxSnsrHtrRt "Heater ratio to determine temperature at sensor tip.  This sensor is located at the intake of the aftertreatment system if an aftertreatment system exists.…";
CM_ SG_ 2365394430 EngnExhst2IntkNOxSnsrOprtnHrs "Counted hours that the NOx-sensor was operated with status dewpoint reached.  This sensor is located at the intake of the aftertreatment system if an aftertreat…";
CM_ BO_ 2365394686 "Aftertreatment 1 Outlet Gas NOx Sensor Correction Data 2";
CM_ SG_ 2365394686 Aftrtrtmnt1OtltCrrtdNOx "The corrected outlet NOx value for aftertreatment 1 shall include all learned adaptions and offsets that are used to adjust the raw signal.2016 MY and later eng…";
CM_ SG_ 2365394686 Aftrtrtmnt1OtltNOxSnsrNH3Crrtn "Correction of NH3 at the NOx-signal to correct (recalculate) sensor signal on the Engine ECU side.…";
CM_ SG_ 2365394686 Aftrtrtmnt1OtltNOxSnsrNO2Crrtn "Correction of NO2 at the NOx-signal to correct (recalculate) sensor signal on the Engine ECU side.…";
CM_ SG_ 2365394686 Atttt1OttNOxSsNOxPssCt "Correction of pressure NOx-signal to correct (recalculate) sensor signal on the Engine ECU side.…";
CM_ SG_ 2365394686 Atttt1OttNOxSsO2PssCt "Correction of pressure Lambda-signal to correct (recalculate) sensor signal on the Engine ECU side.…";
CM_ SG_ 2365394686 Atttt1OttNOxSsSdssFRst "Self-diagnosis result for NOx sensor ATO1 (Aftertreatment Outlet Bank 1) as a ratio of detected value to reference value defined by supplier.This result is used…";
CM_ BO_ 2365394942 "Aftertreatment 1 Outlet Gas NOx Sensor Correction Data 1";
CM_ SG_ 2365394942 Aftrtrtmnt1OtltNOxSnsrHtrRt "Heater ratio to determine temperature at sensor tip.…";
CM_ SG_ 2365394942 Aftrtrtmnt1OtltNOxSnsrOprtnHrs "Counted hours that the NOx-sensor was operated with status dewpoint reached…";
CM_ SG_ 2365394942 Atttt1OttNOxSsNwptdvtNOxG "New part deviation NOx_Gain to correct (recalculate) sensor signal on the Engine ECU side.…";
CM_ SG_ 2365394942 Atttt1OttNOxSsNwptdvtNOxOst "New part deviation NOx_Offset to correct (recalculate) sensor signal on the Engine ECU side.…";
CM_ BO_ 2365395198 "Aftertreatment 1 Intake Gas NOx Sensor Correction Data 2";
CM_ SG_ 2365395198 EExst1NOxSsSdssFRst "Self-diagnosis result for NOx sensor EEB1h (Engine Exhaust Bank 1) as a ratio of detected value to reference value defined by supplier.  This sensor is located …";
CM_ SG_ 2365395198 EngineExhaust1CorrectedNox "The corrected NOx value for exhaust bank 1 shall include all learned adaptions and offsets that are used to adjust the raw signal.  This sensor is located at th…";
CM_ SG_ 2365395198 EngnExhst1NOxSnsrNH3Crrtn "Correction of NH3 at the NOx-signal to correct (recalculate) sensor signal on the Engine ECU side.  This sensor is located at the intake of the aftertreatment s…";
CM_ SG_ 2365395198 EngnExhst1NOxSnsrNO2Crrtn "Correction of NO2 at the NOx-signal to correct (recalculate) sensor signal on the Engine ECU side.  This sensor is located at the intake of the aftertreatment s…";
CM_ SG_ 2365395198 EngnExhst1NOxSnsrNOxPrssrCrrtn "Correction of pressure NOx-signal to correct (recalculate) sensor signal on the Engine ECU side.  This sensor is located at the intake of the aftertreatment sys…";
CM_ SG_ 2365395198 EngnExhst1NOxSnsrO2PrssrCrrtn "Correction of pressure Lambda-signal to correct (recalculate) sensor signal on the Engine ECU side.  This sensor is located at the intake of the aftertreatment …";
CM_ BO_ 2365395454 "Aftertreatment 1 Intake Gas NOx Sensor Correction Data 1";
CM_ SG_ 2365395454 EExst1NOxSsNwptdvtNOxOst "New part deviation NOx_Offset to correct (recalculate) sensor signal on the Engine ECU side.  This sensor is located at the intake of the aftertreatment system …";
CM_ SG_ 2365395454 EngnExhst1NOxSnsrHtrRt "Heater ratio to determine temperature at sensor tip.  This sensor is located at the intake of the aftertreatment system if an aftertreatment system exists.…";
CM_ SG_ 2365395454 EngnExhst1NOxSnsrNwprtdvtnNOxGn "New part deviation NOx_Gain to correct (recalculate) sensor signal on the Engine ECU side.  This sensor is located at the intake of the aftertreatment system if…";
CM_ SG_ 2365395454 EngnExhst1NOxSnsrOprtnHrs "Counted hours that the NOx-sensor was operated with status dewpoint reached.  This sensor is located at the intake of the aftertreatment system if an aftertreat…";
CM_ BO_ 2365400062 "Extended Joystick Message 10";
CM_ SG_ 2365400062 Joystick10Button13PressedStatus "Reports when the joystick button has been pressed.00b = Button not pressed01b = Button pressed10b = Error Indicator11b = Not Available…";
CM_ SG_ 2365400062 Joystick10Button14PressedStatus "Reports when the joystick button has been pressed.00b = Button not pressed01b = Button pressed10b = Error Indicator11b = Not Available…";
CM_ SG_ 2365400062 Joystick10Button15PressedStatus "Reports when the joystick button has been pressed.00b = Button not pressed01b = Button pressed10b = Error Indicator11b = Not Available…";
CM_ SG_ 2365400062 Joystick10Button16PressedStatus "Reports when the joystick button has been pressed.00b = Button not pressed01b = Button pressed10b = Error Indicator11b = Not Available…";
CM_ SG_ 2365400062 Joystick10GripXAxisPosition "The position of the joystick grip in the relative motion of travel from the neutral position.  Position value of 0 is Neutral and position value 1000 (100%) is …";
CM_ SG_ 2365400062 Joystick10GripYAxisPosition "The position of the joystick grip in the relative motion of travel from the neutral position.  Position value of 0 is Neutral and position value 1000 (100%) is …";
CM_ SG_ 2365400062 Joystick10ThetaAxisPosition "The position of the joystick in the relative motion of travel from the neutral position.  Position value of 0 is Neutral and position value 1000 (100%) is the e…";
CM_ SG_ 2365400062 Jst10GpXAxsLvRtPstvPstStts "Reports when the current joystick grip position is on the positive travel side (forward, right, clockwise, up) relative to the neutral position for that axis of…";
CM_ SG_ 2365400062 Jst10GpYAxsLvFwdPstvPstStts "Reports when the current joystick grip position is on the positive travel side (forward, right, clockwise, up) relative to the neutral position for that axis of…";
CM_ SG_ 2365400062 Jst10TtAxsCtCwsNtvPstStts "Reports when the current joystick position is on the negative travel side (back, left, counterclockwise, down) relative to the neutral position for that axis of…";
CM_ SG_ 2365400062 Jstk10GrpXAxsDtntPstnStts "Reports when the current joystick grip position is in the detent position for that axis of travel.00b = Not in the Detent Position01b = In the Detent Position10…";
CM_ SG_ 2365400062 Jstk10GrpXAxsLvrLftNgtvPstnStts "Reports when the current joystick grip position is on the negative travel side (back, left, counterclockwise, down) relative to the neutral position for that ax…";
CM_ SG_ 2365400062 Jstk10GrpXAxsNtrlPstnStts "Reports when the current joystick grip position is in the neutral position for that axis of travel.  The neutral position measurement must be determined from so…";
CM_ SG_ 2365400062 Jstk10GrpYAxsDtntPstnStts "Reports when the current joystick grip position is in the detent position for that axis of travel.00b = Not in the Detent Position01b = In the Detent Position10…";
CM_ SG_ 2365400062 Jstk10GrpYAxsLvrBkNgtvPstnStts "Reports when the current joystick grip position is on the negative travel side (back, left, counterclockwise, down) relative to the neutral position for that ax…";
CM_ SG_ 2365400062 Jstk10GrpYAxsNtrlPstnStts "Reports when the current joystick grip position is in the neutral position for that axis of travel.  The neutral position measurement must be determined from so…";
CM_ SG_ 2365400062 Jstk10ThtAxsClkwsPstvPstnStts "Reports when the current joystick position is on the positive travel side (forward, right, clockwise, up) relative to the neutral position for that axis of trav…";
CM_ SG_ 2365400062 Jstk10ThtAxsDtntPstnStts "Reports when the current joystick position is in the detent position for that axis of travel.00b = Not in the Detent Position01b = In the Detent Position10b = E…";
CM_ SG_ 2365400062 Jstk10ThtAxsNtrlPstnStts "Reports when the current joystick position is in the neutral position for that axis of travel.  The neutral position measurement must be determined from some me…";
CM_ BO_ 2365400318 "Basic Joystick Message 10";
CM_ SG_ 2365400318 Joystick10Button10PressedStatus "Reports when the joystick button has been pressed.00b = Button not pressed01b = Button pressed10b = Error Indicator11b = Not Available…";
CM_ SG_ 2365400318 Joystick10Button11PressedStatus "Reports when the joystick button has been pressed.00b = Button not pressed01b = Button pressed10b = Error Indicator11b = Not Available…";
CM_ SG_ 2365400318 Joystick10Button12PressedStatus "Reports when the joystick button has been pressed.00b = Button not pressed01b = Button pressed10b = Error Indicator11b = Not Available…";
CM_ SG_ 2365400318 Joystick10Button1PressedStatus "Reports when the joystick button has been pressed.00b = Button not pressed01b = Button pressed10b = Error Indicator11b = Not Available…";
CM_ SG_ 2365400318 Joystick10Button2PressedStatus "Reports when the joystick button has been pressed.00b = Button not pressed01b = Button pressed10b = Error Indicator11b = Not Available…";
CM_ SG_ 2365400318 Joystick10Button3PressedStatus "Reports when the joystick button has been pressed.00b = Button not pressed01b = Button pressed10b = Error Indicator11b = Not Available…";
CM_ SG_ 2365400318 Joystick10Button4PressedStatus "Reports when the joystick button has been pressed.00b = Button not pressed01b = Button pressed10b = Error Indicator11b = Not Available…";
CM_ SG_ 2365400318 Joystick10Button5PressedStatus "Reports when the joystick button has been pressed.00b = Button not pressed01b = Button pressed10b = Error Indicator11b = Not Available…";
CM_ SG_ 2365400318 Joystick10Button6PressedStatus "Reports when the joystick button has been pressed.00b = Button not pressed01b = Button pressed10b = Error Indicator11b = Not Available…";
CM_ SG_ 2365400318 Joystick10Button7PressedStatus "Reports when the joystick button has been pressed.00b = Button not pressed01b = Button pressed10b = Error Indicator11b = Not Available…";
CM_ SG_ 2365400318 Joystick10Button8PressedStatus "Reports when the joystick button has been pressed.00b = Button not pressed01b = Button pressed10b = Error Indicator11b = Not Available…";
CM_ SG_ 2365400318 Joystick10Button9PressedStatus "Reports when the joystick button has been pressed.00b = Button not pressed01b = Button pressed10b = Error Indicator11b = Not Available…";
CM_ SG_ 2365400318 Joystick10XAxisPosition "The position of the joystick in the relative motion of travel from the neutral position.  Position value of 0 is Neutral and position value 1000 (100%) is the e…";
CM_ SG_ 2365400318 Joystick10YAxisPosition "The position of the joystick in the relative motion of travel from the neutral position.  Position value of 0 is Neutral and position value 1000 (100%) is the e…";
CM_ SG_ 2365400318 Jstk10XAxsDtntPstnStts "Reports when the current joystick position is in the detent position for that axis of travel.00b = Not in the Detent Position01b = In the Detent Position10b = E…";
CM_ SG_ 2365400318 Jstk10XAxsLvrLftNgtvPstnStts "Reports when the current joystick position is on the negative travel side (back, left, counterclockwise, down) relative to the neutral position for that axis of…";
CM_ SG_ 2365400318 Jstk10XAxsLvrRghtPstvPstnStts "Reports when the current joystick position is on the positive travel side (forward, right, clockwise, up) relative to the neutral position for that axis of trav…";
CM_ SG_ 2365400318 Jstk10XAxsNtrlPstnStts "Reports when the current joystick position is in the neutral position for that axis of travel.  The neutral position measurement must be determined from some me…";
CM_ SG_ 2365400318 Jstk10YAxsDtntPstnStts "Reports when the current joystick position is in the detent position for that axis of travel.00b = Not in the Detent Position01b = In the Detent Position10b = E…";
CM_ SG_ 2365400318 Jstk10YAxsLvrBkNgtvPstnStts "Reports when the current joystick position is on the negative travel side (back, left, counterclockwise, down) relative to the neutral position for that axis of…";
CM_ SG_ 2365400318 Jstk10YAxsLvrFrwrdPstvPstnStts "Reports when the current joystick position is on the positive travel side (forward, right, clockwise, up) relative to the neutral position for that axis of trav…";
CM_ SG_ 2365400318 Jstk10YAxsNtrlPstnStts "Reports when the current joystick position is in the neutral position for that axis of travel.  The neutral position measurement must be determined from some me…";
CM_ BO_ 2365400574 "Extended Joystick Message 9";
CM_ SG_ 2365400574 Joystick9Button13PressedStatus "Reports when the joystick button has been pressed.00b = Button not pressed01b = Button pressed10b = Error Indicator11b = Not Available…";
CM_ SG_ 2365400574 Joystick9Button14PressedStatus "Reports when the joystick button has been pressed.00b = Button not pressed01b = Button pressed10b = Error Indicator11b = Not Available…";
CM_ SG_ 2365400574 Joystick9Button15PressedStatus "Reports when the joystick button has been pressed.00b = Button not pressed01b = Button pressed10b = Error Indicator11b = Not Available…";
CM_ SG_ 2365400574 Joystick9Button16PressedStatus "Reports when the joystick button has been pressed.00b = Button not pressed01b = Button pressed10b = Error Indicator11b = Not Available…";
CM_ SG_ 2365400574 Joystick9GripXAxisPosition "The position of the joystick grip in the relative motion of travel from the neutral position.  Position value of 0 is Neutral and position value 1000 (100%) is …";
CM_ SG_ 2365400574 Joystick9GripYAxisPosition "The position of the joystick grip in the relative motion of travel from the neutral position.  Position value of 0 is Neutral and position value 1000 (100%) is …";
CM_ SG_ 2365400574 Joystick9ThetaAxisPosition "The position of the joystick in the relative motion of travel from the neutral position.  Position value of 0 is Neutral and position value 1000 (100%) is the e…";
CM_ SG_ 2365400574 Jst9GpYAxsLvFwdPstvPstStts "Reports when the current joystick grip position is on the positive travel side (forward, right, clockwise, up) relative to the neutral position for that axis of…";
CM_ SG_ 2365400574 Jst9TtAxsCtCwsNtvPstStts "Reports when the current joystick position is on the negative travel side (back, left, counterclockwise, down) relative to the neutral position for that axis of…";
CM_ SG_ 2365400574 Jstk9GrpXAxsDtntPstnStts "Reports when the current joystick grip position is in the detent position for that axis of travel.00b = Not in the Detent Position01b = In the Detent Position10…";
CM_ SG_ 2365400574 Jstk9GrpXAxsLvrLftNgtvPstnStts "Reports when the current joystick grip position is on the negative travel side (back, left, counterclockwise, down) relative to the neutral position for that ax…";
CM_ SG_ 2365400574 Jstk9GrpXAxsLvrRghtPstvPstnStts "Reports when the current joystick grip position is on the positive travel side (forward, right, clockwise, up) relative to the neutral position for that axis of…";
CM_ SG_ 2365400574 Jstk9GrpXAxsNtrlPstnStts "Reports when the current joystick grip position is in the neutral position for that axis of travel.  The neutral position measurement must be determined from so…";
CM_ SG_ 2365400574 Jstk9GrpYAxsDtntPstnStts "Reports when the current joystick grip position is in the detent position for that axis of travel.00b = Not in the Detent Position01b = In the Detent Position10…";
CM_ SG_ 2365400574 Jstk9GrpYAxsLvrBkNgtvPstnStts "Reports when the current joystick grip position is on the negative travel side (back, left, counterclockwise, down) relative to the neutral position for that ax…";
CM_ SG_ 2365400574 Jstk9GrpYAxsNtrlPstnStts "Reports when the current joystick grip position is in the neutral position for that axis of travel.  The neutral position measurement must be determined from so…";
CM_ SG_ 2365400574 Jstk9ThtAxsClkwsPstvPstnStts "Reports when the current joystick position is on the positive travel side (forward, right, clockwise, up) relative to the neutral position for that axis of trav…";
CM_ SG_ 2365400574 Jstk9ThtAxsDtntPstnStts "Reports when the current joystick position is in the detent position for that axis of travel.00b = Not in the Detent Position01b = In the Detent Position10b = E…";
CM_ SG_ 2365400574 Jstk9ThtAxsNtrlPstnStts "Reports when the current joystick position is in the neutral position for that axis of travel.  The neutral position measurement must be determined from some me…";
CM_ BO_ 2365400830 "Basic Joystick Message 9";
CM_ SG_ 2365400830 Joystick9Button10PressedStatus "Reports when the joystick button has been pressed.00b = Button not pressed01b = Button pressed10b = Error Indicator11b = Not Available…";
CM_ SG_ 2365400830 Joystick9Button11PressedStatus "Reports when the joystick button has been pressed.00b = Button not pressed01b = Button pressed10b = Error Indicator11b = Not Available…";
CM_ SG_ 2365400830 Joystick9Button12PressedStatus "Reports when the joystick button has been pressed.00b = Button not pressed01b = Button pressed10b = Error Indicator11b = Not Available…";
CM_ SG_ 2365400830 Joystick9Button1PressedStatus "Reports when the joystick button has been pressed.00b = Button not pressed01b = Button pressed10b = Error Indicator11b = Not Available…";
CM_ SG_ 2365400830 Joystick9Button2PressedStatus "Reports when the joystick button has been pressed.00b = Button not pressed01b = Button pressed10b = Error Indicator11b = Not Available…";
CM_ SG_ 2365400830 Joystick9Button3PressedStatus "Reports when the joystick button has been pressed.00b = Button not pressed01b = Button pressed10b = Error Indicator11b = Not Available…";
CM_ SG_ 2365400830 Joystick9Button4PressedStatus "Reports when the joystick button has been pressed.00b = Button not pressed01b = Button pressed10b = Error Indicator11b = Not Available…";
CM_ SG_ 2365400830 Joystick9Button5PressedStatus "Reports when the joystick button has been pressed.00b = Button not pressed01b = Button pressed10b = Error Indicator11b = Not Available…";
CM_ SG_ 2365400830 Joystick9Button6PressedStatus "Reports when the joystick button has been pressed.00b = Button not pressed01b = Button pressed10b = Error Indicator11b = Not Available…";
CM_ SG_ 2365400830 Joystick9Button7PressedStatus "Reports when the joystick button has been pressed.00b = Button not pressed01b = Button pressed10b = Error Indicator11b = Not Available…";
CM_ SG_ 2365400830 Joystick9Button8PressedStatus "Reports when the joystick button has been pressed.00b = Button not pressed01b = Button pressed10b = Error Indicator11b = Not Available…";
CM_ SG_ 2365400830 Joystick9Button9PressedStatus "Reports when the joystick button has been pressed.00b = Button not pressed01b = Button pressed10b = Error Indicator11b = Not Available…";
CM_ SG_ 2365400830 Joystick9XAxisPosition "The position of the joystick in the relative motion of travel from the neutral position.  Position value of 0 is Neutral and position value 1000 (100%) is the e…";
CM_ SG_ 2365400830 Joystick9YAxisPosition "The position of the joystick in the relative motion of travel from the neutral position.  Position value of 0 is Neutral and position value 1000 (100%) is the e…";
CM_ SG_ 2365400830 Jstk9XAxsDtntPstnStts "Reports when the current joystick position is in the detent position for that axis of travel.00b = Not in the Detent Position01b = In the Detent Position10b = E…";
CM_ SG_ 2365400830 Jstk9XAxsLvrLftNgtvPstnStts "Reports when the current joystick position is on the negative travel side (back, left, counterclockwise, down) relative to the neutral position for that axis of…";
CM_ SG_ 2365400830 Jstk9XAxsLvrRghtPstvPstnStts "Reports when the current joystick position is on the positive travel side (forward, right, clockwise, up) relative to the neutral position for that axis of trav…";
CM_ SG_ 2365400830 Jstk9XAxsNtrlPstnStts "Reports when the current joystick position is in the neutral position for that axis of travel.  The neutral position measurement must be determined from some me…";
CM_ SG_ 2365400830 Jstk9YAxsDtntPstnStts "Reports when the current joystick position is in the detent position for that axis of travel.00b = Not in the Detent Position01b = In the Detent Position10b = E…";
CM_ SG_ 2365400830 Jstk9YAxsLvrBkNgtvPstnStts "Reports when the current joystick position is on the negative travel side (back, left, counterclockwise, down) relative to the neutral position for that axis of…";
CM_ SG_ 2365400830 Jstk9YAxsLvrFrwrdPstvPstnStts "Reports when the current joystick position is on the positive travel side (forward, right, clockwise, up) relative to the neutral position for that axis of trav…";
CM_ SG_ 2365400830 Jstk9YAxsNtrlPstnStts "Reports when the current joystick position is in the neutral position for that axis of travel.  The neutral position measurement must be determined from some me…";
CM_ BO_ 2365401086 "Extended Joystick Message 8";
CM_ SG_ 2365401086 Joystick8Button13PressedStatus "Reports when the joystick button has been pressed.00b = Button not pressed01b = Button pressed10b = Error Indicator11b = Not Available…";
CM_ SG_ 2365401086 Joystick8Button14PressedStatus "Reports when the joystick button has been pressed.00b = Button not pressed01b = Button pressed10b = Error Indicator11b = Not Available…";
CM_ SG_ 2365401086 Joystick8Button15PressedStatus "Reports when the joystick button has been pressed.00b = Button not pressed01b = Button pressed10b = Error Indicator11b = Not Available…";
CM_ SG_ 2365401086 Joystick8Button16PressedStatus "Reports when the joystick button has been pressed.00b = Button not pressed01b = Button pressed10b = Error Indicator11b = Not Available…";
CM_ SG_ 2365401086 Joystick8GripXAxisPosition "The position of the joystick grip in the relative motion of travel from the neutral position.  Position value of 0 is Neutral and position value 1000 (100%) is …";
CM_ SG_ 2365401086 Joystick8GripYAxisPosition "The position of the joystick grip in the relative motion of travel from the neutral position.  Position value of 0 is Neutral and position value 1000 (100%) is …";
CM_ SG_ 2365401086 Joystick8ThetaAxisPosition "The position of the joystick in the relative motion of travel from the neutral position.  Position value of 0 is Neutral and position value 1000 (100%) is the e…";
CM_ SG_ 2365401086 Jst8GpYAxsLvFwdPstvPstStts "Reports when the current joystick grip position is on the positive travel side (forward, right, clockwise, up) relative to the neutral position for that axis of…";
CM_ SG_ 2365401086 Jst8TtAxsCtCwsNtvPstStts "Reports when the current joystick position is on the negative travel side (back, left, counterclockwise, down) relative to the neutral position for that axis of…";
CM_ SG_ 2365401086 Jstk8GrpXAxsDtntPstnStts "Reports when the current joystick grip position is in the detent position for that axis of travel.00b = Not in the Detent Position01b = In the Detent Position10…";
CM_ SG_ 2365401086 Jstk8GrpXAxsLvrLftNgtvPstnStts "Reports when the current joystick grip position is on the negative travel side (back, left, counterclockwise, down) relative to the neutral position for that ax…";
CM_ SG_ 2365401086 Jstk8GrpXAxsLvrRghtPstvPstnStts "Reports when the current joystick grip position is on the positive travel side (forward, right, clockwise, up) relative to the neutral position for that axis of…";
CM_ SG_ 2365401086 Jstk8GrpXAxsNtrlPstnStts "Reports when the current joystick grip position is in the neutral position for that axis of travel.  The neutral position measurement must be determined from so…";
CM_ SG_ 2365401086 Jstk8GrpYAxsDtntPstnStts "Reports when the current joystick grip position is in the detent position for that axis of travel.00b = Not in the Detent Position01b = In the Detent Position10…";
CM_ SG_ 2365401086 Jstk8GrpYAxsLvrBkNgtvPstnStts "Reports when the current joystick grip position is on the negative travel side (back, left, counterclockwise, down) relative to the neutral position for that ax…";
CM_ SG_ 2365401086 Jstk8GrpYAxsNtrlPstnStts "Reports when the current joystick grip position is in the neutral position for that axis of travel.  The neutral position measurement must be determined from so…";
CM_ SG_ 2365401086 Jstk8ThtAxsClkwsPstvPstnStts "Reports when the current joystick position is on the positive travel side (forward, right, clockwise, up) relative to the neutral position for that axis of trav…";
CM_ SG_ 2365401086 Jstk8ThtAxsDtntPstnStts "Reports when the current joystick position is in the detent position for that axis of travel.00b = Not in the Detent Position01b = In the Detent Position10b = E…";
CM_ SG_ 2365401086 Jstk8ThtAxsNtrlPstnStts "Reports when the current joystick position is in the neutral position for that axis of travel.  The neutral position measurement must be determined from some me…";
CM_ BO_ 2365401342 "Basic Joystick Message 8";
CM_ SG_ 2365401342 Joystick8Button10PressedStatus "Reports when the joystick button has been pressed.00b = Button not pressed01b = Button pressed10b = Error Indicator11b = Not Available…";
CM_ SG_ 2365401342 Joystick8Button11PressedStatus "Reports when the joystick button has been pressed.00b = Button not pressed01b = Button pressed10b = Error Indicator11b = Not Available…";
CM_ SG_ 2365401342 Joystick8Button12PressedStatus "Reports when the joystick button has been pressed.00b = Button not pressed01b = Button pressed10b = Error Indicator11b = Not Available…";
CM_ SG_ 2365401342 Joystick8Button1PressedStatus "Reports when the joystick button has been pressed.00b = Button not pressed01b = Button pressed10b = Error Indicator11b = Not Available…";
CM_ SG_ 2365401342 Joystick8Button2PressedStatus "Reports when the joystick button has been pressed.00b = Button not pressed01b = Button pressed10b = Error Indicator11b = Not Available…";
CM_ SG_ 2365401342 Joystick8Button3PressedStatus "Reports when the joystick button has been pressed.00b = Button not pressed01b = Button pressed10b = Error Indicator11b = Not Available…";
CM_ SG_ 2365401342 Joystick8Button4PressedStatus "Reports when the joystick button has been pressed.00b = Button not pressed01b = Button pressed10b = Error Indicator11b = Not Available…";
CM_ SG_ 2365401342 Joystick8Button5PressedStatus "Reports when the joystick button has been pressed.00b = Button not pressed01b = Button pressed10b = Error Indicator11b = Not Available…";
CM_ SG_ 2365401342 Joystick8Button6PressedStatus "Reports when the joystick button has been pressed.00b = Button not pressed01b = Button pressed10b = Error Indicator11b = Not Available…";
CM_ SG_ 2365401342 Joystick8Button7PressedStatus "Reports when the joystick button has been pressed.00b = Button not pressed01b = Button pressed10b = Error Indicator11b = Not Available…";
CM_ SG_ 2365401342 Joystick8Button8PressedStatus "Reports when the joystick button has been pressed.00b = Button not pressed01b = Button pressed10b = Error Indicator11b = Not Available…";
CM_ SG_ 2365401342 Joystick8Button9PressedStatus "Reports when the joystick button has been pressed.00b = Button not pressed01b = Button pressed10b = Error Indicator11b = Not Available…";
CM_ SG_ 2365401342 Joystick8XAxisPosition "The position of the joystick in the relative motion of travel from the neutral position.  Position value of 0 is Neutral and position value 1000 (100%) is the e…";
CM_ SG_ 2365401342 Joystick8YAxisPosition "The position of the joystick in the relative motion of travel from the neutral position.  Position value of 0 is Neutral and position value 1000 (100%) is the e…";
CM_ SG_ 2365401342 Jstk8XAxsDtntPstnStts "Reports when the current joystick position is in the detent position for that axis of travel.00b = Not in the Detent Position01b = In the Detent Position10b = E…";
CM_ SG_ 2365401342 Jstk8XAxsLvrLftNgtvPstnStts "Reports when the current joystick position is on the negative travel side (back, left, counterclockwise, down) relative to the neutral position for that axis of…";
CM_ SG_ 2365401342 Jstk8XAxsLvrRghtPstvPstnStts "Reports when the current joystick position is on the positive travel side (forward, right, clockwise, up) relative to the neutral position for that axis of trav…";
CM_ SG_ 2365401342 Jstk8XAxsNtrlPstnStts "Reports when the current joystick position is in the neutral position for that axis of travel.  The neutral position measurement must be determined from some me…";
CM_ SG_ 2365401342 Jstk8YAxsDtntPstnStts "Reports when the current joystick position is in the detent position for that axis of travel.00b = Not in the Detent Position01b = In the Detent Position10b = E…";
CM_ SG_ 2365401342 Jstk8YAxsLvrBkNgtvPstnStts "Reports when the current joystick position is on the negative travel side (back, left, counterclockwise, down) relative to the neutral position for that axis of…";
CM_ SG_ 2365401342 Jstk8YAxsLvrFrwrdPstvPstnStts "Reports when the current joystick position is on the positive travel side (forward, right, clockwise, up) relative to the neutral position for that axis of trav…";
CM_ SG_ 2365401342 Jstk8YAxsNtrlPstnStts "Reports when the current joystick position is in the neutral position for that axis of travel.  The neutral position measurement must be determined from some me…";
BA_DEF_ SG_  "SPN" INT 0 524287;
BA_DEF_ BO_  "VFrameFormat" ENUM  "StandardCAN","ExtendedCAN","reserved","J1939PG";
BA_DEF_DEF_  "SPN" 0;
BA_DEF_DEF_  "VFrameFormat" "J1939PG";
BA_ "SPN" SG_ 2364590334 DCACAssrInvrtr1DCSdCrrnt 8891;
BA_ "SPN" SG_ 2364590334 DCACAssrInvrtr1DCSdPwr 8889;
BA_ "SPN" SG_ 2364590334 DCACAssrInvrtr1DCSdVltg 8890;
BA_ "SPN" SG_ 2364590334 DCACAssIvt1DCSdNtvtCsssGdVt 9582;
BA_ "SPN" SG_ 2364590590 DCACAssrInvrtr1IgntnVltg 9209;
BA_ "SPN" SG_ 2364590590 DCACAssrInvrtr1SLIVltg 9210;
BA_ "SPN" SG_ 2364591102 DCACAssrInvrtr2DCSdCrrnt 9238;
BA_ "SPN" SG_ 2364591102 DCACAssrInvrtr2DCSdPwr 9236;
BA_ "SPN" SG_ 2364591102 DCACAssrInvrtr2DCSdVltg 9237;
BA_ "SPN" SG_ 2364591102 DCACAssIvt2DCSdNtvtCsssGdVt 9583;
BA_ "SPN" SG_ 2364591358 DCACAssrInvrtr2IgntnVltg 9239;
BA_ "SPN" SG_ 2364591358 DCACAssrInvrtr2SLIVltg 9240;
BA_ "SPN" SG_ 2364592382 EngnClndr10ExldfrmCmstnRqst 7001;
BA_ "SPN" SG_ 2364592382 EngnClndr11ExldfrmCmstnRqst 7002;
BA_ "SPN" SG_ 2364592382 EngnClndr12ExldfrmCmstnRqst 7003;
BA_ "SPN" SG_ 2364592382 EngnClndr13ExldfrmCmstnRqst 7004;
BA_ "SPN" SG_ 2364592382 EngnClndr14ExldfrmCmstnRqst 7005;
BA_ "SPN" SG_ 2364592382 EngnClndr15ExldfrmCmstnRqst 7006;
BA_ "SPN" SG_ 2364592382 EngnClndr16ExldfrmCmstnRqst 7007;
BA_ "SPN" SG_ 2364592382 EngnClndr17ExldfrmCmstnRqst 7008;
BA_ "SPN" SG_ 2364592382 EngnClndr18ExldfrmCmstnRqst 7009;
BA_ "SPN" SG_ 2364592382 EngnClndr19ExldfrmCmstnRqst 7010;
BA_ "SPN" SG_ 2364592382 EngnClndr1ExldfrmCmstnRqst 6992;
BA_ "SPN" SG_ 2364592382 EngnClndr20ExldfrmCmstnRqst 7011;
BA_ "SPN" SG_ 2364592382 EngnClndr21ExldfrmCmstnRqst 7012;
BA_ "SPN" SG_ 2364592382 EngnClndr22ExldfrmCmstnRqst 7013;
BA_ "SPN" SG_ 2364592382 EngnClndr23ExldfrmCmstnRqst 7014;
BA_ "SPN" SG_ 2364592382 EngnClndr24ExldfrmCmstnRqst 7015;
BA_ "SPN" SG_ 2364592382 EngnClndr2ExldfrmCmstnRqst 6993;
BA_ "SPN" SG_ 2364592382 EngnClndr3ExldfrmCmstnRqst 6994;
BA_ "SPN" SG_ 2364592382 EngnClndr4ExldfrmCmstnRqst 6995;
BA_ "SPN" SG_ 2364592382 EngnClndr5ExldfrmCmstnRqst 6996;
BA_ "SPN" SG_ 2364592382 EngnClndr6ExldfrmCmstnRqst 6997;
BA_ "SPN" SG_ 2364592382 EngnClndr7ExldfrmCmstnRqst 6998;
BA_ "SPN" SG_ 2364592382 EngnClndr8ExldfrmCmstnRqst 6999;
BA_ "SPN" SG_ 2364592382 EngnClndr9ExldfrmCmstnRqst 7000;
BA_ "SPN" SG_ 2364592382 NmrfEngnClndrstExldfrmCmstn 6991;
BA_ "SPN" SG_ 2364592638 EngnClndrHdBpssAttr1DsrdPstn 7091;
BA_ "SPN" SG_ 2364592638 EngnClndrHdBpssAttr1OprtnStts 7093;
BA_ "SPN" SG_ 2364592638 EngnClndrHdBpssAttr1PrlmnrFMI 7088;
BA_ "SPN" SG_ 2364592638 EngnClndrHdBpssAttr1Pstn 7092;
BA_ "SPN" SG_ 2364592638 EngnClndrHdBpssAttr1Tmprtr 7090;
BA_ "SPN" SG_ 2364592638 EngnClndrHdBpssAttr1TmprtrStts 7089;
BA_ "SPN" SG_ 2364592894 EngineIntakeAirSourceValve 6330;
BA_ "SPN" SG_ 2364592894 EngnClndrHdBpssAttr1Cmmnd 7094;
BA_ "SPN" SG_ 2364592894 EngnExhstGsRstrtnVlvPstn 8151;
BA_ "SPN" SG_ 2364593150 PrdtvCrsCntrlDrvlnDsnggInhtRqst 7430;
BA_ "SPN" SG_ 2364593150 PrdtvCrsCntrlEvntnRng 7431;
BA_ "SPN" SG_ 2364593150 PrdtvCrsCntrlSpdEvntIndtr 7434;
BA_ "SPN" SG_ 2364593150 PrdtvCrsCntrlStSpdOffst 7316;
BA_ "SPN" SG_ 2364593150 PredictiveCruiseControlState 7317;
BA_ "SPN" SG_ 2364593150 RoadwayNextGrade 7433;
BA_ "SPN" SG_ 2364593150 RoadwayNextGradeDistance 9199;
BA_ "SPN" SG_ 2364593150 RoadwayPresentGrade 7432;
BA_ "SPN" SG_ 2364593150 VhlSpdCntrlOvrrdEvntIndtr 7435;
BA_ "SPN" SG_ 2364593150 VhlSpdCntrlOvrrdRqst 7429;
BA_ "SPN" SG_ 2364597758 EngnClndr1IgntnTmngOffst 7356;
BA_ "SPN" SG_ 2364597758 EngnClndr2IgntnTmngOffst 7357;
BA_ "SPN" SG_ 2364597758 EngnClndr3IgntnTmngOffst 7358;
BA_ "SPN" SG_ 2364597758 EngnClndr4IgntnTmngOffst 7359;
BA_ "SPN" SG_ 2364597758 EngnClndr5IgntnTmngOffst 7360;
BA_ "SPN" SG_ 2364597758 EngnClndr6IgntnTmngOffst 7361;
BA_ "SPN" SG_ 2364597758 EngnClndr7IgntnTmngOffst 7362;
BA_ "SPN" SG_ 2364597758 EngnClndr8IgntnTmngOffst 7363;
BA_ "SPN" SG_ 2364598014 EngnClndr10IgntnTmngOffst 7365;
BA_ "SPN" SG_ 2364598014 EngnClndr11IgntnTmngOffst 7366;
BA_ "SPN" SG_ 2364598014 EngnClndr12IgntnTmngOffst 7367;
BA_ "SPN" SG_ 2364598014 EngnClndr13IgntnTmngOffst 7368;
BA_ "SPN" SG_ 2364598014 EngnClndr14IgntnTmngOffst 7369;
BA_ "SPN" SG_ 2364598014 EngnClndr15IgntnTmngOffst 7370;
BA_ "SPN" SG_ 2364598014 EngnClndr16IgntnTmngOffst 7371;
BA_ "SPN" SG_ 2364598014 EngnClndr9IgntnTmngOffst 7364;
BA_ "SPN" SG_ 2364598270 EngnClndr17IgntnTmngOffst 7372;
BA_ "SPN" SG_ 2364598270 EngnClndr18IgntnTmngOffst 7373;
BA_ "SPN" SG_ 2364598270 EngnClndr19IgntnTmngOffst 7374;
BA_ "SPN" SG_ 2364598270 EngnClndr20IgntnTmngOffst 7375;
BA_ "SPN" SG_ 2364598270 EngnClndr21IgntnTmngOffst 7376;
BA_ "SPN" SG_ 2364598270 EngnClndr22IgntnTmngOffst 7377;
BA_ "SPN" SG_ 2364598270 EngnClndr23IgntnTmngOffst 7378;
BA_ "SPN" SG_ 2364598270 EngnClndr24IgntnTmngOffst 7379;
BA_ "SPN" SG_ 2364598526 EngnFlAttr3CntrlCmmnd 7593;
BA_ "SPN" SG_ 2364598526 EngnFlAttr4CntrlCmmnd 7594;
BA_ "SPN" SG_ 2364602878 EngnVlvCntrlMdl1PrlmnrFMI 7770;
BA_ "SPN" SG_ 2364602878 EngnVlvCntrlMdl2PrlmnrFMI 7771;
BA_ "SPN" SG_ 2364602878 EngnVlvCntrlMdl3PrlmnrFMI 7772;
BA_ "SPN" SG_ 2364602878 EngnVlvCntrlMdl4PrlmnrFMI 7773;
BA_ "SPN" SG_ 2364602878 EngnVlvCntrlMdl5PrlmnrFMI 7774;
BA_ "SPN" SG_ 2364602878 EngnVlvCntrlMdl6PrlmnrFMI 7775;
BA_ "SPN" SG_ 2364602878 EngnVlvCntrlMdl7PrlmnrFMI 7776;
BA_ "SPN" SG_ 2364602878 EngnVlvCntrlMdl8PrlmnrFMI 7777;
BA_ "SPN" SG_ 2364603134 MxmmFrwrdTrnsmssnOtptShftSpd 7779;
BA_ "SPN" SG_ 2364603134 MxmmRvrsTrnsmssnOtptShftSpd 7780;
BA_ "SPN" SG_ 2364603134 SAddssAtvPdTsssRqstdG 8613;
BA_ "SPN" SG_ 2364603390 Atttt1DsExstFdDsVv1Cd 8442;
BA_ "SPN" SG_ 2364603390 Atttt1DsExstFdRqstdQttIttHRst 7783;
BA_ "SPN" SG_ 2364603646 Atttt2DsExstFdRqstdQttIttHRst 7784;
BA_ "SPN" SG_ 2364603902 Atttt1DsExstFdAtQttIttHRst 7786;
BA_ "SPN" SG_ 2364604158 Atttt2DsExstFdAtQttIttHRst 7787;
BA_ "SPN" SG_ 2364605438 GeneratorTripkVArHoursExport 7832;
BA_ "SPN" SG_ 2364605438 GeneratorTripkWHoursExport 7831;
BA_ "SPN" SG_ 2364605950 HydraulicLinePressure 7939;
BA_ "SPN" SG_ 2364605950 MechanicalMovementAngle 7940;
BA_ "SPN" SG_ 2364606718 HVES1Module10OperationalStatus 8223;
BA_ "SPN" SG_ 2364606718 HVES1Module11OperationalStatus 8224;
BA_ "SPN" SG_ 2364606718 HVES1Module12OperationalStatus 8225;
BA_ "SPN" SG_ 2364606718 HVES1Module13OperationalStatus 8226;
BA_ "SPN" SG_ 2364606718 HVES1Module14OperationalStatus 8227;
BA_ "SPN" SG_ 2364606718 HVES1Module15OperationalStatus 8228;
BA_ "SPN" SG_ 2364606718 HVES1Module16OperationalStatus 8229;
BA_ "SPN" SG_ 2364606718 HVES1Module1OperationalStatus 8214;
BA_ "SPN" SG_ 2364606718 HVES1Module2OperationalStatus 8215;
BA_ "SPN" SG_ 2364606718 HVES1Module3OperationalStatus 8216;
BA_ "SPN" SG_ 2364606718 HVES1Module4OperationalStatus 8217;
BA_ "SPN" SG_ 2364606718 HVES1Module5OperationalStatus 8218;
BA_ "SPN" SG_ 2364606718 HVES1Module6OperationalStatus 8219;
BA_ "SPN" SG_ 2364606718 HVES1Module7OperationalStatus 8220;
BA_ "SPN" SG_ 2364606718 HVES1Module8OperationalStatus 8221;
BA_ "SPN" SG_ 2364606718 HVES1Module9OperationalStatus 8222;
BA_ "SPN" SG_ 2364606974 HVES1ThrmlMngmntSstmCmprssrSpd 8232;
BA_ "SPN" SG_ 2364606974 HVES1ThrmlMngmntSstmHtrStts 8234;
BA_ "SPN" SG_ 2364606974 HVES1ThrmlMngmntSstmMd 8235;
BA_ "SPN" SG_ 2364606974 HVES1ThrmlMngmntSstmRltvHmdt 8233;
BA_ "SPN" SG_ 2364606974 HVES1ThrmlMngmntSstmSLIInptPwr 8230;
BA_ "SPN" SG_ 2364606974 HVES1TMtSstHVtIptPw 8231;
BA_ "SPN" SG_ 2364607230 HVES1AverageCellVoltage 8240;
BA_ "SPN" SG_ 2364607230 HVES1HghstCllVltgCllNmr 8237;
BA_ "SPN" SG_ 2364607230 HVES1HghstCllVltgMdlNmr 8236;
BA_ "SPN" SG_ 2364607230 HVES1LwstCllVltgCllNmr 8239;
BA_ "SPN" SG_ 2364607230 HVES1LwstCllVltgMdlNmr 8238;
BA_ "SPN" SG_ 2364607486 HVES1HghstCllTmprtrCllNmr 8242;
BA_ "SPN" SG_ 2364607486 HVES1HghstCllTmprtrMdlNmr 8241;
BA_ "SPN" SG_ 2364607486 HVES1LwstCllTmprtrCllNmr 8244;
BA_ "SPN" SG_ 2364607486 HVES1LwstCllTmprtrMdlNmr 8243;
BA_ "SPN" SG_ 2364607742 HVES1HghstCllSttfChrgCllNmr 8246;
BA_ "SPN" SG_ 2364607742 HVES1HghstCllSttfChrgMdlNmr 8245;
BA_ "SPN" SG_ 2364607742 HVES1HghVltgBsAtvIsltnTstRslts 8431;
BA_ "SPN" SG_ 2364607742 HVES1HghVltgBsPssvIsltnTstRslts 8432;
BA_ "SPN" SG_ 2364607742 HVES1LwstCllSttfChrgCllNmr 8248;
BA_ "SPN" SG_ 2364607742 HVES1LwstCllSttfChrgMdlNmr 8247;
BA_ "SPN" SG_ 2364608510 EnginePowerDerateRequest 8436;
BA_ "SPN" SG_ 2364608510 EngineSelfInducedDerateLoad 8435;
BA_ "SPN" SG_ 2364609278 DCDC1HghSdVltgBstStpnt 8562;
BA_ "SPN" SG_ 2364609278 DCDC1LowSideVoltageBuckSetpoint 8561;
BA_ "SPN" SG_ 2364609278 DCDC1LwSdVltgBkDfltStpnt 9515;
BA_ "SPN" SG_ 2364609278 DCDC1OperationalCommand 8560;
BA_ "SPN" SG_ 2364609534 DCDC1HVILStatus 8570;
BA_ "SPN" SG_ 2364609534 DCDC1LoadshedRequest 8571;
BA_ "SPN" SG_ 2364609534 DCDC1OperationalStatus 8569;
BA_ "SPN" SG_ 2364609534 DCDC1PwrLmtdtCnvrtrTmprtr 8578;
BA_ "SPN" SG_ 2364609534 DCDC1PwrLmtdtEltrnFltrTmprtr 8579;
BA_ "SPN" SG_ 2364609534 DCDC1PwrLmtdtHghSdCrrnt 8572;
BA_ "SPN" SG_ 2364609534 DCDC1PwrLmtdtHghSdVltgMnmm 8574;
BA_ "SPN" SG_ 2364609534 DCDC1PwrLmtdtHghSdVltgMxmm 8575;
BA_ "SPN" SG_ 2364609534 DCDC1PwrLmtdtLwSdCrrnt 8573;
BA_ "SPN" SG_ 2364609534 DCDC1PwrLmtdtLwSdVltgMnmm 8576;
BA_ "SPN" SG_ 2364609534 DCDC1PwrLmtdtLwSdVltgMxmm 8577;
BA_ "SPN" SG_ 2364609534 DCDC1PwrLmtdtPwrEltrnsTmprtr 8580;
BA_ "SPN" SG_ 2364609534 DCDC1PwrLmtdtSLIBttrTrmnlCrrnt 8583;
BA_ "SPN" SG_ 2364609534 DCDC1PwrLmtdtSLIBttrTrmnlTmprtr 8582;
BA_ "SPN" SG_ 2364609534 DCDC1PwrLmtdtSLIBttrTrmnlVltg 8581;
BA_ "SPN" SG_ 2364609534 DCDC1PwrLmtdtUndfndRsn 8584;
BA_ "SPN" SG_ 2364609790 DCDC1HighSideCurrent 8588;
BA_ "SPN" SG_ 2364609790 DCDC1HighSideVoltage 8587;
BA_ "SPN" SG_ 2364609790 DCDC1LowSideCurrent 8586;
BA_ "SPN" SG_ 2364609790 DCDC1LowSideVoltage 8585;
BA_ "SPN" SG_ 2364610046 DCDC1SLIBatteryTerminalCurrent 8590;
BA_ "SPN" SG_ 2364610046 DCDC1SLIBatteryTerminalVoltage 8589;
BA_ "SPN" SG_ 2364610046 DCDC1SLIBttrTrmnlTmprtr 8591;
BA_ "SPN" SG_ 2364610558 DCDC1HighSidePower 8821;
BA_ "SPN" SG_ 2364610558 DCDC1LowSidePower 8820;
BA_ "SPN" SG_ 2364610558 DCDC1HghSdNgtvtChsssGrndVltg 9587;
BA_ "SPN" SG_ 2364610814 DCDC2HghSdVltgBstStpnt 8894;
BA_ "SPN" SG_ 2364610814 DCDC2LowSideVoltageBuckSetpoint 8893;
BA_ "SPN" SG_ 2364610814 DCDC2LwSdVltgBkDfltStpnt 9516;
BA_ "SPN" SG_ 2364610814 DCDC2OperationalCommand 8892;
BA_ "SPN" SG_ 2364611070 DCDC2HVILStatus 8896;
BA_ "SPN" SG_ 2364611070 DCDC2LoadshedRequest 8897;
BA_ "SPN" SG_ 2364611070 DCDC2OperationalStatus 8895;
BA_ "SPN" SG_ 2364611070 DCDC2PwrLmtdtCnvrtrTmprtr 8904;
BA_ "SPN" SG_ 2364611070 DCDC2PwrLmtdtEltrnFltrTmprtr 8905;
BA_ "SPN" SG_ 2364611070 DCDC2PwrLmtdtHghSdCrrnt 8898;
BA_ "SPN" SG_ 2364611070 DCDC2PwrLmtdtHghSdVltgMnmm 8900;
BA_ "SPN" SG_ 2364611070 DCDC2PwrLmtdtHghSdVltgMxmm 8901;
BA_ "SPN" SG_ 2364611070 DCDC2PwrLmtdtLwSdCrrnt 8899;
BA_ "SPN" SG_ 2364611070 DCDC2PwrLmtdtLwSdVltgMnmm 8902;
BA_ "SPN" SG_ 2364611070 DCDC2PwrLmtdtLwSdVltgMxmm 8903;
BA_ "SPN" SG_ 2364611070 DCDC2PwrLmtdtPwrEltrnsTmprtr 8906;
BA_ "SPN" SG_ 2364611070 DCDC2PwrLmtdtSLIBttrTrmnlCrrnt 8908;
BA_ "SPN" SG_ 2364611070 DCDC2PwrLmtdtSLIBttrTrmnlTmprtr 8909;
BA_ "SPN" SG_ 2364611070 DCDC2PwrLmtdtSLIBttrTrmnlVltg 8907;
BA_ "SPN" SG_ 2364611070 DCDC2PwrLmtdtUndfndRsn 8910;
BA_ "SPN" SG_ 2364611326 DCDC2HighSideCurrent 8914;
BA_ "SPN" SG_ 2364611326 DCDC2HighSideVoltage 8913;
BA_ "SPN" SG_ 2364611326 DCDC2LowSideCurrent 8912;
BA_ "SPN" SG_ 2364611326 DCDC2LowSideVoltage 8911;
BA_ "SPN" SG_ 2364611582 DCDC2SLIBatteryTerminalCurrent 8916;
BA_ "SPN" SG_ 2364611582 DCDC2SLIBatteryTerminalVoltage 8915;
BA_ "SPN" SG_ 2364611582 DCDC2SLIBttrTrmnlTmprtr 8917;
BA_ "SPN" SG_ 2364611838 DCDC2HighSidePower 8919;
BA_ "SPN" SG_ 2364611838 DCDC2LowSidePower 8918;
BA_ "SPN" SG_ 2364611838 DCDC2HghSdNgtvtChsssGrndVltg 9588;
BA_ "SPN" SG_ 2364612094 DCDC3HghSdVltgBstStpnt 8949;
BA_ "SPN" SG_ 2364612094 DCDC3LowSideVoltageBuckSetpoint 8948;
BA_ "SPN" SG_ 2364612094 DCDC3LwSdVltgBkDfltStpnt 9517;
BA_ "SPN" SG_ 2364612094 DCDC3OperationalCommand 8947;
BA_ "SPN" SG_ 2364612350 DCDC3HVILStatus 8951;
BA_ "SPN" SG_ 2364612350 DCDC3LoadshedRequest 8952;
BA_ "SPN" SG_ 2364612350 DCDC3OperationalStatus 8950;
BA_ "SPN" SG_ 2364612350 DCDC3PwrLmtdtCnvrtrTmprtr 8959;
BA_ "SPN" SG_ 2364612350 DCDC3PwrLmtdtEltrnFltrTmprtr 8960;
BA_ "SPN" SG_ 2364612350 DCDC3PwrLmtdtHghSdCrrnt 8953;
BA_ "SPN" SG_ 2364612350 DCDC3PwrLmtdtHghSdVltgMnmm 8955;
BA_ "SPN" SG_ 2364612350 DCDC3PwrLmtdtHghSdVltgMxmm 8956;
BA_ "SPN" SG_ 2364612350 DCDC3PwrLmtdtLwSdCrrnt 8954;
BA_ "SPN" SG_ 2364612350 DCDC3PwrLmtdtLwSdVltgMnmm 8957;
BA_ "SPN" SG_ 2364612350 DCDC3PwrLmtdtLwSdVltgMxmm 8958;
BA_ "SPN" SG_ 2364612350 DCDC3PwrLmtdtPwrEltrnsTmprtr 8961;
BA_ "SPN" SG_ 2364612350 DCDC3PwrLmtdtSLIBttrTrmnlCrrnt 8963;
BA_ "SPN" SG_ 2364612350 DCDC3PwrLmtdtSLIBttrTrmnlTmprtr 8964;
BA_ "SPN" SG_ 2364612350 DCDC3PwrLmtdtSLIBttrTrmnlVltg 8962;
BA_ "SPN" SG_ 2364612350 DCDC3PwrLmtdtUndfndRsn 8965;
BA_ "SPN" SG_ 2364612606 DCDC3HighSideCurrent 8969;
BA_ "SPN" SG_ 2364612606 DCDC3HighSideVoltage 8968;
BA_ "SPN" SG_ 2364612606 DCDC3LowSideCurrent 8967;
BA_ "SPN" SG_ 2364612606 DCDC3LowSideVoltage 8966;
BA_ "SPN" SG_ 2364612862 DCDC3SLIBatteryTerminalCurrent 8971;
BA_ "SPN" SG_ 2364612862 DCDC3SLIBatteryTerminalVoltage 8970;
BA_ "SPN" SG_ 2364612862 DCDC3SLIBttrTrmnlTmprtr 8972;
BA_ "SPN" SG_ 2364613118 DCDC3HighSidePower 8974;
BA_ "SPN" SG_ 2364613118 DCDC3LowSidePower 8973;
BA_ "SPN" SG_ 2364613118 DCDC3HghSdNgtvtChsssGrndVltg 9589;
BA_ "SPN" SG_ 2364613374 DCDC4HghSdVltgBstStpnt 9004;
BA_ "SPN" SG_ 2364613374 DCDC4LowSideVoltageBuckSetpoint 9003;
BA_ "SPN" SG_ 2364613374 DCDC4LwSdVltgBkDfltStpnt 9518;
BA_ "SPN" SG_ 2364613374 DCDC4OperationalCommand 9002;
BA_ "SPN" SG_ 2364613630 DCDC4HVILStatus 9006;
BA_ "SPN" SG_ 2364613630 DCDC4LoadshedRequest 9007;
BA_ "SPN" SG_ 2364613630 DCDC4OperationalStatus 9005;
BA_ "SPN" SG_ 2364613630 DCDC4PwrLmtdtCnvrtrTmprtr 9014;
BA_ "SPN" SG_ 2364613630 DCDC4PwrLmtdtEltrnFltrTmprtr 9015;
BA_ "SPN" SG_ 2364613630 DCDC4PwrLmtdtHghSdCrrnt 9008;
BA_ "SPN" SG_ 2364613630 DCDC4PwrLmtdtHghSdVltgMnmm 9010;
BA_ "SPN" SG_ 2364613630 DCDC4PwrLmtdtHghSdVltgMxmm 9011;
BA_ "SPN" SG_ 2364613630 DCDC4PwrLmtdtLwSdCrrnt 9009;
BA_ "SPN" SG_ 2364613630 DCDC4PwrLmtdtLwSdVltgMnmm 9012;
BA_ "SPN" SG_ 2364613630 DCDC4PwrLmtdtLwSdVltgMxmm 9013;
BA_ "SPN" SG_ 2364613630 DCDC4PwrLmtdtPwrEltrnsTmprtr 9016;
BA_ "SPN" SG_ 2364613630 DCDC4PwrLmtdtSLIBttrTrmnlCrrnt 9018;
BA_ "SPN" SG_ 2364613630 DCDC4PwrLmtdtSLIBttrTrmnlTmprtr 9019;
BA_ "SPN" SG_ 2364613630 DCDC4PwrLmtdtSLIBttrTrmnlVltg 9017;
BA_ "SPN" SG_ 2364613630 DCDC4PwrLmtdtUndfndRsn 9020;
BA_ "SPN" SG_ 2364613886 DCDC4HighSideCurrent 9024;
BA_ "SPN" SG_ 2364613886 DCDC4HighSideVoltage 9023;
BA_ "SPN" SG_ 2364613886 DCDC4LowSideCurrent 9022;
BA_ "SPN" SG_ 2364613886 DCDC4LowSideVoltage 9021;
BA_ "SPN" SG_ 2364614142 DCDC4SLIBatteryTerminalCurrent 9026;
BA_ "SPN" SG_ 2364614142 DCDC4SLIBatteryTerminalVoltage 9025;
BA_ "SPN" SG_ 2364614142 DCDC4SLIBttrTrmnlTmprtr 9027;
BA_ "SPN" SG_ 2364614398 DCDC4HighSidePower 9029;
BA_ "SPN" SG_ 2364614398 DCDC4LowSidePower 9028;
BA_ "SPN" SG_ 2364614398 DCDC4HghSdNgtvtChsssGrndVltg 9590;
BA_ "SPN" SG_ 2364614654 GradeThresholdIndicator1 9181;
BA_ "SPN" SG_ 2364614654 GradeThresholdIndicator2 9182;
BA_ "SPN" SG_ 2364614654 GradeThresholdIndicator3 9183;
BA_ "SPN" SG_ 2364614654 GradeThresholdIndicator4 9184;
BA_ "SPN" SG_ 2364614654 GradeThresholdIndicator5 9185;
BA_ "SPN" SG_ 2364614654 GradeThresholdIndicator6 9186;
BA_ "SPN" SG_ 2364614910 DCACAssrInvrtr3DCSdCrrnt 9268;
BA_ "SPN" SG_ 2364614910 DCACAssrInvrtr3DCSdPwr 9266;
BA_ "SPN" SG_ 2364614910 DCACAssrInvrtr3DCSdVltg 9267;
BA_ "SPN" SG_ 2364614910 DCACAssIvt3DCSdNtvtCsssGdVt 9584;
BA_ "SPN" SG_ 2364615166 DCACAssrInvrtr3IgntnVltg 9269;
BA_ "SPN" SG_ 2364615166 DCACAssrInvrtr3SLIVltg 9270;
BA_ "SPN" SG_ 2364615678 DCACAssrInvrtr4DCSdCrrnt 9298;
BA_ "SPN" SG_ 2364615678 DCACAssrInvrtr4DCSdPwr 9296;
BA_ "SPN" SG_ 2364615678 DCACAssrInvrtr4DCSdVltg 9297;
BA_ "SPN" SG_ 2364615678 DCACAssIvt4DCSdNtvtCsssGdVt 9585;
BA_ "SPN" SG_ 2364615934 DCACAssrInvrtr4IgntnVltg 9299;
BA_ "SPN" SG_ 2364615934 DCACAssrInvrtr4SLIVltg 9300;
BA_ "SPN" SG_ 2364616958 DCACAssrInvrtr5DCSdCrrnt 9344;
BA_ "SPN" SG_ 2364616958 DCACAssrInvrtr5DCSdPwr 9342;
BA_ "SPN" SG_ 2364616958 DCACAssrInvrtr5DCSdVltg 9343;
BA_ "SPN" SG_ 2364616958 DCACAssIvt5DCSdNtvtCsssGdVt 9586;
BA_ "SPN" SG_ 2364617214 DCACAssrInvrtr5IgntnVltg 9345;
BA_ "SPN" SG_ 2364617214 DCACAssrInvrtr5SLIVltg 9346;
BA_ "SPN" SG_ 2365296894 DCDC4CntrllrInptIgntnVltg 9564;
BA_ "SPN" SG_ 2365296894 DCDC4ControllerInputSLIVoltage 9565;
BA_ "SPN" SG_ 2365297150 DCDC3CntrllrInptIgntnVltg 9562;
BA_ "SPN" SG_ 2365297150 DCDC3ControllerInputSLIVoltage 9563;
BA_ "SPN" SG_ 2365297406 DCDC2CntrllrInptIgntnVltg 9560;
BA_ "SPN" SG_ 2365297406 DCDC2ControllerInputSLIVoltage 9561;
BA_ "SPN" SG_ 2365297662 DCDC1CntrllrInptIgntnVltg 9558;
BA_ "SPN" SG_ 2365297662 DCDC1ControllerInputSLIVoltage 9559;
BA_ "SPN" SG_ 2365299454 DCACAssIvt1DCSdCtMLtRqst 9530;
BA_ "SPN" SG_ 2365299454 DCACAssIvt1DCSdCtMxLtRqst 9222;
BA_ "SPN" SG_ 2365299454 DCACAssIvt1DCSdVtMLtRqst 9221;
BA_ "SPN" SG_ 2365299454 DCACAssIvt1DCSdVtMxLtRqst 9529;
BA_ "SPN" SG_ 2365299710 DCACAssIvt1ACSdRMSCtMxLtRqst 9224;
BA_ "SPN" SG_ 2365299710 DCACAssIvt1ACSdRMSVtMxLtRqst 9223;
BA_ "SPN" SG_ 2365299710 DCACAssrInvrtr1ACSdDfltFrqnRqst 9523;
BA_ "SPN" SG_ 2365300734 DCACAssIvt2DCSdCtMLtRqst 9536;
BA_ "SPN" SG_ 2365300734 DCACAssIvt2DCSdCtMxLtRqst 9252;
BA_ "SPN" SG_ 2365300734 DCACAssIvt2DCSdVtMLtRqst 9251;
BA_ "SPN" SG_ 2365300734 DCACAssIvt2DCSdVtMxLtRqst 9535;
BA_ "SPN" SG_ 2365300990 DCACAssIvt2ACSdRMSCtMxLtRqst 9254;
BA_ "SPN" SG_ 2365300990 DCACAssIvt2ACSdRMSVtMxLtRqst 9253;
BA_ "SPN" SG_ 2365300990 DCACAssrInvrtr2ACSdDfltFrqnRqst 9524;
BA_ "SPN" SG_ 2365302014 DCACAssIvt3DCSdCtMLtRqst 9542;
BA_ "SPN" SG_ 2365302014 DCACAssIvt3DCSdCtMxLtRqst 9282;
BA_ "SPN" SG_ 2365302014 DCACAssIvt3DCSdVtMLtRqst 9281;
BA_ "SPN" SG_ 2365302014 DCACAssIvt3DCSdVtMxLtRqst 9541;
BA_ "SPN" SG_ 2365302270 DCACAssIvt3ACSdRMSCtMxLtRqst 9284;
BA_ "SPN" SG_ 2365302270 DCACAssIvt3ACSdRMSVtMxLtRqst 9283;
BA_ "SPN" SG_ 2365302270 DCACAssrInvrtr3ACSdDfltFrqnRqst 9525;
BA_ "SPN" SG_ 2365303294 DCACAssIvt4DCSdCtMLtRqst 9548;
BA_ "SPN" SG_ 2365303294 DCACAssIvt4DCSdCtMxLtRqst 9312;
BA_ "SPN" SG_ 2365303294 DCACAssIvt4DCSdVtMLtRqst 9311;
BA_ "SPN" SG_ 2365303294 DCACAssIvt4DCSdVtMxLtRqst 9547;
BA_ "SPN" SG_ 2365303550 DCACAssIvt4ACSdRMSCtMxLtRqst 9314;
BA_ "SPN" SG_ 2365303550 DCACAssIvt4ACSdRMSVtMxLtRqst 9313;
BA_ "SPN" SG_ 2365303550 DCACAssrInvrtr4ACSdDfltFrqnRqst 9526;
BA_ "SPN" SG_ 2365304574 DCACAssIvt5DCSdCtMLtRqst 9554;
BA_ "SPN" SG_ 2365304574 DCACAssIvt5DCSdCtMxLtRqst 9358;
BA_ "SPN" SG_ 2365304574 DCACAssIvt5DCSdVtMLtRqst 9357;
BA_ "SPN" SG_ 2365304574 DCACAssIvt5DCSdVtMxLtRqst 9553;
BA_ "SPN" SG_ 2365304830 DCACAssIvt5ACSdRMSCtMxLtRqst 9360;
BA_ "SPN" SG_ 2365304830 DCACAssIvt5ACSdRMSVtMxLtRqst 9359;
BA_ "SPN" SG_ 2365304830 DCACAssrInvrtr5ACSdDfltFrqnRqst 9527;
BA_ "SPN" SG_ 2365307646 DCDC4SLIBttrTmprtrMxmmLmtRqst 9045;
BA_ "SPN" SG_ 2365307646 DCDC4SLIBttTCCtMxLtRqst 9044;
BA_ "SPN" SG_ 2365307646 DCDC4SLIBttTVtMxLtRqst 9043;
BA_ "SPN" SG_ 2365307902 DCDC4CnvrtrEltrnFltrTmprtr 9047;
BA_ "SPN" SG_ 2365307902 DCDC4ConverterTemperature 9046;
BA_ "SPN" SG_ 2365307902 DCDC4CoolantInTemperature 9049;
BA_ "SPN" SG_ 2365307902 DCDC4CoolantOutTemperature 9050;
BA_ "SPN" SG_ 2365307902 DCDC4PwrEltrnsTmprtr 9048;
BA_ "SPN" SG_ 2365308158 DCDC4LwSdCrrntMxmmLmtRqst 9053;
BA_ "SPN" SG_ 2365308158 DCDC4LwSdVltgMnmmLmtRqst 9051;
BA_ "SPN" SG_ 2365308158 DCDC4LwSdVltgMxmmLmtRqst 9052;
BA_ "SPN" SG_ 2365308414 DCDC4HghSdCrrntMxmmLmtRqst 9056;
BA_ "SPN" SG_ 2365308414 DCDC4HghSdVltgMnmmLmtRqst 9054;
BA_ "SPN" SG_ 2365308414 DCDC4HghSdVltgMxmmLmtRqst 9055;
BA_ "SPN" SG_ 2365309182 DCDC3SLIBttrTmprtrMxmmLmtRqst 8990;
BA_ "SPN" SG_ 2365309182 DCDC3SLIBttTCCtMxLtRqst 8989;
BA_ "SPN" SG_ 2365309182 DCDC3SLIBttTVtMxLtRqst 8988;
BA_ "SPN" SG_ 2365309438 DCDC3CnvrtrEltrnFltrTmprtr 8992;
BA_ "SPN" SG_ 2365309438 DCDC3ConverterTemperature 8991;
BA_ "SPN" SG_ 2365309438 DCDC3CoolantInTemperature 8994;
BA_ "SPN" SG_ 2365309438 DCDC3CoolantOutTemperature 8995;
BA_ "SPN" SG_ 2365309438 DCDC3PwrEltrnsTmprtr 8993;
BA_ "SPN" SG_ 2365309694 DCDC3LwSdCrrntMxmmLmtRqst 8998;
BA_ "SPN" SG_ 2365309694 DCDC3LwSdVltgMnmmLmtRqst 8996;
BA_ "SPN" SG_ 2365309694 DCDC3LwSdVltgMxmmLmtRqst 8997;
BA_ "SPN" SG_ 2365309950 DCDC3HghSdCrrntMxmmLmtRqst 9001;
BA_ "SPN" SG_ 2365309950 DCDC3HghSdVltgMnmmLmtRqst 8999;
BA_ "SPN" SG_ 2365309950 DCDC3HghSdVltgMxmmLmtRqst 9000;
BA_ "SPN" SG_ 2365310718 DCDC2SLIBttrTmprtrMxmmLmtRqst 8935;
BA_ "SPN" SG_ 2365310718 DCDC2SLIBttTCCtMxLtRqst 8934;
BA_ "SPN" SG_ 2365310718 DCDC2SLIBttTVtMxLtRqst 8933;
BA_ "SPN" SG_ 2365310974 DCDC2CnvrtrEltrnFltrTmprtr 8937;
BA_ "SPN" SG_ 2365310974 DCDC2ConverterTemperature 8936;
BA_ "SPN" SG_ 2365310974 DCDC2CoolantInTemperature 8939;
BA_ "SPN" SG_ 2365310974 DCDC2CoolantOutTemperature 8940;
BA_ "SPN" SG_ 2365310974 DCDC2PwrEltrnsTmprtr 8938;
BA_ "SPN" SG_ 2365311230 DCDC2LwSdCrrntMxmmLmtRqst 8943;
BA_ "SPN" SG_ 2365311230 DCDC2LwSdVltgMnmmLmtRqst 8941;
BA_ "SPN" SG_ 2365311230 DCDC2LwSdVltgMxmmLmtRqst 8942;
BA_ "SPN" SG_ 2365311486 DCDC2HghSdCrrntMxmmLmtRqst 8946;
BA_ "SPN" SG_ 2365311486 DCDC2HghSdVltgMnmmLmtRqst 8944;
BA_ "SPN" SG_ 2365311486 DCDC2HghSdVltgMxmmLmtRqst 8945;
BA_ "SPN" SG_ 2365313534 DCDC1SLIBttrTmprtrMxmmLmtRqst 8819;
BA_ "SPN" SG_ 2365313534 DCDC1SLIBttTCCtMxLtRqst 8818;
BA_ "SPN" SG_ 2365313534 DCDC1SLIBttTVtMxLtRqst 8817;
BA_ "SPN" SG_ 2365315326 DCDC1CnvrtrEltrnFltrTmprtr 8593;
BA_ "SPN" SG_ 2365315326 DCDC1ConverterTemperature 8592;
BA_ "SPN" SG_ 2365315326 DCDC1CoolantInTemperature 8822;
BA_ "SPN" SG_ 2365315326 DCDC1CoolantOutTemperature 8823;
BA_ "SPN" SG_ 2365315326 DCDC1PwrEltrnsTmprtr 8594;
BA_ "SPN" SG_ 2365315582 DCDC1LwSdCrrntMxmmLmtRqst 8568;
BA_ "SPN" SG_ 2365315582 DCDC1LwSdVltgMnmmLmtRqst 8566;
BA_ "SPN" SG_ 2365315582 DCDC1LwSdVltgMxmmLmtRqst 8567;
BA_ "SPN" SG_ 2365315838 DCDC1HghSdCrrntMxmmLmtRqst 8565;
BA_ "SPN" SG_ 2365315838 DCDC1HghSdVltgMnmmLmtRqst 8563;
BA_ "SPN" SG_ 2365315838 DCDC1HghSdVltgMxmmLmtRqst 8564;
BA_ "SPN" SG_ 2365318910 HVESFanEnableCommand 8384;
BA_ "SPN" SG_ 2365318910 HVESFanInstance1 8388;
BA_ "SPN" SG_ 2365318910 HVESFanInstance10 8397;
BA_ "SPN" SG_ 2365318910 HVESFanInstance11 8398;
BA_ "SPN" SG_ 2365318910 HVESFanInstance12 8399;
BA_ "SPN" SG_ 2365318910 HVESFanInstance13 8400;
BA_ "SPN" SG_ 2365318910 HVESFanInstance14 8401;
BA_ "SPN" SG_ 2365318910 HVESFanInstance15 8402;
BA_ "SPN" SG_ 2365318910 HVESFanInstance2 8389;
BA_ "SPN" SG_ 2365318910 HVESFanInstance3 8390;
BA_ "SPN" SG_ 2365318910 HVESFanInstance4 8391;
BA_ "SPN" SG_ 2365318910 HVESFanInstance5 8392;
BA_ "SPN" SG_ 2365318910 HVESFanInstance6 8393;
BA_ "SPN" SG_ 2365318910 HVESFanInstance7 8394;
BA_ "SPN" SG_ 2365318910 HVESFanInstance8 8395;
BA_ "SPN" SG_ 2365318910 HVESFanInstance9 8396;
BA_ "SPN" SG_ 2365318910 HVESFanPercentSpeedCommand 8387;
BA_ "SPN" SG_ 2365318910 HVESFanPowerHold 8385;
BA_ "SPN" SG_ 2365318910 HVESFanSpeedCommand 8386;
BA_ "SPN" SG_ 2365322238 DirectionalVehicleSpeed 8166;
BA_ "SPN" SG_ 2365346302 LiftAxle1Status 6843;
BA_ "SPN" SG_ 2365346302 LiftAxle2Status 6844;
BA_ "SPN" SG_ 2365348350 EngineLoadShareStatus 6794;
BA_ "SPN" SG_ 2365348350 EngineUnloadStatus 6793;
BA_ "SPN" SG_ 2365363710 EngnClndrPrssrMntr1PrlmnrFMI 6390;
BA_ "SPN" SG_ 2365363710 EngnClndrPrssrMntr2PrlmnrFMI 6391;
BA_ "SPN" SG_ 2365374206 DlClthTrnsmssnCrrntPrsltnGr 5958;
BA_ "SPN" SG_ 2365374206 DlClthTrnsmssnInptShft1Spd 5960;
BA_ "SPN" SG_ 2365374206 DlClthTrnsmssnInptShft2Spd 5961;
BA_ "SPN" SG_ 2365374206 DlClthTrnsmssnSltdPrsltnGr 5957;
BA_ "SPN" SG_ 2365393662 Aftrtrtmnt2OtltCrrtdNOx 7352;
BA_ "SPN" SG_ 2365393662 Aftrtrtmnt2OtltNOxSnsrNH3Crrtn 5051;
BA_ "SPN" SG_ 2365393662 Aftrtrtmnt2OtltNOxSnsrNO2Crrtn 5050;
BA_ "SPN" SG_ 2365393662 Atttt2OttNOxSsNOxPssCt 5049;
BA_ "SPN" SG_ 2365393662 Atttt2OttNOxSsO2PssCt 5048;
BA_ "SPN" SG_ 2365393662 Atttt2OttNOxSsSdssFRst 5719;
BA_ "SPN" SG_ 2365393918 Aftrtrtmnt2OtltNOxSnsrHtrRt 5045;
BA_ "SPN" SG_ 2365393918 Aftrtrtmnt2OtltNOxSnsrOprtnHrs 5723;
BA_ "SPN" SG_ 2365393918 Atttt2OttNOxSsNwptdvtNOxG 5046;
BA_ "SPN" SG_ 2365393918 Atttt2OttNOxSsNwptdvtNOxOst 5047;
BA_ "SPN" SG_ 2365394174 EExst2ItNOxSsNOxPssCt 5042;
BA_ "SPN" SG_ 2365394174 EExst2ItNOxSsO2PssCt 5041;
BA_ "SPN" SG_ 2365394174 EExst2ItNOxSsSdssFRst 5720;
BA_ "SPN" SG_ 2365394174 EngineExhaust2CorrectedNox 7354;
BA_ "SPN" SG_ 2365394174 EngnExhst2IntkNOxSnsrNH3Crrtn 5044;
BA_ "SPN" SG_ 2365394174 EngnExhst2IntkNOxSnsrNO2Crrtn 5043;
BA_ "SPN" SG_ 2365394430 EExst2ItNOxSsNwptdvtNOxG 5039;
BA_ "SPN" SG_ 2365394430 EExst2ItNOxSsNwptdvtNOxOst 5040;
BA_ "SPN" SG_ 2365394430 EngnExhst2IntkNOxSnsrHtrRt 5038;
BA_ "SPN" SG_ 2365394430 EngnExhst2IntkNOxSnsrOprtnHrs 5724;
BA_ "SPN" SG_ 2365394686 Aftrtrtmnt1OtltCrrtdNOx 7351;
BA_ "SPN" SG_ 2365394686 Aftrtrtmnt1OtltNOxSnsrNH3Crrtn 5037;
BA_ "SPN" SG_ 2365394686 Aftrtrtmnt1OtltNOxSnsrNO2Crrtn 5036;
BA_ "SPN" SG_ 2365394686 Atttt1OttNOxSsNOxPssCt 5035;
BA_ "SPN" SG_ 2365394686 Atttt1OttNOxSsO2PssCt 5034;
BA_ "SPN" SG_ 2365394686 Atttt1OttNOxSsSdssFRst 5717;
BA_ "SPN" SG_ 2365394942 Aftrtrtmnt1OtltNOxSnsrHtrRt 5031;
BA_ "SPN" SG_ 2365394942 Aftrtrtmnt1OtltNOxSnsrOprtnHrs 5721;
BA_ "SPN" SG_ 2365394942 Atttt1OttNOxSsNwptdvtNOxG 5032;
BA_ "SPN" SG_ 2365394942 Atttt1OttNOxSsNwptdvtNOxOst 5033;
BA_ "SPN" SG_ 2365395198 EExst1NOxSsSdssFRst 5718;
BA_ "SPN" SG_ 2365395198 EngineExhaust1CorrectedNox 7353;
BA_ "SPN" SG_ 2365395198 EngnExhst1NOxSnsrNH3Crrtn 5030;
BA_ "SPN" SG_ 2365395198 EngnExhst1NOxSnsrNO2Crrtn 5029;
BA_ "SPN" SG_ 2365395198 EngnExhst1NOxSnsrNOxPrssrCrrtn 5028;
BA_ "SPN" SG_ 2365395198 EngnExhst1NOxSnsrO2PrssrCrrtn 5027;
BA_ "SPN" SG_ 2365395454 EExst1NOxSsNwptdvtNOxOst 5026;
BA_ "SPN" SG_ 2365395454 EngnExhst1NOxSnsrHtrRt 5024;
BA_ "SPN" SG_ 2365395454 EngnExhst1NOxSnsrNwprtdvtnNOxGn 5025;
BA_ "SPN" SG_ 2365395454 EngnExhst1NOxSnsrOprtnHrs 5722;
BA_ "SPN" SG_ 2365400062 Joystick10Button13PressedStatus 6767;
BA_ "SPN" SG_ 2365400062 Joystick10Button14PressedStatus 6768;
BA_ "SPN" SG_ 2365400062 Joystick10Button15PressedStatus 6769;
BA_ "SPN" SG_ 2365400062 Joystick10Button16PressedStatus 6770;
BA_ "SPN" SG_ 2365400062 Joystick10GripXAxisPosition 4738;
BA_ "SPN" SG_ 2365400062 Joystick10GripYAxisPosition 4742;
BA_ "SPN" SG_ 2365400062 Joystick10ThetaAxisPosition 4746;
BA_ "SPN" SG_ 2365400062 Jst10GpXAxsLvRtPstvPstStts 4737;
BA_ "SPN" SG_ 2365400062 Jst10GpYAxsLvFwdPstvPstStts 4741;
BA_ "SPN" SG_ 2365400062 Jst10TtAxsCtCwsNtvPstStts 4744;
BA_ "SPN" SG_ 2365400062 Jstk10GrpXAxsDtntPstnStts 4749;
BA_ "SPN" SG_ 2365400062 Jstk10GrpXAxsLvrLftNgtvPstnStts 4736;
BA_ "SPN" SG_ 2365400062 Jstk10GrpXAxsNtrlPstnStts 4735;
BA_ "SPN" SG_ 2365400062 Jstk10GrpYAxsDtntPstnStts 4748;
BA_ "SPN" SG_ 2365400062 Jstk10GrpYAxsLvrBkNgtvPstnStts 4740;
BA_ "SPN" SG_ 2365400062 Jstk10GrpYAxsNtrlPstnStts 4739;
BA_ "SPN" SG_ 2365400062 Jstk10ThtAxsClkwsPstvPstnStts 4745;
BA_ "SPN" SG_ 2365400062 Jstk10ThtAxsDtntPstnStts 4747;
BA_ "SPN" SG_ 2365400062 Jstk10ThtAxsNtrlPstnStts 4743;
BA_ "SPN" SG_ 2365400318 Joystick10Button10PressedStatus 4733;
BA_ "SPN" SG_ 2365400318 Joystick10Button11PressedStatus 4732;
BA_ "SPN" SG_ 2365400318 Joystick10Button12PressedStatus 4731;
BA_ "SPN" SG_ 2365400318 Joystick10Button1PressedStatus 4726;
BA_ "SPN" SG_ 2365400318 Joystick10Button2PressedStatus 4725;
BA_ "SPN" SG_ 2365400318 Joystick10Button3PressedStatus 4724;
BA_ "SPN" SG_ 2365400318 Joystick10Button4PressedStatus 4723;
BA_ "SPN" SG_ 2365400318 Joystick10Button5PressedStatus 4730;
BA_ "SPN" SG_ 2365400318 Joystick10Button6PressedStatus 4729;
BA_ "SPN" SG_ 2365400318 Joystick10Button7PressedStatus 4728;
BA_ "SPN" SG_ 2365400318 Joystick10Button8PressedStatus 4727;
BA_ "SPN" SG_ 2365400318 Joystick10Button9PressedStatus 4734;
BA_ "SPN" SG_ 2365400318 Joystick10XAxisPosition 4716;
BA_ "SPN" SG_ 2365400318 Joystick10YAxisPosition 4720;
BA_ "SPN" SG_ 2365400318 Jstk10XAxsDtntPstnStts 4722;
BA_ "SPN" SG_ 2365400318 Jstk10XAxsLvrLftNgtvPstnStts 4714;
BA_ "SPN" SG_ 2365400318 Jstk10XAxsLvrRghtPstvPstnStts 4715;
BA_ "SPN" SG_ 2365400318 Jstk10XAxsNtrlPstnStts 4713;
BA_ "SPN" SG_ 2365400318 Jstk10YAxsDtntPstnStts 4721;
BA_ "SPN" SG_ 2365400318 Jstk10YAxsLvrBkNgtvPstnStts 4718;
BA_ "SPN" SG_ 2365400318 Jstk10YAxsLvrFrwrdPstvPstnStts 4719;
BA_ "SPN" SG_ 2365400318 Jstk10YAxsNtrlPstnStts 4717;
BA_ "SPN" SG_ 2365400574 Joystick9Button13PressedStatus 6763;
BA_ "SPN" SG_ 2365400574 Joystick9Button14PressedStatus 6764;
BA_ "SPN" SG_ 2365400574 Joystick9Button15PressedStatus 6765;
BA_ "SPN" SG_ 2365400574 Joystick9Button16PressedStatus 6766;
BA_ "SPN" SG_ 2365400574 Joystick9GripXAxisPosition 4701;
BA_ "SPN" SG_ 2365400574 Joystick9GripYAxisPosition 4705;
BA_ "SPN" SG_ 2365400574 Joystick9ThetaAxisPosition 4709;
BA_ "SPN" SG_ 2365400574 Jst9GpYAxsLvFwdPstvPstStts 4704;
BA_ "SPN" SG_ 2365400574 Jst9TtAxsCtCwsNtvPstStts 4707;
BA_ "SPN" SG_ 2365400574 Jstk9GrpXAxsDtntPstnStts 4712;
BA_ "SPN" SG_ 2365400574 Jstk9GrpXAxsLvrLftNgtvPstnStts 4699;
BA_ "SPN" SG_ 2365400574 Jstk9GrpXAxsLvrRghtPstvPstnStts 4700;
BA_ "SPN" SG_ 2365400574 Jstk9GrpXAxsNtrlPstnStts 4698;
BA_ "SPN" SG_ 2365400574 Jstk9GrpYAxsDtntPstnStts 4711;
BA_ "SPN" SG_ 2365400574 Jstk9GrpYAxsLvrBkNgtvPstnStts 4703;
BA_ "SPN" SG_ 2365400574 Jstk9GrpYAxsNtrlPstnStts 4702;
BA_ "SPN" SG_ 2365400574 Jstk9ThtAxsClkwsPstvPstnStts 4708;
BA_ "SPN" SG_ 2365400574 Jstk9ThtAxsDtntPstnStts 4710;
BA_ "SPN" SG_ 2365400574 Jstk9ThtAxsNtrlPstnStts 4706;
BA_ "SPN" SG_ 2365400830 Joystick9Button10PressedStatus 4696;
BA_ "SPN" SG_ 2365400830 Joystick9Button11PressedStatus 4695;
BA_ "SPN" SG_ 2365400830 Joystick9Button12PressedStatus 4694;
BA_ "SPN" SG_ 2365400830 Joystick9Button1PressedStatus 4689;
BA_ "SPN" SG_ 2365400830 Joystick9Button2PressedStatus 4688;
BA_ "SPN" SG_ 2365400830 Joystick9Button3PressedStatus 4687;
BA_ "SPN" SG_ 2365400830 Joystick9Button4PressedStatus 4686;
BA_ "SPN" SG_ 2365400830 Joystick9Button5PressedStatus 4693;
BA_ "SPN" SG_ 2365400830 Joystick9Button6PressedStatus 4692;
BA_ "SPN" SG_ 2365400830 Joystick9Button7PressedStatus 4691;
BA_ "SPN" SG_ 2365400830 Joystick9Button8PressedStatus 4690;
BA_ "SPN" SG_ 2365400830 Joystick9Button9PressedStatus 4697;
BA_ "SPN" SG_ 2365400830 Joystick9XAxisPosition 4679;
BA_ "SPN" SG_ 2365400830 Joystick9YAxisPosition 4683;
BA_ "SPN" SG_ 2365400830 Jstk9XAxsDtntPstnStts 4685;
BA_ "SPN" SG_ 2365400830 Jstk9XAxsLvrLftNgtvPstnStts 4677;
BA_ "SPN" SG_ 2365400830 Jstk9XAxsLvrRghtPstvPstnStts 4678;
BA_ "SPN" SG_ 2365400830 Jstk9XAxsNtrlPstnStts 4676;
BA_ "SPN" SG_ 2365400830 Jstk9YAxsDtntPstnStts 4684;
BA_ "SPN" SG_ 2365400830 Jstk9YAxsLvrBkNgtvPstnStts 4681;
BA_ "SPN" SG_ 2365400830 Jstk9YAxsLvrFrwrdPstvPstnStts 4682;
BA_ "SPN" SG_ 2365400830 Jstk9YAxsNtrlPstnStts 4680;
BA_ "SPN" SG_ 2365401086 Joystick8Button13PressedStatus 6759;
BA_ "SPN" SG_ 2365401086 Joystick8Button14PressedStatus 6760;
BA_ "SPN" SG_ 2365401086 Joystick8Button15PressedStatus 6761;
BA_ "SPN" SG_ 2365401086 Joystick8Button16PressedStatus 6762;
BA_ "SPN" SG_ 2365401086 Joystick8GripXAxisPosition 4664;
BA_ "SPN" SG_ 2365401086 Joystick8GripYAxisPosition 4668;
BA_ "SPN" SG_ 2365401086 Joystick8ThetaAxisPosition 4672;
BA_ "SPN" SG_ 2365401086 Jst8GpYAxsLvFwdPstvPstStts 4667;
BA_ "SPN" SG_ 2365401086 Jst8TtAxsCtCwsNtvPstStts 4670;
BA_ "SPN" SG_ 2365401086 Jstk8GrpXAxsDtntPstnStts 4675;
BA_ "SPN" SG_ 2365401086 Jstk8GrpXAxsLvrLftNgtvPstnStts 4662;
BA_ "SPN" SG_ 2365401086 Jstk8GrpXAxsLvrRghtPstvPstnStts 4663;
BA_ "SPN" SG_ 2365401086 Jstk8GrpXAxsNtrlPstnStts 4661;
BA_ "SPN" SG_ 2365401086 Jstk8GrpYAxsDtntPstnStts 4674;
BA_ "SPN" SG_ 2365401086 Jstk8GrpYAxsLvrBkNgtvPstnStts 4666;
BA_ "SPN" SG_ 2365401086 Jstk8GrpYAxsNtrlPstnStts 4665;
BA_ "SPN" SG_ 2365401086 Jstk8ThtAxsClkwsPstvPstnStts 4671;
BA_ "SPN" SG_ 2365401086 Jstk8ThtAxsDtntPstnStts 4673;
BA_ "SPN" SG_ 2365401086 Jstk8ThtAxsNtrlPstnStts 4669;
BA_ "SPN" SG_ 2365401342 Joystick8Button10PressedStatus 4659;
BA_ "SPN" SG_ 2365401342 Joystick8Button11PressedStatus 4658;
BA_ "SPN" SG_ 2365401342 Joystick8Button12PressedStatus 4657;
BA_ "SPN" SG_ 2365401342 Joystick8Button1PressedStatus 4652;
BA_ "SPN" SG_ 2365401342 Joystick8Button2PressedStatus 4651;
BA_ "SPN" SG_ 2365401342 Joystick8Button3PressedStatus 4650;
BA_ "SPN" SG_ 2365401342 Joystick8Button4PressedStatus 4649;
BA_ "SPN" SG_ 2365401342 Joystick8Button5PressedStatus 4656;
BA_ "SPN" SG_ 2365401342 Joystick8Button6PressedStatus 4655;
BA_ "SPN" SG_ 2365401342 Joystick8Button7PressedStatus 4654;
BA_ "SPN" SG_ 2365401342 Joystick8Button8PressedStatus 4653;
BA_ "SPN" SG_ 2365401342 Joystick8Button9PressedStatus 4660;
BA_ "SPN" SG_ 2365401342 Joystick8XAxisPosition 4642;
BA_ "SPN" SG_ 2365401342 Joystick8YAxisPosition 4646;
BA_ "SPN" SG_ 2365401342 Jstk8XAxsDtntPstnStts 4648;
BA_ "SPN" SG_ 2365401342 Jstk8XAxsLvrLftNgtvPstnStts 4640;
BA_ "SPN" SG_ 2365401342 Jstk8XAxsLvrRghtPstvPstnStts 4641;
BA_ "SPN" SG_ 2365401342 Jstk8XAxsNtrlPstnStts 4639;
BA_ "SPN" SG_ 2365401342 Jstk8YAxsDtntPstnStts 4647;
BA_ "SPN" SG_ 2365401342 Jstk8YAxsLvrBkNgtvPstnStts 4644;
BA_ "SPN" SG_ 2365401342 Jstk8YAxsLvrFrwrdPstvPstnStts 4645;
BA_ "SPN" SG_ 2365401342 Jstk8YAxsNtrlPstnStts 4643;
